VERSION ""

NS_ :

BS_:

BU_: TBox

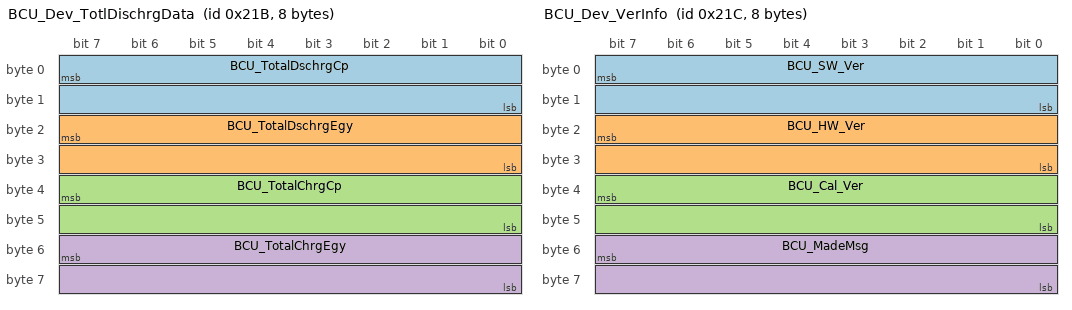
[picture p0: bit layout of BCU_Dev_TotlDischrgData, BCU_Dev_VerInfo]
BO_ 539 BCU_Dev_TotlDischrgData: 8 CGW
 SG_ BCU_TotalDschrgCp : 7|16@0+ (1,0) [0|65000] "" TBox
 SG_ BCU_TotalDschrgEgy : 23|16@0+ (1,0) [0|65000] "" TBox
 SG_ BCU_TotalChrgCp : 39|16@0+ (1,0) [0|65000] "" TBox
 SG_ BCU_TotalChrgEgy : 55|16@0+ (1,0) [0|65000] "" TBox

BO_ 540 BCU_Dev_VerInfo: 8 CGW
 SG_ BCU_SW_Ver : 7|16@0+ (1,0) [0|65535] "" TBox
 SG_ BCU_HW_Ver : 23|16@0+ (1,0) [0|65535] "" TBox
 SG_ BCU_Cal_Ver : 39|16@0+ (1,0) [0|65535] "" TBox
 SG_ BCU_MadeMsg : 55|16@0+ (1,0) [0|65535] "" TBox

BO_ 545 BCU_Extrm_RM: 8 CGW
 SG_ BCU_BattCellTotalNr_RM : 7|8@0+ (1,0) [0|160] "" TBox
 SG_ BCU_TmpProbeQuantity_RM : 15|8@0+ (1,0) [0|160] "" TBox
 SG_ BCU_BalnFlg023_RM : 16|1@0+ (1,0) [0|1] "" TBox
 SG_ BCU_BalnFlg024_RM : 17|1@0+ (1,0) [0|1] "" TBox
 SG_ BCU_BalnFlg025_RM : 18|1@0+ (1,0) [0|1] "" TBox
 SG_ BCU_BalnFlg026_RM : 19|1@0+ (1,0) [0|1] "" TBox
 SG_ BCU_BalnFlg027_RM : 20|1@0+ (1,0) [0|1] "" TBox
 SG_ BCU_BalnFlg028_RM : 21|1@0+ (1,0) [0|1] "" TBox
 SG_ BCU_BalnFlg029_RM : 22|1@0+ (1,0) [0|1] "" TBox
 SG_ BCU_BalnFlg030_RM : 23|1@0+ (1,0) [0|1] "" TBox
 SG_ BCU_BalnFlg031_RM : 24|1@0+ (1,0) [0|1] "" TBox
 SG_ BCU_BalnFlg032_RM : 25|1@0+ (1,0) [0|1] "" TBox
 SG_ BCU_BalnFlg033_RM : 26|1@0+ (1,0) [0|1] "" TBox
 SG_ BCU_BalnFlg034_RM : 27|1@0+ (1,0) [0|1] "" TBox
 SG_ BCU_BalnFlg035_RM : 28|1@0+ (1,0) [0|1] "" TBox
 SG_ BCU_BalnFlg036_RM : 29|1@0+ (1,0) [0|1] "" TBox
 SG_ BCU_BalnFlg037_RM : 30|1@0+ (1,0) [0|1] "" TBox
 SG_ BCU_BalnFlg038_RM : 31|1@0+ (1,0) [0|1] "" TBox
 SG_ BCU_BalnFlg039_RM : 32|1@0+ (1,0) [0|1] "" TBox
 SG_ BCU_BalnFlg040_RM : 33|1@0+ (1,0) [0|1] "" TBox
 SG_ BCU_BalnFlg041_RM : 34|1@0+ (1,0) [0|1] "" TBox
 SG_ BCU_BalnFlg042_RM : 35|1@0+ (1,0) [0|1] "" TBox
 SG_ BCU_BalnFlg043_RM : 36|1@0+ (1,0) [0|1] "" TBox
 SG_ BCU_BalnFlg044_RM : 37|1@0+ (1,0) [0|1] "" TBox
 SG_ BCU_BalnFlg045_RM : 38|1@0+ (1,0) [0|1] "" TBox
 SG_ BCU_BalnFlg046_RM : 39|1@0+ (1,0) [0|1] "" TBox
 SG_ BCU_BalnFlg047_RM : 40|1@0+ (1,0) [0|1] "" TBox
 SG_ BCU_BalnFlg048_RM : 41|1@0+ (1,0) [0|1] "" TBox
 SG_ BCU_BalnFlg049_RM : 42|1@0+ (1,0) [0|1] "" TBox
 SG_ BCU_BalnFlg050_RM : 43|1@0+ (1,0) [0|1] "" TBox
 SG_ BCU_BalnFlg051_RM : 44|1@0+ (1,0) [0|1] "" TBox
 SG_ BCU_BalnFlg052_RM : 45|1@0+ (1,0) [0|1] "" TBox
 SG_ BCU_BalnFlg053_RM : 46|1@0+ (1,0) [0|1] "" TBox
 SG_ BCU_BalnFlg054_RM : 47|1@0+ (1,0) [0|1] "" TBox
 SG_ BCU_BalnFlg055_RM : 48|1@0+ (1,0) [0|1] "" TBox
 SG_ BCU_BalnFlg056_RM : 49|1@0+ (1,0) [0|1] "" TBox
 SG_ BCU_BalnFlg057_RM : 50|1@0+ (1,0) [0|1] "" TBox
 SG_ BCU_BalnFlg058_RM : 51|1@0+ (1,0) [0|1] "" TBox
 SG_ BCU_BalnFlg059_RM : 52|1@0+ (1,0) [0|1] "" TBox
 SG_ BCU_BalnFlg060_RM : 53|1@0+ (1,0) [0|1] "" TBox
 SG_ BCU_BalnFlg061_RM : 54|1@0+ (1,0) [0|1] "" TBox
 SG_ BCU_BalnFlg062_RM : 55|1@0+ (1,0) [0|1] "" TBox
 SG_ BCU_BalnFlg063_RM : 56|1@0+ (1,0) [0|1] "" TBox
 SG_ BCU_BalnFlg064_RM : 57|1@0+ (1,0) [0|1] "" TBox
 SG_ BCU_BalnFlg065_RM : 58|1@0+ (1,0) [0|1] "" TBox
 SG_ BCU_BalnFlg066_RM : 59|1@0+ (1,0) [0|1] "" TBox
 SG_ BCU_BalnFlg067_RM : 60|1@0+ (1,0) [0|1] "" TBox
 SG_ BCU_BalnFlg068_RM : 61|1@0+ (1,0) [0|1] "" TBox
 SG_ BCU_BalnFlg069_RM : 62|1@0+ (1,0) [0|1] "" TBox
 SG_ BCU_BalnFlg070_RM : 63|1@0+ (1,0) [0|1] "" TBox

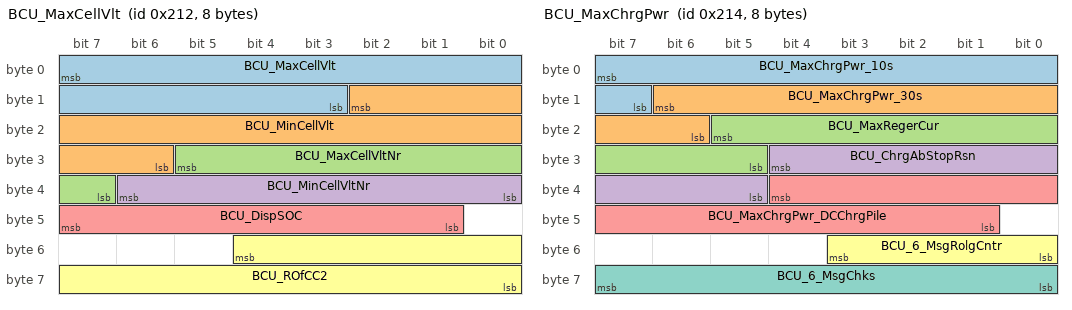
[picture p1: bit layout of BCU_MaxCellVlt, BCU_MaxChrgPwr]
BO_ 530 BCU_MaxCellVlt: 8 CGW
 SG_ BCU_MaxCellVlt : 7|13@0+ (0.001,0) [0|5] "V" TBox
 SG_ BCU_MinCellVlt : 10|13@0+ (0.001,0) [0|5] "V" TBox
 SG_ BCU_MaxCellVltNr : 29|7@0+ (1,0) [0|120] "" TBox
 SG_ BCU_MinCellVltNr : 38|7@0+ (1,0) [0|120] "" TBox
 SG_ BCU_DispSOC : 47|7@0+ (1,0) [0|100] "%" TBox
 SG_ BCU_ROfCC2 : 52|13@0+ (1,0) [0|8191] "Ω" TBox

BO_ 532 BCU_MaxChrgPwr: 8 CGW
 SG_ BCU_MaxChrgPwr_10s : 7|9@0+ (0.5,0) [0|255] "kw" TBox
 SG_ BCU_MaxChrgPwr_30s : 14|9@0+ (0.5,0) [0|255] "kw" TBox
 SG_ BCU_MaxRegerCur : 21|9@0+ (1,0) [0|500] "A" TBox
 SG_ BCU_ChrgAbStopRsn : 28|8@0+ (1,0) [0|255] "" TBox
 SG_ BCU_MaxChrgPwr_DCChrgPile : 36|12@0+ (0.1,0) [0|300] "Kw" TBox
 SG_ BCU_6_MsgRolgCntr : 51|4@0+ (1,0) [0|15] "" TBox
 SG_ BCU_6_MsgChks : 63|8@0+ (1,0) [0|255] "" TBox

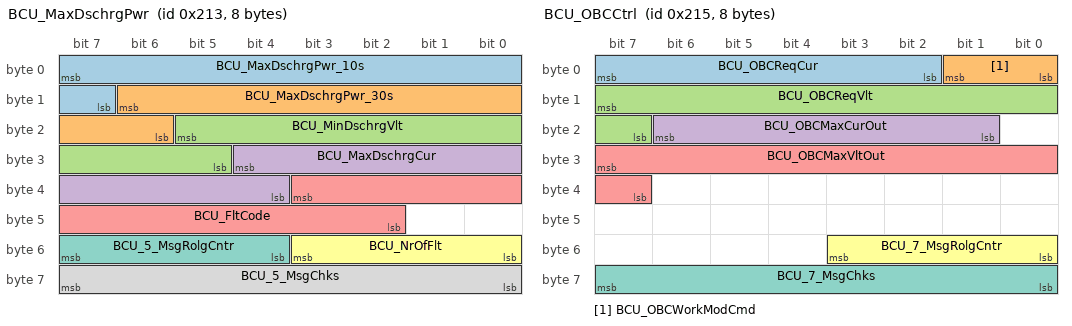
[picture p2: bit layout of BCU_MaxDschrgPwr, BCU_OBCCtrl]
BO_ 531 BCU_MaxDschrgPwr: 8 CGW
 SG_ BCU_MaxDschrgPwr_10s : 7|9@0+ (0.5,0) [0|255] "kw" TBox
 SG_ BCU_MaxDschrgPwr_30s : 14|9@0+ (0.5,0) [0|255] "kw" TBox
 SG_ BCU_MinDschrgVlt : 21|9@0+ (1,0) [0|500] "V" TBox
 SG_ BCU_MaxDschrgCur : 28|9@0+ (1,0) [0|500] "A" TBox
 SG_ BCU_FltCode : 35|10@0+ (1,0) [0|1023] "" TBox
 SG_ BCU_NrOfFlt : 51|4@0+ (1,0) [0|15] "" TBox
 SG_ BCU_5_MsgRolgCntr : 55|4@0+ (1,0) [0|15] "" TBox
 SG_ BCU_5_MsgChks : 63|8@0+ (1,0) [0|255] "" TBox

BO_ 533 BCU_OBCCtrl: 8 CGW
 SG_ BCU_OBCReqCur : 7|6@0+ (1,0) [0|50] "A" TBox
 SG_ BCU_OBCWorkModCmd : 1|2@0+ (1,0) [0|3] "" TBox
 SG_ BCU_OBCReqVlt : 15|9@0+ (1,0) [0|500] "V" TBox
 SG_ BCU_OBCMaxCurOut : 22|6@0+ (1,0) [0|50] "A" TBox
 SG_ BCU_OBCMaxVltOut : 31|9@0+ (1,0) [0|500] "V" TBox
 SG_ BCU_7_MsgRolgCntr : 51|4@0+ (1,0) [0|15] "" TBox
 SG_ BCU_7_MsgChks : 63|8@0+ (1,0) [0|255] "" TBox

BO_ 538 BCU_SglChrgData: 8 CGW
 SG_ BCU_AllCellNr : 7|7@0+ (1,0) [0|120] "" TBox
 SG_ BCU_SglChrgCp : 0|12@0+ (1,0) [0|4000] "" TBox
 SG_ BCU_SglChrgEgy : 20|10@0+ (1,0) [0|1000] "" TBox
 SG_ BCU_SglDschrgCp : 26|12@0+ (1,0) [0|4000] "" TBox
 SG_ BCU_SglDschrgEgy : 46|10@0+ (1,0) [0|1000] "" TBox
 SG_ BCU_BalnFlg001_RM : 52|1@0+ (1,0) [0|1] "" TBox
 SG_ BCU_BalnFlg002_RM : 51|1@0+ (1,0) [0|1] "" TBox
 SG_ BCU_BalnFlg003_RM : 50|1@0+ (1,0) [0|1] "" TBox
 SG_ BCU_BalnFlg004_RM : 49|1@0+ (1,0) [0|1] "" TBox
 SG_ BCU_BalnFlg005_RM : 48|1@0+ (1,0) [0|1] "" TBox
 SG_ BCU_BalnFlg006_RM : 56|1@0+ (1,0) [0|1] "" TBox
 SG_ BCU_BalnFlg007_RM : 57|1@0+ (1,0) [0|1] "" TBox
 SG_ BCU_BalnFlg008_RM : 58|1@0+ (1,0) [0|1] "" TBox
 SG_ BCU_BalnFlg009_RM : 59|1@0+ (1,0) [0|1] "" TBox
 SG_ BCU_BalnFlg010_RM : 60|1@0+ (1,0) [0|1] "" TBox
 SG_ BCU_BalnFlg011_RM : 61|1@0+ (1,0) [0|1] "" TBox
 SG_ BCU_BalnFlg012_RM : 62|1@0+ (1,0) [0|1] "" TBox
 SG_ BCU_BalnFlg013_RM : 63|1@0+ (1,0) [0|1] "" TBox

BO_ 544 BCU_VhclStsExtrm_RM: 8 CGW
 SG_ BCU_IsoR_RM : 7|13@0+ (1,0) [0|8191] "KΩ" TBox
 SG_ BCU_MaxVltBatt_SubSysNr_RM : 10|2@0+ (1,0) [0|3] "" TBox

CM_ SG_ 530 BCU_MaxCellVlt "Max Cell Voltage
最高单体电压";
CM_ SG_ 530 BCU_MinCellVlt "Min Cell Voltage
最低单体电压";
CM_ SG_ 530 BCU_MaxCellVltNr "Max cell voltage number
最高单体电压编号";
CM_ SG_ 530 BCU_MinCellVltNr "Min cell voltage number
最低单体电压编号";
CM_ SG_ 530 BCU_DispSOC "Display SOC
显示的SOC";
CM_ SG_ 530 BCU_ROfCC2 "Resistance of CC2
CC2 电阻";
CM_ SG_ 531 BCU_MaxDschrgPwr_10s "Battery Max Discharge Power During Next 10s
电池10s最大放电功率";
CM_ SG_ 531 BCU_MaxDschrgPwr_30s "Battery Max Discharge  Power During Next 30s
电池30s最大放电功率";
CM_ SG_ 531 BCU_MinDschrgVlt "Battery Min Discharge Voltage
电池最小放电电压";
CM_ SG_ 531 BCU_MaxDschrgCur "Battery Max Discharge Current
电池最大放电电流";
CM_ SG_ 531 BCU_FltCode "Fault Code
故障代码";
CM_ SG_ 531 BCU_NrOfFlt "Number Of Fault
故障数量";
CM_ SG_ 531 BCU_5_MsgRolgCntr "MessageRollingCounter is from 0   
to 15 ,increase one unit on every message transmission
报文计数器";
CM_ SG_ 531 BCU_5_MsgChks "初始值0xFF
异或值0xFF
多项式0x2F
Function : calculate rule
crc = 0xFF;                            // initial value = 0xFF
for( byte_index=0; byte_index<cb_DATA_BYTE_SIZE;    ++byte_index )
{
crc ^= data_byte_array[byte_index];
for( bit_index=0; bit_index<8; ++bit_index )
{
if( (crc & 0x80) != 0 )
crc = (crc << 1) ^ cb_CRC_POLY;
else
crc = (crc << 1);
}
}
return crc= crc ^ 0FF;                            //return inverse value";
CM_ SG_ 532 BCU_MaxChrgPwr_10s "Battery Max Charge Power During Next 10s
电池在接下来10s的最大充电功率";
CM_ SG_ 532 BCU_MaxChrgPwr_30s "Battery Max Charge Power During Next 30s
电池在接下来30s的最大充电功率";
CM_ SG_ 532 BCU_MaxRegerCur "Battery Max Regeneration Current
电池最大回馈电流";
CM_ SG_ 532 BCU_ChrgAbStopRsn "Charge Abnormal Stop Reason 
充电异常停止原因";
CM_ SG_ 532 BCU_MaxChrgPwr_DCChrgPile "Maximum Charging Power of DC Charging Pile
(直流充电时)直流充电桩最大充电功率";
CM_ SG_ 532 BCU_6_MsgRolgCntr "MessageRollingCounter is from 0   
to 15 ,increase one unit on every message transmission
报文计数器";
CM_ SG_ 532 BCU_6_MsgChks "初始值0xFF
异或值0xFF
多项式0x2F
Function : calculate rule
crc = 0xFF;                            // initial value = 0xFF
for( byte_index=0; byte_index<cb_DATA_BYTE_SIZE;    ++byte_index )
{
crc ^= data_byte_array[byte_index];
for( bit_index=0; bit_index<8; ++bit_index )
{
if( (crc & 0x80) != 0 )
crc = (crc << 1) ^ cb_CRC_POLY;
else
crc = (crc << 1);
}
}
return crc= crc ^ 0FF;                            //return inverse value";
CM_ SG_ 533 BCU_OBCReqCur "OBC Request Current
OBC充电请求电流";
CM_ SG_ 533 BCU_OBCWorkModCmd "OBC Work Mode Command
OBC工作模式指令";
CM_ SG_ 533 BCU_OBCReqVlt "OBC Request Voltage
OBC充电请求电压";
CM_ SG_ 533 BCU_OBCMaxCurOut "OBC Max Output Current Limited
OBC输出电流限值";
CM_ SG_ 533 BCU_OBCMaxVltOut "OBC Max Output  Voltage Limited
OBC输出电压限值";
CM_ SG_ 533 BCU_7_MsgRolgCntr "MessageRollingCounter is from 0   
to 15 ,increase one unit on every message transmission
报文计数器";
CM_ SG_ 533 BCU_7_MsgChks "初始值0xFF
异或值0xFF
多项式0x2F
Function : calculate rule
crc = 0xFF;                            // initial value = 0xFF
for( byte_index=0; byte_index<cb_DATA_BYTE_SIZE;    ++byte_index )
{
crc ^= data_byte_array[byte_index];
for( bit_index=0; bit_index<8; ++bit_index )
{
if( (crc & 0x80) != 0 )
crc = (crc << 1) ^ cb_CRC_POLY;
else
crc = (crc << 1);
}
}
return crc= crc ^ 0FF;                            //return inverse value";
CM_ SG_ 538 BCU_AllCellNr "All Cell Number
电池单体编号";
CM_ SG_ 538 BCU_SglChrgCp "Single Charge Capacity
单次外插充电容量";
CM_ SG_ 538 BCU_SglChrgEgy "Single Charge Energy
单次外插充电能量";
CM_ SG_ 538 BCU_SglDschrgCp "Singl Discharge Capacity
单次放电容量";
CM_ SG_ 538 BCU_SglDschrgEgy "Single Discharge Energy
单次放电能量";
CM_ SG_ 538 BCU_BalnFlg001_RM "Cell Balance Flag
单体均衡标志位001";
CM_ SG_ 538 BCU_BalnFlg002_RM "Cell Balance Flag
单体均衡标志位002";
CM_ SG_ 538 BCU_BalnFlg003_RM "Cell Balance Flag
单体均衡标志位003";
CM_ SG_ 538 BCU_BalnFlg004_RM "Cell Balance Flag
单体均衡标志位004";
CM_ SG_ 538 BCU_BalnFlg005_RM "Cell Balance Flag
单体均衡标志位005";
CM_ SG_ 538 BCU_BalnFlg006_RM "Cell Balance Flag
单体均衡标志位006";
CM_ SG_ 538 BCU_BalnFlg007_RM "Cell Balance Flag
单体均衡标志位007";
CM_ SG_ 538 BCU_BalnFlg008_RM "Cell Balance Flag
单体均衡标志位008";
CM_ SG_ 538 BCU_BalnFlg009_RM "Cell Balance Flag
单体均衡标志位009";
CM_ SG_ 538 BCU_BalnFlg010_RM "Cell Balance Flag
单体均衡标志位010";
CM_ SG_ 538 BCU_BalnFlg011_RM "Cell Balance Flag
单体均衡标志位011";
CM_ SG_ 538 BCU_BalnFlg012_RM "Cell Balance Flag
单体均衡标志位012";
CM_ SG_ 538 BCU_BalnFlg013_RM "Cell Balance Flag
单体均衡标志位013";
CM_ SG_ 539 BCU_TotalDschrgCp "Total Discharge Capacity
累计放电容量";
CM_ SG_ 539 BCU_TotalDschrgEgy "Total Discharge Energy
累计放电能量";
CM_ SG_ 539 BCU_TotalChrgCp "Total Charge Capacity
累计充电容量";
CM_ SG_ 539 BCU_TotalChrgEgy "Total Charge Cnergy
累计充电能量";
CM_ SG_ 540 BCU_SW_Ver "Software Version
软件集成版本号";
CM_ SG_ 540 BCU_HW_Ver "Hardware Version
硬件版本号";
CM_ SG_ 540 BCU_Cal_Ver "Calibration Version
标定版本号";
CM_ SG_ 540 BCU_MadeMsg "Made Message
制造信息";
CM_ SG_ 544 BCU_IsoR_RM "Isolation Resistance
绝缘电阻";
CM_ SG_ 544 BCU_MaxVltBatt_SubSysNr_RM "Battery subsysterm number of max cell voltage
电压最大单体对应的电池子系统编号";
CM_ SG_ 545 BCU_BattCellTotalNr_RM "Battery Cell total number
电池包电池单体总数";
CM_ SG_ 545 BCU_TmpProbeQuantity_RM "quantity of temperature probe
可充电储能温度探针个数";
CM_ SG_ 545 BCU_BalnFlg023_RM "Cell Balance Flag
单体均衡标志位023";
CM_ SG_ 545 BCU_BalnFlg024_RM "Cell Balance Flag
单体均衡标志位024";
CM_ SG_ 545 BCU_BalnFlg025_RM "Cell Balance Flag
单体均衡标志位025";
CM_ SG_ 545 BCU_BalnFlg026_RM "Cell Balance Flag
单体均衡标志位026";
CM_ SG_ 545 BCU_BalnFlg027_RM "Cell Balance Flag
单体均衡标志位027";
CM_ SG_ 545 BCU_BalnFlg028_RM "Cell Balance Flag
单体均衡标志位028";
CM_ SG_ 545 BCU_BalnFlg029_RM "Cell Balance Flag
单体均衡标志位029";
CM_ SG_ 545 BCU_BalnFlg030_RM "Cell Balance Flag
单体均衡标志位030";
CM_ SG_ 545 BCU_BalnFlg031_RM "Cell Balance Flag
单体均衡标志位031";
CM_ SG_ 545 BCU_BalnFlg032_RM "Cell Balance Flag
单体均衡标志位032";
CM_ SG_ 545 BCU_BalnFlg033_RM "Cell Balance Flag
单体均衡标志位033";
CM_ SG_ 545 BCU_BalnFlg034_RM "Cell Balance Flag
单体均衡标志位034";
CM_ SG_ 545 BCU_BalnFlg035_RM "Cell Balance Flag
单体均衡标志位035";
CM_ SG_ 545 BCU_BalnFlg036_RM "Cell Balance Flag
单体均衡标志位036";
CM_ SG_ 545 BCU_BalnFlg037_RM "Cell Balance Flag
单体均衡标志位037";
CM_ SG_ 545 BCU_BalnFlg038_RM "Cell Balance Flag
单体均衡标志位038";
CM_ SG_ 545 BCU_BalnFlg039_RM "Cell Balance Flag
单体均衡标志位039";
CM_ SG_ 545 BCU_BalnFlg040_RM "Cell Balance Flag
单体均衡标志位040";
CM_ SG_ 545 BCU_BalnFlg041_RM "Cell Balance Flag
单体均衡标志位041";
CM_ SG_ 545 BCU_BalnFlg042_RM "Cell Balance Flag
单体均衡标志位042";
CM_ SG_ 545 BCU_BalnFlg043_RM "Cell Balance Flag
单体均衡标志位043";
CM_ SG_ 545 BCU_BalnFlg044_RM "Cell Balance Flag
单体均衡标志位044";
CM_ SG_ 545 BCU_BalnFlg045_RM "Cell Balance Flag
单体均衡标志位045";
CM_ SG_ 545 BCU_BalnFlg046_RM "Cell Balance Flag
单体均衡标志位046";
CM_ SG_ 545 BCU_BalnFlg047_RM "Cell Balance Flag
单体均衡标志位047";
CM_ SG_ 545 BCU_BalnFlg048_RM "Cell Balance Flag
单体均衡标志位048";
CM_ SG_ 545 BCU_BalnFlg049_RM "Cell Balance Flag
单体均衡标志位049";
CM_ SG_ 545 BCU_BalnFlg050_RM "Cell Balance Flag
单体均衡标志位050";
CM_ SG_ 545 BCU_BalnFlg051_RM "Cell Balance Flag
单体均衡标志位051";
CM_ SG_ 545 BCU_BalnFlg052_RM "Cell Balance Flag
单体均衡标志位052";
CM_ SG_ 545 BCU_BalnFlg053_RM "Cell Balance Flag
单体均衡标志位053";
CM_ SG_ 545 BCU_BalnFlg054_RM "Cell Balance Flag
单体均衡标志位054";
CM_ SG_ 545 BCU_BalnFlg055_RM "Cell Balance Flag
单体均衡标志位055";
CM_ SG_ 545 BCU_BalnFlg056_RM "Cell Balance Flag
单体均衡标志位056";
CM_ SG_ 545 BCU_BalnFlg057_RM "Cell Balance Flag
单体均衡标志位057";
CM_ SG_ 545 BCU_BalnFlg058_RM "Cell Balance Flag
单体均衡标志位058";
CM_ SG_ 545 BCU_BalnFlg059_RM "Cell Balance Flag
单体均衡标志位059";
CM_ SG_ 545 BCU_BalnFlg060_RM "Cell Balance Flag
单体均衡标志位060";
CM_ SG_ 545 BCU_BalnFlg061_RM "Cell Balance Flag
单体均衡标志位061";
CM_ SG_ 545 BCU_BalnFlg062_RM "Cell Balance Flag
单体均衡标志位062";
CM_ SG_ 545 BCU_BalnFlg063_RM "Cell Balance Flag
单体均衡标志位063";
CM_ SG_ 545 BCU_BalnFlg064_RM "Cell Balance Flag
单体均衡标志位064";
CM_ SG_ 545 BCU_BalnFlg065_RM "Cell Balance Flag
单体均衡标志位065";
CM_ SG_ 545 BCU_BalnFlg066_RM "Cell Balance Flag
单体均衡标志位066";
CM_ SG_ 545 BCU_BalnFlg067_RM "Cell Balance Flag
单体均衡标志位067";
CM_ SG_ 545 BCU_BalnFlg068_RM "Cell Balance Flag
单体均衡标志位068";
CM_ SG_ 545 BCU_BalnFlg069_RM "Cell Balance Flag
单体均衡标志位069";
CM_ SG_ 545 BCU_BalnFlg070_RM "Cell Balance Flag
单体均衡标志位070";

BA_DEF_ BO_  "NmMessage" ENUM "No","Yes";
BA_DEF_ BO_  "GenMsgSendType" ENUM  "Cycle","CA","CE","Event","NotUsed","NotUsed","NotUsed","IfActive","NoMsgSendType","NotUsed";
BA_DEF_ BO_  "GenMsgCycleTime" INT 0 0;
BA_DEF_ SG_  "GenSigSendType" ENUM  "Cycle","OnChange","OnWrite","IfActive","OnChangeWithRepetition","OnWriteWithRepetition","IfActiveWithRepetition";
BA_DEF_ SG_  "GenSigStartValue" INT 0 0;
BA_DEF_ BO_  "GenMsgCycleTimeFast" INT 0 0;
BA_DEF_ BO_  "GenMsgNrOfRepetition" INT 0 0;
BA_DEF_ BO_  "GenMsgDelayTime" INT 0 0;
BA_DEF_ BO_  "VFrameFormat" ENUM  "StandardCAN","ExtendedCAN","reserved","reserved","reserved","reserved","reserved","reserved","reserved","reserved","reserved","reserved","reserved","reserved","StandardCAN_FD","ExtendedCAN_FD";
BA_DEF_ BO_  "GenMsgCycleTimeActive" INT 0 500;
BA_DEF_ BO_  "GenMsgStartDelayTime" INT 0 500;

BA_DEF_DEF_  "NmMessage" "No";
BA_DEF_DEF_  "GenMsgSendType" "Cycle";
BA_DEF_DEF_  "GenMsgCycleTime" 0;
BA_DEF_DEF_  "GenSigSendType" "Cycle";
BA_DEF_DEF_  "GenSigStartValue" 0;
BA_DEF_DEF_  "GenMsgCycleTimeFast" 0;
BA_DEF_DEF_  "GenMsgNrOfRepetition" 0;
BA_DEF_DEF_  "GenMsgDelayTime" 0;
BA_DEF_DEF_  "VFrameFormat" "StandardCAN";
BA_DEF_DEF_  "GenMsgCycleTimeActive" 100;
BA_DEF_DEF_  "GenMsgStartDelayTime" 200;
BA_ "GenMsgCycleTime" BO_ 539 1000;
BA_ "GenMsgCycleTime" BO_ 540 1000;
BA_ "GenMsgCycleTime" BO_ 545 1000;
BA_ "GenMsgCycleTime" BO_ 530 50;
BA_ "GenMsgCycleTime" BO_ 532 10;
BA_ "GenMsgCycleTime" BO_ 531 10;
BA_ "GenMsgCycleTime" BO_ 533 100;
BA_ "GenMsgCycleTime" BO_ 538 1000;
BA_ "GenMsgCycleTime" BO_ 544 1000;
VAL_ 530 BCU_MaxCellVlt 8191 "Invalid" 8190 "Invalid" 8189 "Invalid" 8188 "Invalid" 8187 "Invalid" 8186 "Invalid" 8185 "Invalid" 8184 "Invalid" 8183 "Invalid" 8182 "Invalid" 8181 "Invalid" 8180 "Invalid" 8179 "Invalid" 8178 "Invalid" 8177 "Invalid" 8176 "Invalid" 8175 "Invalid" 8174 "Invalid" 8173 "Invalid" 8172 "Invalid" 8171 "Invalid" 8170 "Invalid" 8169 "Invalid" 8168 "Invalid" 8167 "Invalid" 8166 "Invalid" 8165 "Invalid" 8164 "Invalid" 8163 "Invalid" 8162 "Invalid" 8161 "Invalid" 8160 "Invalid" 8159 "Invalid" 8158 "Invalid" 8157 "Invalid" 8156 "Invalid" 8155 "Invalid" 8154 "Invalid" 8153 "Invalid" 8152 "Invalid" 8151 "Invalid" 8150 "Invalid" 8149 "Invalid" 8148 "Invalid" 8147 "Invalid" 8146 "Invalid" 8145 "Invalid" 8144 "Invalid" 8143 "Invalid" 8142 "Invalid" 8141 "Invalid" 8140 "Invalid" 8139 "Invalid" 8138 "Invalid" 8137 "Invalid" 8136 "Invalid" 8135 "Invalid" 8134 "Invalid" 8133 "Invalid" 8132 "Invalid" 8131 "Invalid" 8130 "Invalid" 8129 "Invalid" 8128 "Invalid" 8127 "Invalid" 8126 "Invalid" 8125 "Invalid" 8124 "Invalid" 8123 "Invalid" 8122 "Invalid" 8121 "Invalid" 8120 "Invalid" 8119 "Invalid" 8118 "Invalid" 8117 "Invalid" 8116 "Invalid" 8115 "Invalid" 8114 "Invalid" 8113 "Invalid" 8112 "Invalid" 8111 "Invalid" 8110 "Invalid" 8109 "Invalid" 8108 "Invalid" 8107 "Invalid" 8106 "Invalid" 8105 "Invalid" 8104 "Invalid" 8103 "Invalid" 8102 "Invalid" 8101 "Invalid" 8100 "Invalid" 8099 "Invalid" 8098 "Invalid" 8097 "Invalid" 8096 "Invalid" 8095 "Invalid" 8094 "Invalid" 8093 "Invalid" 8092 "Invalid" 8091 "Invalid" 8090 "Invalid" 8089 "Invalid" 8088 "Invalid" 8087 "Invalid" 8086 "Invalid" 8085 "Invalid" 8084 "Invalid" 8083 "Invalid" 8082 "Invalid" 8081 "Invalid" 8080 "Invalid" 8079 "Invalid" 8078 "Invalid" 8077 "Invalid" 8076 "Invalid" 8075 "Invalid" 8074 "Invalid" 8073 "Invalid" 8072 "Invalid" 8071 "Invalid" 8070 "Invalid" 8069 "Invalid" 8068 "Invalid" 8067 "Invalid" 8066 "Invalid" 8065 "Invalid" 8064 "Invalid" 8063 "Invalid" 8062 "Invalid" 8061 "Invalid" 8060 "Invalid" 8059 "Invalid" 8058 "Invalid" 8057 "Invalid" 8056 "Invalid" 8055 "Invalid" 8054 "Invalid" 8053 "Invalid" 8052 "Invalid" 8051 "Invalid" 8050 "Invalid" 8049 "Invalid" 8048 "Invalid" 8047 "Invalid" 8046 "Invalid" 8045 "Invalid" 8044 "Invalid" 8043 "Invalid" 8042 "Invalid" 8041 "Invalid" 8040 "Invalid" 8039 "Invalid" 8038 "Invalid" 8037 "Invalid" 8036 "Invalid" 8035 "Invalid" 8034 "Invalid" 8033 "Invalid" 8032 "Invalid" 8031 "Invalid" 8030 "Invalid" 8029 "Invalid" 8028 "Invalid" 8027 "Invalid" 8026 "Invalid" 8025 "Invalid" 8024 "Invalid" 8023 "Invalid" 8022 "Invalid" 8021 "Invalid" 8020 "Invalid" 8019 "Invalid" 8018 "Invalid" 8017 "Invalid" 8016 "Invalid" 8015 "Invalid" 8014 "Invalid" 8013 "Invalid" 8012 "Invalid" 8011 "Invalid" 8010 "Invalid" 8009 "Invalid" 8008 "Invalid" 8007 "Invalid" 8006 "Invalid" 8005 "Invalid" 8004 "Invalid" 8003 "Invalid" 8002 "Invalid" 8001 "Invalid" 8000 "Invalid" 7999 "Invalid" 7998 "Invalid" 7997 "Invalid" 7996 "Invalid" 7995 "Invalid" 7994 "Invalid" 7993 "Invalid" 7992 "Invalid" 7991 "Invalid" 7990 "Invalid" 7989 "Invalid" 7988 "Invalid" 7987 "Invalid" 7986 "Invalid" 7985 "Invalid" 7984 "Invalid" 7983 "Invalid" 7982 "Invalid" 7981 "Invalid" 7980 "Invalid" 7979 "Invalid" 7978 "Invalid" 7977 "Invalid" 7976 "Invalid" 7975 "Invalid" 7974 "Invalid" 7973 "Invalid" 7972 "Invalid" 7971 "Invalid" 7970 "Invalid" 7969 "Invalid" 7968 "Invalid" 7967 "Invalid" 7966 "Invalid" 7965 "Invalid" 7964 "Invalid" 7963 "Invalid" 7962 "Invalid" 7961 "Invalid" 7960 "Invalid" 7959 "Invalid" 7958 "Invalid" 7957 "Invalid" 7956 "Invalid" 7955 "Invalid" 7954 "Invalid" 7953 "Invalid" 7952 "Invalid" 7951 "Invalid" 7950 "Invalid" 7949 "Invalid" 7948 "Invalid" 7947 "Invalid" 7946 "Invalid" 7945 "Invalid" 7944 "Invalid" 7943 "Invalid" 7942 "Invalid" 7941 "Invalid" 7940 "Invalid" 7939 "Invalid" 7938 "Invalid" 7937 "Invalid" 7936 "Invalid" 7935 "Invalid" 7934 "Invalid" 7933 "Invalid" 7932 "Invalid" 7931 "Invalid" 7930 "Invalid" 7929 "Invalid" 7928 "Invalid" 7927 "Invalid" 7926 "Invalid" 7925 "Invalid" 7924 "Invalid" 7923 "Invalid" 7922 "Invalid" 7921 "Invalid" 7920 "Invalid" 7919 "Invalid" 7918 "Invalid" 7917 "Invalid" 7916 "Invalid" 7915 "Invalid" 7914 "Invalid" 7913 "Invalid" 7912 "Invalid" 7911 "Invalid" 7910 "Invalid" 7909 "Invalid" 7908 "Invalid" 7907 "Invalid" 7906 "Invalid" 7905 "Invalid" 7904 "Invalid" 7903 "Invalid" 7902 "Invalid" 7901 "Invalid" 7900 "Invalid" 7899 "Invalid" 7898 "Invalid" 7897 "Invalid" 7896 "Invalid" 7895 "Invalid" 7894 "Invalid" 7893 "Invalid" 7892 "Invalid" 7891 "Invalid" 7890 "Invalid" 7889 "Invalid" 7888 "Invalid" 7887 "Invalid" 7886 "Invalid" 7885 "Invalid" 7884 "Invalid" 7883 "Invalid" 7882 "Invalid" 7881 "Invalid" 7880 "Invalid" 7879 "Invalid" 7878 "Invalid" 7877 "Invalid" 7876 "Invalid" 7875 "Invalid" 7874 "Invalid" 7873 "Invalid" 7872 "Invalid" 7871 "Invalid" 7870 "Invalid" 7869 "Invalid" 7868 "Invalid" 7867 "Invalid" 7866 "Invalid" 7865 "Invalid" 7864 "Invalid" 7863 "Invalid" 7862 "Invalid" 7861 "Invalid" 7860 "Invalid" 7859 "Invalid" 7858 "Invalid" 7857 "Invalid" 7856 "Invalid" 7855 "Invalid" 7854 "Invalid" 7853 "Invalid" 7852 "Invalid" 7851 "Invalid" 7850 "Invalid" 7849 "Invalid" 7848 "Invalid" 7847 "Invalid" 7846 "Invalid" 7845 "Invalid" 7844 "Invalid" 7843 "Invalid" 7842 "Invalid" 7841 "Invalid" 7840 "Invalid" 7839 "Invalid" 7838 "Invalid" 7837 "Invalid" 7836 "Invalid" 7835 "Invalid" 7834 "Invalid" 7833 "Invalid" 7832 "Invalid" 7831 "Invalid" 7830 "Invalid" 7829 "Invalid" 7828 "Invalid" 7827 "Invalid" 7826 "Invalid" 7825 "Invalid" 7824 "Invalid" 7823 "Invalid" 7822 "Invalid" 7821 "Invalid" 7820 "Invalid" 7819 "Invalid" 7818 "Invalid" 7817 "Invalid" 7816 "Invalid" 7815 "Invalid" 7814 "Invalid" 7813 "Invalid" 7812 "Invalid" 7811 "Invalid" 7810 "Invalid" 7809 "Invalid" 7808 "Invalid" 7807 "Invalid" 7806 "Invalid" 7805 "Invalid" 7804 "Invalid" 7803 "Invalid" 7802 "Invalid" 7801 "Invalid" 7800 "Invalid" 7799 "Invalid" 7798 "Invalid" 7797 "Invalid" 7796 "Invalid" 7795 "Invalid" 7794 "Invalid" 7793 "Invalid" 7792 "Invalid" 7791 "Invalid" 7790 "Invalid" 7789 "Invalid" 7788 "Invalid" 7787 "Invalid" 7786 "Invalid" 7785 "Invalid" 7784 "Invalid" 7783 "Invalid" 7782 "Invalid" 7781 "Invalid" 7780 "Invalid" 7779 "Invalid" 7778 "Invalid" 7777 "Invalid" 7776 "Invalid" 7775 "Invalid" 7774 "Invalid" 7773 "Invalid" 7772 "Invalid" 7771 "Invalid" 7770 "Invalid" 7769 "Invalid" 7768 "Invalid" 7767 "Invalid" 7766 "Invalid" 7765 "Invalid" 7764 "Invalid" 7763 "Invalid" 7762 "Invalid" 7761 "Invalid" 7760 "Invalid" 7759 "Invalid" 7758 "Invalid" 7757 "Invalid" 7756 "Invalid" 7755 "Invalid" 7754 "Invalid" 7753 "Invalid" 7752 "Invalid" 7751 "Invalid" 7750 "Invalid" 7749 "Invalid" 7748 "Invalid" 7747 "Invalid" 7746 "Invalid" 7745 "Invalid" 7744 "Invalid" 7743 "Invalid" 7742 "Invalid" 7741 "Invalid" 7740 "Invalid" 7739 "Invalid" 7738 "Invalid" 7737 "Invalid" 7736 "Invalid" 7735 "Invalid" 7734 "Invalid" 7733 "Invalid" 7732 "Invalid" 7731 "Invalid" 7730 "Invalid" 7729 "Invalid" 7728 "Invalid" 7727 "Invalid" 7726 "Invalid" 7725 "Invalid" 7724 "Invalid" 7723 "Invalid" 7722 "Invalid" 7721 "Invalid" 7720 "Invalid" 7719 "Invalid" 7718 "Invalid" 7717 "Invalid" 7716 "Invalid" 7715 "Invalid" 7714 "Invalid" 7713 "Invalid" 7712 "Invalid" 7711 "Invalid" 7710 "Invalid" 7709 "Invalid" 7708 "Invalid" 7707 "Invalid" 7706 "Invalid" 7705 "Invalid" 7704 "Invalid" 7703 "Invalid" 7702 "Invalid" 7701 "Invalid" 7700 "Invalid" 7699 "Invalid" 7698 "Invalid" 7697 "Invalid" 7696 "Invalid" 7695 "Invalid" 7694 "Invalid" 7693 "Invalid" 7692 "Invalid" 7691 "Invalid" 7690 "Invalid" 7689 "Invalid" 7688 "Invalid" 7687 "Invalid" 7686 "Invalid" 7685 "Invalid" 7684 "Invalid" 7683 "Invalid" 7682 "Invalid" 7681 "Invalid" 7680 "Invalid" 7679 "Invalid" 7678 "Invalid" 7677 "Invalid" 7676 "Invalid" 7675 "Invalid" 7674 "Invalid" 7673 "Invalid" 7672 "Invalid" 7671 "Invalid" 7670 "Invalid" 7669 "Invalid" 7668 "Invalid" 7667 "Invalid" 7666 "Invalid" 7665 "Invalid" 7664 "Invalid" 7663 "Invalid" 7662 "Invalid" 7661 "Invalid" 7660 "Invalid" 7659 "Invalid" 7658 "Invalid" 7657 "Invalid" 7656 "Invalid" 7655 "Invalid" 7654 "Invalid" 7653 "Invalid" 7652 "Invalid" 7651 "Invalid" 7650 "Invalid" 7649 "Invalid" 7648 "Invalid" 7647 "Invalid" 7646 "Invalid" 7645 "Invalid" 7644 "Invalid" 7643 "Invalid" 7642 "Invalid" 7641 "Invalid" 7640 "Invalid" 7639 "Invalid" 7638 "Invalid" 7637 "Invalid" 7636 "Invalid" 7635 "Invalid" 7634 "Invalid" 7633 "Invalid" 7632 "Invalid" 7631 "Invalid" 7630 "Invalid" 7629 "Invalid" 7628 "Invalid" 7627 "Invalid" 7626 "Invalid" 7625 "Invalid" 7624 "Invalid" 7623 "Invalid" 7622 "Invalid" 7621 "Invalid" 7620 "Invalid" 7619 "Invalid" 7618 "Invalid" 7617 "Invalid" 7616 "Invalid" 7615 "Invalid" 7614 "Invalid" 7613 "Invalid" 7612 "Invalid" 7611 "Invalid" 7610 "Invalid" 7609 "Invalid" 7608 "Invalid" 7607 "Invalid" 7606 "Invalid" 7605 "Invalid" 7604 "Invalid" 7603 "Invalid" 7602 "Invalid" 7601 "Invalid" 7600 "Invalid" 7599 "Invalid" 7598 "Invalid" 7597 "Invalid" 7596 "Invalid" 7595 "Invalid" 7594 "Invalid" 7593 "Invalid" 7592 "Invalid" 7591 "Invalid" 7590 "Invalid" 7589 "Invalid" 7588 "Invalid" 7587 "Invalid" 7586 "Invalid" 7585 "Invalid" 7584 "Invalid" 7583 "Invalid" 7582 "Invalid" 7581 "Invalid" 7580 "Invalid" 7579 "Invalid" 7578 "Invalid" 7577 "Invalid" 7576 "Invalid" 7575 "Invalid" 7574 "Invalid" 7573 "Invalid" 7572 "Invalid" 7571 "Invalid" 7570 "Invalid" 7569 "Invalid" 7568 "Invalid" 7567 "Invalid" 7566 "Invalid" 7565 "Invalid" 7564 "Invalid" 7563 "Invalid" 7562 "Invalid" 7561 "Invalid" 7560 "Invalid" 7559 "Invalid" 7558 "Invalid" 7557 "Invalid" 7556 "Invalid" 7555 "Invalid" 7554 "Invalid" 7553 "Invalid" 7552 "Invalid" 7551 "Invalid" 7550 "Invalid" 7549 "Invalid" 7548 "Invalid" 7547 "Invalid" 7546 "Invalid" 7545 "Invalid" 7544 "Invalid" 7543 "Invalid" 7542 "Invalid" 7541 "Invalid" 7540 "Invalid" 7539 "Invalid" 7538 "Invalid" 7537 "Invalid" 7536 "Invalid" 7535 "Invalid" 7534 "Invalid" 7533 "Invalid" 7532 "Invalid" 7531 "Invalid" 7530 "Invalid" 7529 "Invalid" 7528 "Invalid" 7527 "Invalid" 7526 "Invalid" 7525 "Invalid" 7524 "Invalid" 7523 "Invalid" 7522 "Invalid" 7521 "Invalid" 7520 "Invalid" 7519 "Invalid" 7518 "Invalid" 7517 "Invalid" 7516 "Invalid" 7515 "Invalid" 7514 "Invalid" 7513 "Invalid" 7512 "Invalid" 7511 "Invalid" 7510 "Invalid" 7509 "Invalid" 7508 "Invalid" 7507 "Invalid" 7506 "Invalid" 7505 "Invalid" 7504 "Invalid" 7503 "Invalid" 7502 "Invalid" 7501 "Invalid" 7500 "Invalid" 7499 "Invalid" 7498 "Invalid" 7497 "Invalid" 7496 "Invalid" 7495 "Invalid" 7494 "Invalid" 7493 "Invalid" 7492 "Invalid" 7491 "Invalid" 7490 "Invalid" 7489 "Invalid" 7488 "Invalid" 7487 "Invalid" 7486 "Invalid" 7485 "Invalid" 7484 "Invalid" 7483 "Invalid" 7482 "Invalid" 7481 "Invalid" 7480 "Invalid" 7479 "Invalid" 7478 "Invalid" 7477 "Invalid" 7476 "Invalid" 7475 "Invalid" 7474 "Invalid" 7473 "Invalid" 7472 "Invalid" 7471 "Invalid" 7470 "Invalid" 7469 "Invalid" 7468 "Invalid" 7467 "Invalid" 7466 "Invalid" 7465 "Invalid" 7464 "Invalid" 7463 "Invalid" 7462 "Invalid" 7461 "Invalid" 7460 "Invalid" 7459 "Invalid" 7458 "Invalid" 7457 "Invalid" 7456 "Invalid" 7455 "Invalid" 7454 "Invalid" 7453 "Invalid" 7452 "Invalid" 7451 "Invalid" 7450 "Invalid" 7449 "Invalid" 7448 "Invalid" 7447 "Invalid" 7446 "Invalid" 7445 "Invalid" 7444 "Invalid" 7443 "Invalid" 7442 "Invalid" 7441 "Invalid" 7440 "Invalid" 7439 "Invalid" 7438 "Invalid" 7437 "Invalid" 7436 "Invalid" 7435 "Invalid" 7434 "Invalid" 7433 "Invalid" 7432 "Invalid" 7431 "Invalid" 7430 "Invalid" 7429 "Invalid" 7428 "Invalid" 7427 "Invalid" 7426 "Invalid" 7425 "Invalid" 7424 "Invalid" 7423 "Invalid" 7422 "Invalid" 7421 "Invalid" 7420 "Invalid" 7419 "Invalid" 7418 "Invalid" 7417 "Invalid" 7416 "Invalid" 7415 "Invalid" 7414 "Invalid" 7413 "Invalid" 7412 "Invalid" 7411 "Invalid" 7410 "Invalid" 7409 "Invalid" 7408 "Invalid" 7407 "Invalid" 7406 "Invalid" 7405 "Invalid" 7404 "Invalid" 7403 "Invalid" 7402 "Invalid" 7401 "Invalid" 7400 "Invalid" 7399 "Invalid" 7398 "Invalid" 7397 "Invalid" 7396 "Invalid" 7395 "Invalid" 7394 "Invalid" 7393 "Invalid" 7392 "Invalid" 7391 "Invalid" 7390 "Invalid" 7389 "Invalid" 7388 "Invalid" 7387 "Invalid" 7386 "Invalid" 7385 "Invalid" 7384 "Invalid" 7383 "Invalid" 7382 "Invalid" 7381 "Invalid" 7380 "Invalid" 7379 "Invalid" 7378 "Invalid" 7377 "Invalid" 7376 "Invalid" 7375 "Invalid" 7374 "Invalid" 7373 "Invalid" 7372 "Invalid" 7371 "Invalid" 7370 "Invalid" 7369 "Invalid" 7368 "Invalid" 7367 "Invalid" 7366 "Invalid" 7365 "Invalid" 7364 "Invalid" 7363 "Invalid" 7362 "Invalid" 7361 "Invalid" 7360 "Invalid" 7359 "Invalid" 7358 "Invalid" 7357 "Invalid" 7356 "Invalid" 7355 "Invalid" 7354 "Invalid" 7353 "Invalid" 7352 "Invalid" 7351 "Invalid" 7350 "Invalid" 7349 "Invalid" 7348 "Invalid" 7347 "Invalid" 7346 "Invalid" 7345 "Invalid" 7344 "Invalid" 7343 "Invalid" 7342 "Invalid" 7341 "Invalid" 7340 "Invalid" 7339 "Invalid" 7338 "Invalid" 7337 "Invalid" 7336 "Invalid" 7335 "Invalid" 7334 "Invalid" 7333 "Invalid" 7332 "Invalid" 7331 "Invalid" 7330 "Invalid" 7329 "Invalid" 7328 "Invalid" 7327 "Invalid" 7326 "Invalid" 7325 "Invalid" 7324 "Invalid" 7323 "Invalid" 7322 "Invalid" 7321 "Invalid" 7320 "Invalid" 7319 "Invalid" 7318 "Invalid" 7317 "Invalid" 7316 "Invalid" 7315 "Invalid" 7314 "Invalid" 7313 "Invalid" 7312 "Invalid" 7311 "Invalid" 7310 "Invalid" 7309 "Invalid" 7308 "Invalid" 7307 "Invalid" 7306 "Invalid" 7305 "Invalid" 7304 "Invalid" 7303 "Invalid" 7302 "Invalid" 7301 "Invalid" 7300 "Invalid" 7299 "Invalid" 7298 "Invalid" 7297 "Invalid" 7296 "Invalid" 7295 "Invalid" 7294 "Invalid" 7293 "Invalid" 7292 "Invalid" 7291 "Invalid" 7290 "Invalid" 7289 "Invalid" 7288 "Invalid" 7287 "Invalid" 7286 "Invalid" 7285 "Invalid" 7284 "Invalid" 7283 "Invalid" 7282 "Invalid" 7281 "Invalid" 7280 "Invalid" 7279 "Invalid" 7278 "Invalid" 7277 "Invalid" 7276 "Invalid" 7275 "Invalid" 7274 "Invalid" 7273 "Invalid" 7272 "Invalid" 7271 "Invalid" 7270 "Invalid" 7269 "Invalid" 7268 "Invalid" 7267 "Invalid" 7266 "Invalid" 7265 "Invalid" 7264 "Invalid" 7263 "Invalid" 7262 "Invalid" 7261 "Invalid" 7260 "Invalid" 7259 "Invalid" 7258 "Invalid" 7257 "Invalid" 7256 "Invalid" 7255 "Invalid" 7254 "Invalid" 7253 "Invalid" 7252 "Invalid" 7251 "Invalid" 7250 "Invalid" 7249 "Invalid" 7248 "Invalid" 7247 "Invalid" 7246 "Invalid" 7245 "Invalid" 7244 "Invalid" 7243 "Invalid" 7242 "Invalid" 7241 "Invalid" 7240 "Invalid" 7239 "Invalid" 7238 "Invalid" 7237 "Invalid" 7236 "Invalid" 7235 "Invalid" 7234 "Invalid" 7233 "Invalid" 7232 "Invalid" 7231 "Invalid" 7230 "Invalid" 7229 "Invalid" 7228 "Invalid" 7227 "Invalid" 7226 "Invalid" 7225 "Invalid" 7224 "Invalid" 7223 "Invalid" 7222 "Invalid" 7221 "Invalid" 7220 "Invalid" 7219 "Invalid" 7218 "Invalid" 7217 "Invalid" 7216 "Invalid" 7215 "Invalid" 7214 "Invalid" 7213 "Invalid" 7212 "Invalid" 7211 "Invalid" 7210 "Invalid" 7209 "Invalid" 7208 "Invalid" 7207 "Invalid" 7206 "Invalid" 7205 "Invalid" 7204 "Invalid" 7203 "Invalid" 7202 "Invalid" 7201 "Invalid" 7200 "Invalid" 7199 "Invalid" 7198 "Invalid" 7197 "Invalid" 7196 "Invalid" 7195 "Invalid" 7194 "Invalid" 7193 "Invalid" 7192 "Invalid" 7191 "Invalid" 7190 "Invalid" 7189 "Invalid" 7188 "Invalid" 7187 "Invalid" 7186 "Invalid" 7185 "Invalid" 7184 "Invalid" 7183 "Invalid" 7182 "Invalid" 7181 "Invalid" 7180 "Invalid" 7179 "Invalid" 7178 "Invalid" 7177 "Invalid" 7176 "Invalid" 7175 "Invalid" 7174 "Invalid" 7173 "Invalid" 7172 "Invalid" 7171 "Invalid" 7170 "Invalid" 7169 "Invalid" 7168 "Invalid" 7167 "Invalid" 7166 "Invalid" 7165 "Invalid" 7164 "Invalid" 7163 "Invalid" 7162 "Invalid" 7161 "Invalid" 7160 "Invalid" 7159 "Invalid" 7158 "Invalid" 7157 "Invalid" 7156 "Invalid" 7155 "Invalid" 7154 "Invalid" 7153 "Invalid" 7152 "Invalid" 7151 "Invalid" 7150 "Invalid" 7149 "Invalid" 7148 "Invalid" 7147 "Invalid" 7146 "Invalid" 7145 "Invalid" 7144 "Invalid" 7143 "Invalid" 7142 "Invalid" 7141 "Invalid" 7140 "Invalid" 7139 "Invalid" 7138 "Invalid" 7137 "Invalid" 7136 "Invalid" 7135 "Invalid" 7134 "Invalid" 7133 "Invalid" 7132 "Invalid" 7131 "Invalid" 7130 "Invalid" 7129 "Invalid" 7128 "Invalid" 7127 "Invalid" 7126 "Invalid" 7125 "Invalid" 7124 "Invalid" 7123 "Invalid" 7122 "Invalid" 7121 "Invalid" 7120 "Invalid" 7119 "Invalid" 7118 "Invalid" 7117 "Invalid" 7116 "Invalid" 7115 "Invalid" 7114 "Invalid" 7113 "Invalid" 7112 "Invalid" 7111 "Invalid" 7110 "Invalid" 7109 "Invalid" 7108 "Invalid" 7107 "Invalid" 7106 "Invalid" 7105 "Invalid" 7104 "Invalid" 7103 "Invalid" 7102 "Invalid" 7101 "Invalid" 7100 "Invalid" 7099 "Invalid" 7098 "Invalid" 7097 "Invalid" 7096 "Invalid" 7095 "Invalid" 7094 "Invalid" 7093 "Invalid" 7092 "Invalid" 7091 "Invalid" 7090 "Invalid" 7089 "Invalid" 7088 "Invalid" 7087 "Invalid" 7086 "Invalid" 7085 "Invalid" 7084 "Invalid" 7083 "Invalid" 7082 "Invalid" 7081 "Invalid" 7080 "Invalid" 7079 "Invalid" 7078 "Invalid" 7077 "Invalid" 7076 "Invalid" 7075 "Invalid" 7074 "Invalid" 7073 "Invalid" 7072 "Invalid" 7071 "Invalid" 7070 "Invalid" 7069 "Invalid" 7068 "Invalid" 7067 "Invalid" 7066 "Invalid" 7065 "Invalid" 7064 "Invalid" 7063 "Invalid" 7062 "Invalid" 7061 "Invalid" 7060 "Invalid" 7059 "Invalid" 7058 "Invalid" 7057 "Invalid" 7056 "Invalid" 7055 "Invalid" 7054 "Invalid" 7053 "Invalid" 7052 "Invalid" 7051 "Invalid" 7050 "Invalid" 7049 "Invalid" 7048 "Invalid" 7047 "Invalid" 7046 "Invalid" 7045 "Invalid" 7044 "Invalid" 7043 "Invalid" 7042 "Invalid" 7041 "Invalid" 7040 "Invalid" 7039 "Invalid" 7038 "Invalid" 7037 "Invalid" 7036 "Invalid" 7035 "Invalid" 7034 "Invalid" 7033 "Invalid" 7032 "Invalid" 7031 "Invalid" 7030 "Invalid" 7029 "Invalid" 7028 "Invalid" 7027 "Invalid" 7026 "Invalid" 7025 "Invalid" 7024 "Invalid" 7023 "Invalid" 7022 "Invalid" 7021 "Invalid" 7020 "Invalid" 7019 "Invalid" 7018 "Invalid" 7017 "Invalid" 7016 "Invalid" 7015 "Invalid" 7014 "Invalid" 7013 "Invalid" 7012 "Invalid" 7011 "Invalid" 7010 "Invalid" 7009 "Invalid" 7008 "Invalid" 7007 "Invalid" 7006 "Invalid" 7005 "Invalid" 7004 "Invalid" 7003 "Invalid" 7002 "Invalid" 7001 "Invalid" 7000 "Invalid" 6999 "Invalid" 6998 "Invalid" 6997 "Invalid" 6996 "Invalid" 6995 "Invalid" 6994 "Invalid" 6993 "Invalid" 6992 "Invalid" 6991 "Invalid" 6990 "Invalid" 6989 "Invalid" 6988 "Invalid" 6987 "Invalid" 6986 "Invalid" 6985 "Invalid" 6984 "Invalid" 6983 "Invalid" 6982 "Invalid" 6981 "Invalid" 6980 "Invalid" 6979 "Invalid" 6978 "Invalid" 6977 "Invalid" 6976 "Invalid" 6975 "Invalid" 6974 "Invalid" 6973 "Invalid" 6972 "Invalid" 6971 "Invalid" 6970 "Invalid" 6969 "Invalid" 6968 "Invalid" 6967 "Invalid" 6966 "Invalid" 6965 "Invalid" 6964 "Invalid" 6963 "Invalid" 6962 "Invalid" 6961 "Invalid" 6960 "Invalid" 6959 "Invalid" 6958 "Invalid" 6957 "Invalid" 6956 "Invalid" 6955 "Invalid" 6954 "Invalid" 6953 "Invalid" 6952 "Invalid" 6951 "Invalid" 6950 "Invalid" 6949 "Invalid" 6948 "Invalid" 6947 "Invalid" 6946 "Invalid" 6945 "Invalid" 6944 "Invalid" 6943 "Invalid" 6942 "Invalid" 6941 "Invalid" 6940 "Invalid" 6939 "Invalid" 6938 "Invalid" 6937 "Invalid" 6936 "Invalid" 6935 "Invalid" 6934 "Invalid" 6933 "Invalid" 6932 "Invalid" 6931 "Invalid" 6930 "Invalid" 6929 "Invalid" 6928 "Invalid" 6927 "Invalid" 6926 "Invalid" 6925 "Invalid" 6924 "Invalid" 6923 "Invalid" 6922 "Invalid" 6921 "Invalid" 6920 "Invalid" 6919 "Invalid" 6918 "Invalid" 6917 "Invalid" 6916 "Invalid" 6915 "Invalid" 6914 "Invalid" 6913 "Invalid" 6912 "Invalid" 6911 "Invalid" 6910 "Invalid" 6909 "Invalid" 6908 "Invalid" 6907 "Invalid" 6906 "Invalid" 6905 "Invalid" 6904 "Invalid" 6903 "Invalid" 6902 "Invalid" 6901 "Invalid" 6900 "Invalid" 6899 "Invalid" 6898 "Invalid" 6897 "Invalid" 6896 "Invalid" 6895 "Invalid" 6894 "Invalid" 6893 "Invalid" 6892 "Invalid" 6891 "Invalid" 6890 "Invalid" 6889 "Invalid" 6888 "Invalid" 6887 "Invalid" 6886 "Invalid" 6885 "Invalid" 6884 "Invalid" 6883 "Invalid" 6882 "Invalid" 6881 "Invalid" 6880 "Invalid" 6879 "Invalid" 6878 "Invalid" 6877 "Invalid" 6876 "Invalid" 6875 "Invalid" 6874 "Invalid" 6873 "Invalid" 6872 "Invalid" 6871 "Invalid" 6870 "Invalid" 6869 "Invalid" 6868 "Invalid" 6867 "Invalid" 6866 "Invalid" 6865 "Invalid" 6864 "Invalid" 6863 "Invalid" 6862 "Invalid" 6861 "Invalid" 6860 "Invalid" 6859 "Invalid" 6858 "Invalid" 6857 "Invalid" 6856 "Invalid" 6855 "Invalid" 6854 "Invalid" 6853 "Invalid" 6852 "Invalid" 6851 "Invalid" 6850 "Invalid" 6849 "Invalid" 6848 "Invalid" 6847 "Invalid" 6846 "Invalid" 6845 "Invalid" 6844 "Invalid" 6843 "Invalid" 6842 "Invalid" 6841 "Invalid" 6840 "Invalid" 6839 "Invalid" 6838 "Invalid" 6837 "Invalid" 6836 "Invalid" 6835 "Invalid" 6834 "Invalid" 6833 "Invalid" 6832 "Invalid" 6831 "Invalid" 6830 "Invalid" 6829 "Invalid" 6828 "Invalid" 6827 "Invalid" 6826 "Invalid" 6825 "Invalid" 6824 "Invalid" 6823 "Invalid" 6822 "Invalid" 6821 "Invalid" 6820 "Invalid" 6819 "Invalid" 6818 "Invalid" 6817 "Invalid" 6816 "Invalid" 6815 "Invalid" 6814 "Invalid" 6813 "Invalid" 6812 "Invalid" 6811 "Invalid" 6810 "Invalid" 6809 "Invalid" 6808 "Invalid" 6807 "Invalid" 6806 "Invalid" 6805 "Invalid" 6804 "Invalid" 6803 "Invalid" 6802 "Invalid" 6801 "Invalid" 6800 "Invalid" 6799 "Invalid" 6798 "Invalid" 6797 "Invalid" 6796 "Invalid" 6795 "Invalid" 6794 "Invalid" 6793 "Invalid" 6792 "Invalid" 6791 "Invalid" 6790 "Invalid" 6789 "Invalid" 6788 "Invalid" 6787 "Invalid" 6786 "Invalid" 6785 "Invalid" 6784 "Invalid" 6783 "Invalid" 6782 "Invalid" 6781 "Invalid" 6780 "Invalid" 6779 "Invalid" 6778 "Invalid" 6777 "Invalid" 6776 "Invalid" 6775 "Invalid" 6774 "Invalid" 6773 "Invalid" 6772 "Invalid" 6771 "Invalid" 6770 "Invalid" 6769 "Invalid" 6768 "Invalid" 6767 "Invalid" 6766 "Invalid" 6765 "Invalid" 6764 "Invalid" 6763 "Invalid" 6762 "Invalid" 6761 "Invalid" 6760 "Invalid" 6759 "Invalid" 6758 "Invalid" 6757 "Invalid" 6756 "Invalid" 6755 "Invalid" 6754 "Invalid" 6753 "Invalid" 6752 "Invalid" 6751 "Invalid" 6750 "Invalid" 6749 "Invalid" 6748 "Invalid" 6747 "Invalid" 6746 "Invalid" 6745 "Invalid" 6744 "Invalid" 6743 "Invalid" 6742 "Invalid" 6741 "Invalid" 6740 "Invalid" 6739 "Invalid" 6738 "Invalid" 6737 "Invalid" 6736 "Invalid" 6735 "Invalid" 6734 "Invalid" 6733 "Invalid" 6732 "Invalid" 6731 "Invalid" 6730 "Invalid" 6729 "Invalid" 6728 "Invalid" 6727 "Invalid" 6726 "Invalid" 6725 "Invalid" 6724 "Invalid" 6723 "Invalid" 6722 "Invalid" 6721 "Invalid" 6720 "Invalid" 6719 "Invalid" 6718 "Invalid" 6717 "Invalid" 6716 "Invalid" 6715 "Invalid" 6714 "Invalid" 6713 "Invalid" 6712 "Invalid" 6711 "Invalid" 6710 "Invalid" 6709 "Invalid" 6708 "Invalid" 6707 "Invalid" 6706 "Invalid" 6705 "Invalid" 6704 "Invalid" 6703 "Invalid" 6702 "Invalid" 6701 "Invalid" 6700 "Invalid" 6699 "Invalid" 6698 "Invalid" 6697 "Invalid" 6696 "Invalid" 6695 "Invalid" 6694 "Invalid" 6693 "Invalid" 6692 "Invalid" 6691 "Invalid" 6690 "Invalid" 6689 "Invalid" 6688 "Invalid" 6687 "Invalid" 6686 "Invalid" 6685 "Invalid" 6684 "Invalid" 6683 "Invalid" 6682 "Invalid" 6681 "Invalid" 6680 "Invalid" 6679 "Invalid" 6678 "Invalid" 6677 "Invalid" 6676 "Invalid" 6675 "Invalid" 6674 "Invalid" 6673 "Invalid" 6672 "Invalid" 6671 "Invalid" 6670 "Invalid" 6669 "Invalid" 6668 "Invalid" 6667 "Invalid" 6666 "Invalid" 6665 "Invalid" 6664 "Invalid" 6663 "Invalid" 6662 "Invalid" 6661 "Invalid" 6660 "Invalid" 6659 "Invalid" 6658 "Invalid" 6657 "Invalid" 6656 "Invalid" 6655 "Invalid" 6654 "Invalid" 6653 "Invalid" 6652 "Invalid" 6651 "Invalid" 6650 "Invalid" 6649 "Invalid" 6648 "Invalid" 6647 "Invalid" 6646 "Invalid" 6645 "Invalid" 6644 "Invalid" 6643 "Invalid" 6642 "Invalid" 6641 "Invalid" 6640 "Invalid" 6639 "Invalid" 6638 "Invalid" 6637 "Invalid" 6636 "Invalid" 6635 "Invalid" 6634 "Invalid" 6633 "Invalid" 6632 "Invalid" 6631 "Invalid" 6630 "Invalid" 6629 "Invalid" 6628 "Invalid" 6627 "Invalid" 6626 "Invalid" 6625 "Invalid" 6624 "Invalid" 6623 "Invalid" 6622 "Invalid" 6621 "Invalid" 6620 "Invalid" 6619 "Invalid" 6618 "Invalid" 6617 "Invalid" 6616 "Invalid" 6615 "Invalid" 6614 "Invalid" 6613 "Invalid" 6612 "Invalid" 6611 "Invalid" 6610 "Invalid" 6609 "Invalid" 6608 "Invalid" 6607 "Invalid" 6606 "Invalid" 6605 "Invalid" 6604 "Invalid" 6603 "Invalid" 6602 "Invalid" 6601 "Invalid" 6600 "Invalid" 6599 "Invalid" 6598 "Invalid" 6597 "Invalid" 6596 "Invalid" 6595 "Invalid" 6594 "Invalid" 6593 "Invalid" 6592 "Invalid" 6591 "Invalid" 6590 "Invalid" 6589 "Invalid" 6588 "Invalid" 6587 "Invalid" 6586 "Invalid" 6585 "Invalid" 6584 "Invalid" 6583 "Invalid" 6582 "Invalid" 6581 "Invalid" 6580 "Invalid" 6579 "Invalid" 6578 "Invalid" 6577 "Invalid" 6576 "Invalid" 6575 "Invalid" 6574 "Invalid" 6573 "Invalid" 6572 "Invalid" 6571 "Invalid" 6570 "Invalid" 6569 "Invalid" 6568 "Invalid" 6567 "Invalid" 6566 "Invalid" 6565 "Invalid" 6564 "Invalid" 6563 "Invalid" 6562 "Invalid" 6561 "Invalid" 6560 "Invalid" 6559 "Invalid" 6558 "Invalid" 6557 "Invalid" 6556 "Invalid" 6555 "Invalid" 6554 "Invalid" 6553 "Invalid" 6552 "Invalid" 6551 "Invalid" 6550 "Invalid" 6549 "Invalid" 6548 "Invalid" 6547 "Invalid" 6546 "Invalid" 6545 "Invalid" 6544 "Invalid" 6543 "Invalid" 6542 "Invalid" 6541 "Invalid" 6540 "Invalid" 6539 "Invalid" 6538 "Invalid" 6537 "Invalid" 6536 "Invalid" 6535 "Invalid" 6534 "Invalid" 6533 "Invalid" 6532 "Invalid" 6531 "Invalid" 6530 "Invalid" 6529 "Invalid" 6528 "Invalid" 6527 "Invalid" 6526 "Invalid" 6525 "Invalid" 6524 "Invalid" 6523 "Invalid" 6522 "Invalid" 6521 "Invalid" 6520 "Invalid" 6519 "Invalid" 6518 "Invalid" 6517 "Invalid" 6516 "Invalid" 6515 "Invalid" 6514 "Invalid" 6513 "Invalid" 6512 "Invalid" 6511 "Invalid" 6510 "Invalid" 6509 "Invalid" 6508 "Invalid" 6507 "Invalid" 6506 "Invalid" 6505 "Invalid" 6504 "Invalid" 6503 "Invalid" 6502 "Invalid" 6501 "Invalid" 6500 "Invalid" 6499 "Invalid" 6498 "Invalid" 6497 "Invalid" 6496 "Invalid" 6495 "Invalid" 6494 "Invalid" 6493 "Invalid" 6492 "Invalid" 6491 "Invalid" 6490 "Invalid" 6489 "Invalid" 6488 "Invalid" 6487 "Invalid" 6486 "Invalid" 6485 "Invalid" 6484 "Invalid" 6483 "Invalid" 6482 "Invalid" 6481 "Invalid" 6480 "Invalid" 6479 "Invalid" 6478 "Invalid" 6477 "Invalid" 6476 "Invalid" 6475 "Invalid" 6474 "Invalid" 6473 "Invalid" 6472 "Invalid" 6471 "Invalid" 6470 "Invalid" 6469 "Invalid" 6468 "Invalid" 6467 "Invalid" 6466 "Invalid" 6465 "Invalid" 6464 "Invalid" 6463 "Invalid" 6462 "Invalid" 6461 "Invalid" 6460 "Invalid" 6459 "Invalid" 6458 "Invalid" 6457 "Invalid" 6456 "Invalid" 6455 "Invalid" 6454 "Invalid" 6453 "Invalid" 6452 "Invalid" 6451 "Invalid" 6450 "Invalid" 6449 "Invalid" 6448 "Invalid" 6447 "Invalid" 6446 "Invalid" 6445 "Invalid" 6444 "Invalid" 6443 "Invalid" 6442 "Invalid" 6441 "Invalid" 6440 "Invalid" 6439 "Invalid" 6438 "Invalid" 6437 "Invalid" 6436 "Invalid" 6435 "Invalid" 6434 "Invalid" 6433 "Invalid" 6432 "Invalid" 6431 "Invalid" 6430 "Invalid" 6429 "Invalid" 6428 "Invalid" 6427 "Invalid" 6426 "Invalid" 6425 "Invalid" 6424 "Invalid" 6423 "Invalid" 6422 "Invalid" 6421 "Invalid" 6420 "Invalid" 6419 "Invalid" 6418 "Invalid" 6417 "Invalid" 6416 "Invalid" 6415 "Invalid" 6414 "Invalid" 6413 "Invalid" 6412 "Invalid" 6411 "Invalid" 6410 "Invalid" 6409 "Invalid" 6408 "Invalid" 6407 "Invalid" 6406 "Invalid" 6405 "Invalid" 6404 "Invalid" 6403 "Invalid" 6402 "Invalid" 6401 "Invalid" 6400 "Invalid" 6399 "Invalid" 6398 "Invalid" 6397 "Invalid" 6396 "Invalid" 6395 "Invalid" 6394 "Invalid" 6393 "Invalid" 6392 "Invalid" 6391 "Invalid" 6390 "Invalid" 6389 "Invalid" 6388 "Invalid" 6387 "Invalid" 6386 "Invalid" 6385 "Invalid" 6384 "Invalid" 6383 "Invalid" 6382 "Invalid" 6381 "Invalid" 6380 "Invalid" 6379 "Invalid" 6378 "Invalid" 6377 "Invalid" 6376 "Invalid" 6375 "Invalid" 6374 "Invalid" 6373 "Invalid" 6372 "Invalid" 6371 "Invalid" 6370 "Invalid" 6369 "Invalid" 6368 "Invalid" 6367 "Invalid" 6366 "Invalid" 6365 "Invalid" 6364 "Invalid" 6363 "Invalid" 6362 "Invalid" 6361 "Invalid" 6360 "Invalid" 6359 "Invalid" 6358 "Invalid" 6357 "Invalid" 6356 "Invalid" 6355 "Invalid" 6354 "Invalid" 6353 "Invalid" 6352 "Invalid" 6351 "Invalid" 6350 "Invalid" 6349 "Invalid" 6348 "Invalid" 6347 "Invalid" 6346 "Invalid" 6345 "Invalid" 6344 "Invalid" 6343 "Invalid" 6342 "Invalid" 6341 "Invalid" 6340 "Invalid" 6339 "Invalid" 6338 "Invalid" 6337 "Invalid" 6336 "Invalid" 6335 "Invalid" 6334 "Invalid" 6333 "Invalid" 6332 "Invalid" 6331 "Invalid" 6330 "Invalid" 6329 "Invalid" 6328 "Invalid" 6327 "Invalid" 6326 "Invalid" 6325 "Invalid" 6324 "Invalid" 6323 "Invalid" 6322 "Invalid" 6321 "Invalid" 6320 "Invalid" 6319 "Invalid" 6318 "Invalid" 6317 "Invalid" 6316 "Invalid" 6315 "Invalid" 6314 "Invalid" 6313 "Invalid" 6312 "Invalid" 6311 "Invalid" 6310 "Invalid" 6309 "Invalid" 6308 "Invalid" 6307 "Invalid" 6306 "Invalid" 6305 "Invalid" 6304 "Invalid" 6303 "Invalid" 6302 "Invalid" 6301 "Invalid" 6300 "Invalid" 6299 "Invalid" 6298 "Invalid" 6297 "Invalid" 6296 "Invalid" 6295 "Invalid" 6294 "Invalid" 6293 "Invalid" 6292 "Invalid" 6291 "Invalid" 6290 "Invalid" 6289 "Invalid" 6288 "Invalid" 6287 "Invalid" 6286 "Invalid" 6285 "Invalid" 6284 "Invalid" 6283 "Invalid" 6282 "Invalid" 6281 "Invalid" 6280 "Invalid" 6279 "Invalid" 6278 "Invalid" 6277 "Invalid" 6276 "Invalid" 6275 "Invalid" 6274 "Invalid" 6273 "Invalid" 6272 "Invalid" 6271 "Invalid" 6270 "Invalid" 6269 "Invalid" 6268 "Invalid" 6267 "Invalid" 6266 "Invalid" 6265 "Invalid" 6264 "Invalid" 6263 "Invalid" 6262 "Invalid" 6261 "Invalid" 6260 "Invalid" 6259 "Invalid" 6258 "Invalid" 6257 "Invalid" 6256 "Invalid" 6255 "Invalid" 6254 "Invalid" 6253 "Invalid" 6252 "Invalid" 6251 "Invalid" 6250 "Invalid" 6249 "Invalid" 6248 "Invalid" 6247 "Invalid" 6246 "Invalid" 6245 "Invalid" 6244 "Invalid" 6243 "Invalid" 6242 "Invalid" 6241 "Invalid" 6240 "Invalid" 6239 "Invalid" 6238 "Invalid" 6237 "Invalid" 6236 "Invalid" 6235 "Invalid" 6234 "Invalid" 6233 "Invalid" 6232 "Invalid" 6231 "Invalid" 6230 "Invalid" 6229 "Invalid" 6228 "Invalid" 6227 "Invalid" 6226 "Invalid" 6225 "Invalid" 6224 "Invalid" 6223 "Invalid" 6222 "Invalid" 6221 "Invalid" 6220 "Invalid" 6219 "Invalid" 6218 "Invalid" 6217 "Invalid" 6216 "Invalid" 6215 "Invalid" 6214 "Invalid" 6213 "Invalid" 6212 "Invalid" 6211 "Invalid" 6210 "Invalid" 6209 "Invalid" 6208 "Invalid" 6207 "Invalid" 6206 "Invalid" 6205 "Invalid" 6204 "Invalid" 6203 "Invalid" 6202 "Invalid" 6201 "Invalid" 6200 "Invalid" 6199 "Invalid" 6198 "Invalid" 6197 "Invalid" 6196 "Invalid" 6195 "Invalid" 6194 "Invalid" 6193 "Invalid" 6192 "Invalid" 6191 "Invalid" 6190 "Invalid" 6189 "Invalid" 6188 "Invalid" 6187 "Invalid" 6186 "Invalid" 6185 "Invalid" 6184 "Invalid" 6183 "Invalid" 6182 "Invalid" 6181 "Invalid" 6180 "Invalid" 6179 "Invalid" 6178 "Invalid" 6177 "Invalid" 6176 "Invalid" 6175 "Invalid" 6174 "Invalid" 6173 "Invalid" 6172 "Invalid" 6171 "Invalid" 6170 "Invalid" 6169 "Invalid" 6168 "Invalid" 6167 "Invalid" 6166 "Invalid" 6165 "Invalid" 6164 "Invalid" 6163 "Invalid" 6162 "Invalid" 6161 "Invalid" 6160 "Invalid" 6159 "Invalid" 6158 "Invalid" 6157 "Invalid" 6156 "Invalid" 6155 "Invalid" 6154 "Invalid" 6153 "Invalid" 6152 "Invalid" 6151 "Invalid" 6150 "Invalid" 6149 "Invalid" 6148 "Invalid" 6147 "Invalid" 6146 "Invalid" 6145 "Invalid" 6144 "Invalid" 6143 "Invalid" 6142 "Invalid" 6141 "Invalid" 6140 "Invalid" 6139 "Invalid" 6138 "Invalid" 6137 "Invalid" 6136 "Invalid" 6135 "Invalid" 6134 "Invalid" 6133 "Invalid" 6132 "Invalid" 6131 "Invalid" 6130 "Invalid" 6129 "Invalid" 6128 "Invalid" 6127 "Invalid" 6126 "Invalid" 6125 "Invalid" 6124 "Invalid" 6123 "Invalid" 6122 "Invalid" 6121 "Invalid" 6120 "Invalid" 6119 "Invalid" 6118 "Invalid" 6117 "Invalid" 6116 "Invalid" 6115 "Invalid" 6114 "Invalid" 6113 "Invalid" 6112 "Invalid" 6111 "Invalid" 6110 "Invalid" 6109 "Invalid" 6108 "Invalid" 6107 "Invalid" 6106 "Invalid" 6105 "Invalid" 6104 "Invalid" 6103 "Invalid" 6102 "Invalid" 6101 "Invalid" 6100 "Invalid" 6099 "Invalid" 6098 "Invalid" 6097 "Invalid" 6096 "Invalid" 6095 "Invalid" 6094 "Invalid" 6093 "Invalid" 6092 "Invalid" 6091 "Invalid" 6090 "Invalid" 6089 "Invalid" 6088 "Invalid" 6087 "Invalid" 6086 "Invalid" 6085 "Invalid" 6084 "Invalid" 6083 "Invalid" 6082 "Invalid" 6081 "Invalid" 6080 "Invalid" 6079 "Invalid" 6078 "Invalid" 6077 "Invalid" 6076 "Invalid" 6075 "Invalid" 6074 "Invalid" 6073 "Invalid" 6072 "Invalid" 6071 "Invalid" 6070 "Invalid" 6069 "Invalid" 6068 "Invalid" 6067 "Invalid" 6066 "Invalid" 6065 "Invalid" 6064 "Invalid" 6063 "Invalid" 6062 "Invalid" 6061 "Invalid" 6060 "Invalid" 6059 "Invalid" 6058 "Invalid" 6057 "Invalid" 6056 "Invalid" 6055 "Invalid" 6054 "Invalid" 6053 "Invalid" 6052 "Invalid" 6051 "Invalid" 6050 "Invalid" 6049 "Invalid" 6048 "Invalid" 6047 "Invalid" 6046 "Invalid" 6045 "Invalid" 6044 "Invalid" 6043 "Invalid" 6042 "Invalid" 6041 "Invalid" 6040 "Invalid" 6039 "Invalid" 6038 "Invalid" 6037 "Invalid" 6036 "Invalid" 6035 "Invalid" 6034 "Invalid" 6033 "Invalid" 6032 "Invalid" 6031 "Invalid" 6030 "Invalid" 6029 "Invalid" 6028 "Invalid" 6027 "Invalid" 6026 "Invalid" 6025 "Invalid" 6024 "Invalid" 6023 "Invalid" 6022 "Invalid" 6021 "Invalid" 6020 "Invalid" 6019 "Invalid" 6018 "Invalid" 6017 "Invalid" 6016 "Invalid" 6015 "Invalid" 6014 "Invalid" 6013 "Invalid" 6012 "Invalid" 6011 "Invalid" 6010 "Invalid" 6009 "Invalid" 6008 "Invalid" 6007 "Invalid" 6006 "Invalid" 6005 "Invalid" 6004 "Invalid" 6003 "Invalid" 6002 "Invalid" 6001 "Invalid" 6000 "Invalid" 5999 "Invalid" 5998 "Invalid" 5997 "Invalid" 5996 "Invalid" 5995 "Invalid" 5994 "Invalid" 5993 "Invalid" 5992 "Invalid" 5991 "Invalid" 5990 "Invalid" 5989 "Invalid" 5988 "Invalid" 5987 "Invalid" 5986 "Invalid" 5985 "Invalid" 5984 "Invalid" 5983 "Invalid" 5982 "Invalid" 5981 "Invalid" 5980 "Invalid" 5979 "Invalid" 5978 "Invalid" 5977 "Invalid" 5976 "Invalid" 5975 "Invalid" 5974 "Invalid" 5973 "Invalid" 5972 "Invalid" 5971 "Invalid" 5970 "Invalid" 5969 "Invalid" 5968 "Invalid" 5967 "Invalid" 5966 "Invalid" 5965 "Invalid" 5964 "Invalid" 5963 "Invalid" 5962 "Invalid" 5961 "Invalid" 5960 "Invalid" 5959 "Invalid" 5958 "Invalid" 5957 "Invalid" 5956 "Invalid" 5955 "Invalid" 5954 "Invalid" 5953 "Invalid" 5952 "Invalid" 5951 "Invalid" 5950 "Invalid" 5949 "Invalid" 5948 "Invalid" 5947 "Invalid" 5946 "Invalid" 5945 "Invalid" 5944 "Invalid" 5943 "Invalid" 5942 "Invalid" 5941 "Invalid" 5940 "Invalid" 5939 "Invalid" 5938 "Invalid" 5937 "Invalid" 5936 "Invalid" 5935 "Invalid" 5934 "Invalid" 5933 "Invalid" 5932 "Invalid" 5931 "Invalid" 5930 "Invalid" 5929 "Invalid" 5928 "Invalid" 5927 "Invalid" 5926 "Invalid" 5925 "Invalid" 5924 "Invalid" 5923 "Invalid" 5922 "Invalid" 5921 "Invalid" 5920 "Invalid" 5919 "Invalid" 5918 "Invalid" 5917 "Invalid" 5916 "Invalid" 5915 "Invalid" 5914 "Invalid" 5913 "Invalid" 5912 "Invalid" 5911 "Invalid" 5910 "Invalid" 5909 "Invalid" 5908 "Invalid" 5907 "Invalid" 5906 "Invalid" 5905 "Invalid" 5904 "Invalid" 5903 "Invalid" 5902 "Invalid" 5901 "Invalid" 5900 "Invalid" 5899 "Invalid" 5898 "Invalid" 5897 "Invalid" 5896 "Invalid" 5895 "Invalid" 5894 "Invalid" 5893 "Invalid" 5892 "Invalid" 5891 "Invalid" 5890 "Invalid" 5889 "Invalid" 5888 "Invalid" 5887 "Invalid" 5886 "Invalid" 5885 "Invalid" 5884 "Invalid" 5883 "Invalid" 5882 "Invalid" 5881 "Invalid" 5880 "Invalid" 5879 "Invalid" 5878 "Invalid" 5877 "Invalid" 5876 "Invalid" 5875 "Invalid" 5874 "Invalid" 5873 "Invalid" 5872 "Invalid" 5871 "Invalid" 5870 "Invalid" 5869 "Invalid" 5868 "Invalid" 5867 "Invalid" 5866 "Invalid" 5865 "Invalid" 5864 "Invalid" 5863 "Invalid" 5862 "Invalid" 5861 "Invalid" 5860 "Invalid" 5859 "Invalid" 5858 "Invalid" 5857 "Invalid" 5856 "Invalid" 5855 "Invalid" 5854 "Invalid" 5853 "Invalid" 5852 "Invalid" 5851 "Invalid" 5850 "Invalid" 5849 "Invalid" 5848 "Invalid" 5847 "Invalid" 5846 "Invalid" 5845 "Invalid" 5844 "Invalid" 5843 "Invalid" 5842 "Invalid" 5841 "Invalid" 5840 "Invalid" 5839 "Invalid" 5838 "Invalid" 5837 "Invalid" 5836 "Invalid" 5835 "Invalid" 5834 "Invalid" 5833 "Invalid" 5832 "Invalid" 5831 "Invalid" 5830 "Invalid" 5829 "Invalid" 5828 "Invalid" 5827 "Invalid" 5826 "Invalid" 5825 "Invalid" 5824 "Invalid" 5823 "Invalid" 5822 "Invalid" 5821 "Invalid" 5820 "Invalid" 5819 "Invalid" 5818 "Invalid" 5817 "Invalid" 5816 "Invalid" 5815 "Invalid" 5814 "Invalid" 5813 "Invalid" 5812 "Invalid" 5811 "Invalid" 5810 "Invalid" 5809 "Invalid" 5808 "Invalid" 5807 "Invalid" 5806 "Invalid" 5805 "Invalid" 5804 "Invalid" 5803 "Invalid" 5802 "Invalid" 5801 "Invalid" 5800 "Invalid" 5799 "Invalid" 5798 "Invalid" 5797 "Invalid" 5796 "Invalid" 5795 "Invalid" 5794 "Invalid" 5793 "Invalid" 5792 "Invalid" 5791 "Invalid" 5790 "Invalid" 5789 "Invalid" 5788 "Invalid" 5787 "Invalid" 5786 "Invalid" 5785 "Invalid" 5784 "Invalid" 5783 "Invalid" 5782 "Invalid" 5781 "Invalid" 5780 "Invalid" 5779 "Invalid" 5778 "Invalid" 5777 "Invalid" 5776 "Invalid" 5775 "Invalid" 5774 "Invalid" 5773 "Invalid" 5772 "Invalid" 5771 "Invalid" 5770 "Invalid" 5769 "Invalid" 5768 "Invalid" 5767 "Invalid" 5766 "Invalid" 5765 "Invalid" 5764 "Invalid" 5763 "Invalid" 5762 "Invalid" 5761 "Invalid" 5760 "Invalid" 5759 "Invalid" 5758 "Invalid" 5757 "Invalid" 5756 "Invalid" 5755 "Invalid" 5754 "Invalid" 5753 "Invalid" 5752 "Invalid" 5751 "Invalid" 5750 "Invalid" 5749 "Invalid" 5748 "Invalid" 5747 "Invalid" 5746 "Invalid" 5745 "Invalid" 5744 "Invalid" 5743 "Invalid" 5742 "Invalid" 5741 "Invalid" 5740 "Invalid" 5739 "Invalid" 5738 "Invalid" 5737 "Invalid" 5736 "Invalid" 5735 "Invalid" 5734 "Invalid" 5733 "Invalid" 5732 "Invalid" 5731 "Invalid" 5730 "Invalid" 5729 "Invalid" 5728 "Invalid" 5727 "Invalid" 5726 "Invalid" 5725 "Invalid" 5724 "Invalid" 5723 "Invalid" 5722 "Invalid" 5721 "Invalid" 5720 "Invalid" 5719 "Invalid" 5718 "Invalid" 5717 "Invalid" 5716 "Invalid" 5715 "Invalid" 5714 "Invalid" 5713 "Invalid" 5712 "Invalid" 5711 "Invalid" 5710 "Invalid" 5709 "Invalid" 5708 "Invalid" 5707 "Invalid" 5706 "Invalid" 5705 "Invalid" 5704 "Invalid" 5703 "Invalid" 5702 "Invalid" 5701 "Invalid" 5700 "Invalid" 5699 "Invalid" 5698 "Invalid" 5697 "Invalid" 5696 "Invalid" 5695 "Invalid" 5694 "Invalid" 5693 "Invalid" 5692 "Invalid" 5691 "Invalid" 5690 "Invalid" 5689 "Invalid" 5688 "Invalid" 5687 "Invalid" 5686 "Invalid" 5685 "Invalid" 5684 "Invalid" 5683 "Invalid" 5682 "Invalid" 5681 "Invalid" 5680 "Invalid" 5679 "Invalid" 5678 "Invalid" 5677 "Invalid" 5676 "Invalid" 5675 "Invalid" 5674 "Invalid" 5673 "Invalid" 5672 "Invalid" 5671 "Invalid" 5670 "Invalid" 5669 "Invalid" 5668 "Invalid" 5667 "Invalid" 5666 "Invalid" 5665 "Invalid" 5664 "Invalid" 5663 "Invalid" 5662 "Invalid" 5661 "Invalid" 5660 "Invalid" 5659 "Invalid" 5658 "Invalid" 5657 "Invalid" 5656 "Invalid" 5655 "Invalid" 5654 "Invalid" 5653 "Invalid" 5652 "Invalid" 5651 "Invalid" 5650 "Invalid" 5649 "Invalid" 5648 "Invalid" 5647 "Invalid" 5646 "Invalid" 5645 "Invalid" 5644 "Invalid" 5643 "Invalid" 5642 "Invalid" 5641 "Invalid" 5640 "Invalid" 5639 "Invalid" 5638 "Invalid" 5637 "Invalid" 5636 "Invalid" 5635 "Invalid" 5634 "Invalid" 5633 "Invalid" 5632 "Invalid" 5631 "Invalid" 5630 "Invalid" 5629 "Invalid" 5628 "Invalid" 5627 "Invalid" 5626 "Invalid" 5625 "Invalid" 5624 "Invalid" 5623 "Invalid" 5622 "Invalid" 5621 "Invalid" 5620 "Invalid" 5619 "Invalid" 5618 "Invalid" 5617 "Invalid" 5616 "Invalid" 5615 "Invalid" 5614 "Invalid" 5613 "Invalid" 5612 "Invalid" 5611 "Invalid" 5610 "Invalid" 5609 "Invalid" 5608 "Invalid" 5607 "Invalid" 5606 "Invalid" 5605 "Invalid" 5604 "Invalid" 5603 "Invalid" 5602 "Invalid" 5601 "Invalid" 5600 "Invalid" 5599 "Invalid" 5598 "Invalid" 5597 "Invalid" 5596 "Invalid" 5595 "Invalid" 5594 "Invalid" 5593 "Invalid" 5592 "Invalid" 5591 "Invalid" 5590 "Invalid" 5589 "Invalid" 5588 "Invalid" 5587 "Invalid" 5586 "Invalid" 5585 "Invalid" 5584 "Invalid" 5583 "Invalid" 5582 "Invalid" 5581 "Invalid" 5580 "Invalid" 5579 "Invalid" 5578 "Invalid" 5577 "Invalid" 5576 "Invalid" 5575 "Invalid" 5574 "Invalid" 5573 "Invalid" 5572 "Invalid" 5571 "Invalid" 5570 "Invalid" 5569 "Invalid" 5568 "Invalid" 5567 "Invalid" 5566 "Invalid" 5565 "Invalid" 5564 "Invalid" 5563 "Invalid" 5562 "Invalid" 5561 "Invalid" 5560 "Invalid" 5559 "Invalid" 5558 "Invalid" 5557 "Invalid" 5556 "Invalid" 5555 "Invalid" 5554 "Invalid" 5553 "Invalid" 5552 "Invalid" 5551 "Invalid" 5550 "Invalid" 5549 "Invalid" 5548 "Invalid" 5547 "Invalid" 5546 "Invalid" 5545 "Invalid" 5544 "Invalid" 5543 "Invalid" 5542 "Invalid" 5541 "Invalid" 5540 "Invalid" 5539 "Invalid" 5538 "Invalid" 5537 "Invalid" 5536 "Invalid" 5535 "Invalid" 5534 "Invalid" 5533 "Invalid" 5532 "Invalid" 5531 "Invalid" 5530 "Invalid" 5529 "Invalid" 5528 "Invalid" 5527 "Invalid" 5526 "Invalid" 5525 "Invalid" 5524 "Invalid" 5523 "Invalid" 5522 "Invalid" 5521 "Invalid" 5520 "Invalid" 5519 "Invalid" 5518 "Invalid" 5517 "Invalid" 5516 "Invalid" 5515 "Invalid" 5514 "Invalid" 5513 "Invalid" 5512 "Invalid" 5511 "Invalid" 5510 "Invalid" 5509 "Invalid" 5508 "Invalid" 5507 "Invalid" 5506 "Invalid" 5505 "Invalid" 5504 "Invalid" 5503 "Invalid" 5502 "Invalid" 5501 "Invalid" 5500 "Invalid" 5499 "Invalid" 5498 "Invalid" 5497 "Invalid" 5496 "Invalid" 5495 "Invalid" 5494 "Invalid" 5493 "Invalid" 5492 "Invalid" 5491 "Invalid" 5490 "Invalid" 5489 "Invalid" 5488 "Invalid" 5487 "Invalid" 5486 "Invalid" 5485 "Invalid" 5484 "Invalid" 5483 "Invalid" 5482 "Invalid" 5481 "Invalid" 5480 "Invalid" 5479 "Invalid" 5478 "Invalid" 5477 "Invalid" 5476 "Invalid" 5475 "Invalid" 5474 "Invalid" 5473 "Invalid" 5472 "Invalid" 5471 "Invalid" 5470 "Invalid" 5469 "Invalid" 5468 "Invalid" 5467 "Invalid" 5466 "Invalid" 5465 "Invalid" 5464 "Invalid" 5463 "Invalid" 5462 "Invalid" 5461 "Invalid" 5460 "Invalid" 5459 "Invalid" 5458 "Invalid" 5457 "Invalid" 5456 "Invalid" 5455 "Invalid" 5454 "Invalid" 5453 "Invalid" 5452 "Invalid" 5451 "Invalid" 5450 "Invalid" 5449 "Invalid" 5448 "Invalid" 5447 "Invalid" 5446 "Invalid" 5445 "Invalid" 5444 "Invalid" 5443 "Invalid" 5442 "Invalid" 5441 "Invalid" 5440 "Invalid" 5439 "Invalid" 5438 "Invalid" 5437 "Invalid" 5436 "Invalid" 5435 "Invalid" 5434 "Invalid" 5433 "Invalid" 5432 "Invalid" 5431 "Invalid" 5430 "Invalid" 5429 "Invalid" 5428 "Invalid" 5427 "Invalid" 5426 "Invalid" 5425 "Invalid" 5424 "Invalid" 5423 "Invalid" 5422 "Invalid" 5421 "Invalid" 5420 "Invalid" 5419 "Invalid" 5418 "Invalid" 5417 "Invalid" 5416 "Invalid" 5415 "Invalid" 5414 "Invalid" 5413 "Invalid" 5412 "Invalid" 5411 "Invalid" 5410 "Invalid" 5409 "Invalid" 5408 "Invalid" 5407 "Invalid" 5406 "Invalid" 5405 "Invalid" 5404 "Invalid" 5403 "Invalid" 5402 "Invalid" 5401 "Invalid" 5400 "Invalid" 5399 "Invalid" 5398 "Invalid" 5397 "Invalid" 5396 "Invalid" 5395 "Invalid" 5394 "Invalid" 5393 "Invalid" 5392 "Invalid" 5391 "Invalid" 5390 "Invalid" 5389 "Invalid" 5388 "Invalid" 5387 "Invalid" 5386 "Invalid" 5385 "Invalid" 5384 "Invalid" 5383 "Invalid" 5382 "Invalid" 5381 "Invalid" 5380 "Invalid" 5379 "Invalid" 5378 "Invalid" 5377 "Invalid" 5376 "Invalid" 5375 "Invalid" 5374 "Invalid" 5373 "Invalid" 5372 "Invalid" 5371 "Invalid" 5370 "Invalid" 5369 "Invalid" 5368 "Invalid" 5367 "Invalid" 5366 "Invalid" 5365 "Invalid" 5364 "Invalid" 5363 "Invalid" 5362 "Invalid" 5361 "Invalid" 5360 "Invalid" 5359 "Invalid" 5358 "Invalid" 5357 "Invalid" 5356 "Invalid" 5355 "Invalid" 5354 "Invalid" 5353 "Invalid" 5352 "Invalid" 5351 "Invalid" 5350 "Invalid" 5349 "Invalid" 5348 "Invalid" 5347 "Invalid" 5346 "Invalid" 5345 "Invalid" 5344 "Invalid" 5343 "Invalid" 5342 "Invalid" 5341 "Invalid" 5340 "Invalid" 5339 "Invalid" 5338 "Invalid" 5337 "Invalid" 5336 "Invalid" 5335 "Invalid" 5334 "Invalid" 5333 "Invalid" 5332 "Invalid" 5331 "Invalid" 5330 "Invalid" 5329 "Invalid" 5328 "Invalid" 5327 "Invalid" 5326 "Invalid" 5325 "Invalid" 5324 "Invalid" 5323 "Invalid" 5322 "Invalid" 5321 "Invalid" 5320 "Invalid" 5319 "Invalid" 5318 "Invalid" 5317 "Invalid" 5316 "Invalid" 5315 "Invalid" 5314 "Invalid" 5313 "Invalid" 5312 "Invalid" 5311 "Invalid" 5310 "Invalid" 5309 "Invalid" 5308 "Invalid" 5307 "Invalid" 5306 "Invalid" 5305 "Invalid" 5304 "Invalid" 5303 "Invalid" 5302 "Invalid" 5301 "Invalid" 5300 "Invalid" 5299 "Invalid" 5298 "Invalid" 5297 "Invalid" 5296 "Invalid" 5295 "Invalid" 5294 "Invalid" 5293 "Invalid" 5292 "Invalid" 5291 "Invalid" 5290 "Invalid" 5289 "Invalid" 5288 "Invalid" 5287 "Invalid" 5286 "Invalid" 5285 "Invalid" 5284 "Invalid" 5283 "Invalid" 5282 "Invalid" 5281 "Invalid" 5280 "Invalid" 5279 "Invalid" 5278 "Invalid" 5277 "Invalid" 5276 "Invalid" 5275 "Invalid" 5274 "Invalid" 5273 "Invalid" 5272 "Invalid" 5271 "Invalid" 5270 "Invalid" 5269 "Invalid" 5268 "Invalid" 5267 "Invalid" 5266 "Invalid" 5265 "Invalid" 5264 "Invalid" 5263 "Invalid" 5262 "Invalid" 5261 "Invalid" 5260 "Invalid" 5259 "Invalid" 5258 "Invalid" 5257 "Invalid" 5256 "Invalid" 5255 "Invalid" 5254 "Invalid" 5253 "Invalid" 5252 "Invalid" 5251 "Invalid" 5250 "Invalid" 5249 "Invalid" 5248 "Invalid" 5247 "Invalid" 5246 "Invalid" 5245 "Invalid" 5244 "Invalid" 5243 "Invalid" 5242 "Invalid" 5241 "Invalid" 5240 "Invalid" 5239 "Invalid" 5238 "Invalid" 5237 "Invalid" 5236 "Invalid" 5235 "Invalid" 5234 "Invalid" 5233 "Invalid" 5232 "Invalid" 5231 "Invalid" 5230 "Invalid" 5229 "Invalid" 5228 "Invalid" 5227 "Invalid" 5226 "Invalid" 5225 "Invalid" 5224 "Invalid" 5223 "Invalid" 5222 "Invalid" 5221 "Invalid" 5220 "Invalid" 5219 "Invalid" 5218 "Invalid" 5217 "Invalid" 5216 "Invalid" 5215 "Invalid" 5214 "Invalid" 5213 "Invalid" 5212 "Invalid" 5211 "Invalid" 5210 "Invalid" 5209 "Invalid" 5208 "Invalid" 5207 "Invalid" 5206 "Invalid" 5205 "Invalid" 5204 "Invalid" 5203 "Invalid" 5202 "Invalid" 5201 "Invalid" 5200 "Invalid" 5199 "Invalid" 5198 "Invalid" 5197 "Invalid" 5196 "Invalid" 5195 "Invalid" 5194 "Invalid" 5193 "Invalid" 5192 "Invalid" 5191 "Invalid" 5190 "Invalid" 5189 "Invalid" 5188 "Invalid" 5187 "Invalid" 5186 "Invalid" 5185 "Invalid" 5184 "Invalid" 5183 "Invalid" 5182 "Invalid" 5181 "Invalid" 5180 "Invalid" 5179 "Invalid" 5178 "Invalid" 5177 "Invalid" 5176 "Invalid" 5175 "Invalid" 5174 "Invalid" 5173 "Invalid" 5172 "Invalid" 5171 "Invalid" 5170 "Invalid" 5169 "Invalid" 5168 "Invalid" 5167 "Invalid" 5166 "Invalid" 5165 "Invalid" 5164 "Invalid" 5163 "Invalid" 5162 "Invalid" 5161 "Invalid" 5160 "Invalid" 5159 "Invalid" 5158 "Invalid" 5157 "Invalid" 5156 "Invalid" 5155 "Invalid" 5154 "Invalid" 5153 "Invalid" 5152 "Invalid" 5151 "Invalid" 5150 "Invalid" 5149 "Invalid" 5148 "Invalid" 5147 "Invalid" 5146 "Invalid" 5145 "Invalid" 5144 "Invalid" 5143 "Invalid" 5142 "Invalid" 5141 "Invalid" 5140 "Invalid" 5139 "Invalid" 5138 "Invalid" 5137 "Invalid" 5136 "Invalid" 5135 "Invalid" 5134 "Invalid" 5133 "Invalid" 5132 "Invalid" 5131 "Invalid" 5130 "Invalid" 5129 "Invalid" 5128 "Invalid" 5127 "Invalid" 5126 "Invalid" 5125 "Invalid" 5124 "Invalid" 5123 "Invalid" 5122 "Invalid" 5121 "Invalid" 5120 "Invalid" 5119 "Invalid" 5118 "Invalid" 5117 "Invalid" 5116 "Invalid" 5115 "Invalid" 5114 "Invalid" 5113 "Invalid" 5112 "Invalid" 5111 "Invalid" 5110 "Invalid" 5109 "Invalid" 5108 "Invalid" 5107 "Invalid" 5106 "Invalid" 5105 "Invalid" 5104 "Invalid" 5103 "Invalid" 5102 "Invalid" 5101 "Invalid" 5100 "Invalid" 5099 "Invalid" 5098 "Invalid" 5097 "Invalid" 5096 "Invalid" 5095 "Invalid" 5094 "Invalid" 5093 "Invalid" 5092 "Invalid" 5091 "Invalid" 5090 "Invalid" 5089 "Invalid" 5088 "Invalid" 5087 "Invalid" 5086 "Invalid" 5085 "Invalid" 5084 "Invalid" 5083 "Invalid" 5082 "Invalid" 5081 "Invalid" 5080 "Invalid" 5079 "Invalid" 5078 "Invalid" 5077 "Invalid" 5076 "Invalid" 5075 "Invalid" 5074 "Invalid" 5073 "Invalid" 5072 "Invalid" 5071 "Invalid" 5070 "Invalid" 5069 "Invalid" 5068 "Invalid" 5067 "Invalid" 5066 "Invalid" 5065 "Invalid" 5064 "Invalid" 5063 "Invalid" 5062 "Invalid" 5061 "Invalid" 5060 "Invalid" 5059 "Invalid" 5058 "Invalid" 5057 "Invalid" 5056 "Invalid" 5055 "Invalid" 5054 "Invalid" 5053 "Invalid" 5052 "Invalid" 5051 "Invalid" 5050 "Invalid" 5049 "Invalid" 5048 "Invalid" 5047 "Invalid" 5046 "Invalid" 5045 "Invalid" 5044 "Invalid" 5043 "Invalid" 5042 "Invalid" 5041 "Invalid" 5040 "Invalid" 5039 "Invalid" 5038 "Invalid" 5037 "Invalid" 5036 "Invalid" 5035 "Invalid" 5034 "Invalid" 5033 "Invalid" 5032 "Invalid" 5031 "Invalid" 5030 "Invalid" 5029 "Invalid" 5028 "Invalid" 5027 "Invalid" 5026 "Invalid" 5025 "Invalid" 5024 "Invalid" 5023 "Invalid" 5022 "Invalid" 5021 "Invalid" 5020 "Invalid" 5019 "Invalid" 5018 "Invalid" 5017 "Invalid" 5016 "Invalid" 5015 "Invalid" 5014 "Invalid" 5013 "Invalid" 5012 "Invalid" 5011 "Invalid" 5010 "Invalid" 5009 "Invalid" 5008 "Invalid" 5007 "Invalid" 5006 "Invalid" 5005 "Invalid" 5004 "Invalid" 5003 "Invalid" 5002 "Invalid" 5001 "Invalid" ;
VAL_ 530 BCU_MinCellVlt 8191 "Invalid" 8190 "Invalid" 8189 "Invalid" 8188 "Invalid" 8187 "Invalid" 8186 "Invalid" 8185 "Invalid" 8184 "Invalid" 8183 "Invalid" 8182 "Invalid" 8181 "Invalid" 8180 "Invalid" 8179 "Invalid" 8178 "Invalid" 8177 "Invalid" 8176 "Invalid" 8175 "Invalid" 8174 "Invalid" 8173 "Invalid" 8172 "Invalid" 8171 "Invalid" 8170 "Invalid" 8169 "Invalid" 8168 "Invalid" 8167 "Invalid" 8166 "Invalid" 8165 "Invalid" 8164 "Invalid" 8163 "Invalid" 8162 "Invalid" 8161 "Invalid" 8160 "Invalid" 8159 "Invalid" 8158 "Invalid" 8157 "Invalid" 8156 "Invalid" 8155 "Invalid" 8154 "Invalid" 8153 "Invalid" 8152 "Invalid" 8151 "Invalid" 8150 "Invalid" 8149 "Invalid" 8148 "Invalid" 8147 "Invalid" 8146 "Invalid" 8145 "Invalid" 8144 "Invalid" 8143 "Invalid" 8142 "Invalid" 8141 "Invalid" 8140 "Invalid" 8139 "Invalid" 8138 "Invalid" 8137 "Invalid" 8136 "Invalid" 8135 "Invalid" 8134 "Invalid" 8133 "Invalid" 8132 "Invalid" 8131 "Invalid" 8130 "Invalid" 8129 "Invalid" 8128 "Invalid" 8127 "Invalid" 8126 "Invalid" 8125 "Invalid" 8124 "Invalid" 8123 "Invalid" 8122 "Invalid" 8121 "Invalid" 8120 "Invalid" 8119 "Invalid" 8118 "Invalid" 8117 "Invalid" 8116 "Invalid" 8115 "Invalid" 8114 "Invalid" 8113 "Invalid" 8112 "Invalid" 8111 "Invalid" 8110 "Invalid" 8109 "Invalid" 8108 "Invalid" 8107 "Invalid" 8106 "Invalid" 8105 "Invalid" 8104 "Invalid" 8103 "Invalid" 8102 "Invalid" 8101 "Invalid" 8100 "Invalid" 8099 "Invalid" 8098 "Invalid" 8097 "Invalid" 8096 "Invalid" 8095 "Invalid" 8094 "Invalid" 8093 "Invalid" 8092 "Invalid" 8091 "Invalid" 8090 "Invalid" 8089 "Invalid" 8088 "Invalid" 8087 "Invalid" 8086 "Invalid" 8085 "Invalid" 8084 "Invalid" 8083 "Invalid" 8082 "Invalid" 8081 "Invalid" 8080 "Invalid" 8079 "Invalid" 8078 "Invalid" 8077 "Invalid" 8076 "Invalid" 8075 "Invalid" 8074 "Invalid" 8073 "Invalid" 8072 "Invalid" 8071 "Invalid" 8070 "Invalid" 8069 "Invalid" 8068 "Invalid" 8067 "Invalid" 8066 "Invalid" 8065 "Invalid" 8064 "Invalid" 8063 "Invalid" 8062 "Invalid" 8061 "Invalid" 8060 "Invalid" 8059 "Invalid" 8058 "Invalid" 8057 "Invalid" 8056 "Invalid" 8055 "Invalid" 8054 "Invalid" 8053 "Invalid" 8052 "Invalid" 8051 "Invalid" 8050 "Invalid" 8049 "Invalid" 8048 "Invalid" 8047 "Invalid" 8046 "Invalid" 8045 "Invalid" 8044 "Invalid" 8043 "Invalid" 8042 "Invalid" 8041 "Invalid" 8040 "Invalid" 8039 "Invalid" 8038 "Invalid" 8037 "Invalid" 8036 "Invalid" 8035 "Invalid" 8034 "Invalid" 8033 "Invalid" 8032 "Invalid" 8031 "Invalid" 8030 "Invalid" 8029 "Invalid" 8028 "Invalid" 8027 "Invalid" 8026 "Invalid" 8025 "Invalid" 8024 "Invalid" 8023 "Invalid" 8022 "Invalid" 8021 "Invalid" 8020 "Invalid" 8019 "Invalid" 8018 "Invalid" 8017 "Invalid" 8016 "Invalid" 8015 "Invalid" 8014 "Invalid" 8013 "Invalid" 8012 "Invalid" 8011 "Invalid" 8010 "Invalid" 8009 "Invalid" 8008 "Invalid" 8007 "Invalid" 8006 "Invalid" 8005 "Invalid" 8004 "Invalid" 8003 "Invalid" 8002 "Invalid" 8001 "Invalid" 8000 "Invalid" 7999 "Invalid" 7998 "Invalid" 7997 "Invalid" 7996 "Invalid" 7995 "Invalid" 7994 "Invalid" 7993 "Invalid" 7992 "Invalid" 7991 "Invalid" 7990 "Invalid" 7989 "Invalid" 7988 "Invalid" 7987 "Invalid" 7986 "Invalid" 7985 "Invalid" 7984 "Invalid" 7983 "Invalid" 7982 "Invalid" 7981 "Invalid" 7980 "Invalid" 7979 "Invalid" 7978 "Invalid" 7977 "Invalid" 7976 "Invalid" 7975 "Invalid" 7974 "Invalid" 7973 "Invalid" 7972 "Invalid" 7971 "Invalid" 7970 "Invalid" 7969 "Invalid" 7968 "Invalid" 7967 "Invalid" 7966 "Invalid" 7965 "Invalid" 7964 "Invalid" 7963 "Invalid" 7962 "Invalid" 7961 "Invalid" 7960 "Invalid" 7959 "Invalid" 7958 "Invalid" 7957 "Invalid" 7956 "Invalid" 7955 "Invalid" 7954 "Invalid" 7953 "Invalid" 7952 "Invalid" 7951 "Invalid" 7950 "Invalid" 7949 "Invalid" 7948 "Invalid" 7947 "Invalid" 7946 "Invalid" 7945 "Invalid" 7944 "Invalid" 7943 "Invalid" 7942 "Invalid" 7941 "Invalid" 7940 "Invalid" 7939 "Invalid" 7938 "Invalid" 7937 "Invalid" 7936 "Invalid" 7935 "Invalid" 7934 "Invalid" 7933 "Invalid" 7932 "Invalid" 7931 "Invalid" 7930 "Invalid" 7929 "Invalid" 7928 "Invalid" 7927 "Invalid" 7926 "Invalid" 7925 "Invalid" 7924 "Invalid" 7923 "Invalid" 7922 "Invalid" 7921 "Invalid" 7920 "Invalid" 7919 "Invalid" 7918 "Invalid" 7917 "Invalid" 7916 "Invalid" 7915 "Invalid" 7914 "Invalid" 7913 "Invalid" 7912 "Invalid" 7911 "Invalid" 7910 "Invalid" 7909 "Invalid" 7908 "Invalid" 7907 "Invalid" 7906 "Invalid" 7905 "Invalid" 7904 "Invalid" 7903 "Invalid" 7902 "Invalid" 7901 "Invalid" 7900 "Invalid" 7899 "Invalid" 7898 "Invalid" 7897 "Invalid" 7896 "Invalid" 7895 "Invalid" 7894 "Invalid" 7893 "Invalid" 7892 "Invalid" 7891 "Invalid" 7890 "Invalid" 7889 "Invalid" 7888 "Invalid" 7887 "Invalid" 7886 "Invalid" 7885 "Invalid" 7884 "Invalid" 7883 "Invalid" 7882 "Invalid" 7881 "Invalid" 7880 "Invalid" 7879 "Invalid" 7878 "Invalid" 7877 "Invalid" 7876 "Invalid" 7875 "Invalid" 7874 "Invalid" 7873 "Invalid" 7872 "Invalid" 7871 "Invalid" 7870 "Invalid" 7869 "Invalid" 7868 "Invalid" 7867 "Invalid" 7866 "Invalid" 7865 "Invalid" 7864 "Invalid" 7863 "Invalid" 7862 "Invalid" 7861 "Invalid" 7860 "Invalid" 7859 "Invalid" 7858 "Invalid" 7857 "Invalid" 7856 "Invalid" 7855 "Invalid" 7854 "Invalid" 7853 "Invalid" 7852 "Invalid" 7851 "Invalid" 7850 "Invalid" 7849 "Invalid" 7848 "Invalid" 7847 "Invalid" 7846 "Invalid" 7845 "Invalid" 7844 "Invalid" 7843 "Invalid" 7842 "Invalid" 7841 "Invalid" 7840 "Invalid" 7839 "Invalid" 7838 "Invalid" 7837 "Invalid" 7836 "Invalid" 7835 "Invalid" 7834 "Invalid" 7833 "Invalid" 7832 "Invalid" 7831 "Invalid" 7830 "Invalid" 7829 "Invalid" 7828 "Invalid" 7827 "Invalid" 7826 "Invalid" 7825 "Invalid" 7824 "Invalid" 7823 "Invalid" 7822 "Invalid" 7821 "Invalid" 7820 "Invalid" 7819 "Invalid" 7818 "Invalid" 7817 "Invalid" 7816 "Invalid" 7815 "Invalid" 7814 "Invalid" 7813 "Invalid" 7812 "Invalid" 7811 "Invalid" 7810 "Invalid" 7809 "Invalid" 7808 "Invalid" 7807 "Invalid" 7806 "Invalid" 7805 "Invalid" 7804 "Invalid" 7803 "Invalid" 7802 "Invalid" 7801 "Invalid" 7800 "Invalid" 7799 "Invalid" 7798 "Invalid" 7797 "Invalid" 7796 "Invalid" 7795 "Invalid" 7794 "Invalid" 7793 "Invalid" 7792 "Invalid" 7791 "Invalid" 7790 "Invalid" 7789 "Invalid" 7788 "Invalid" 7787 "Invalid" 7786 "Invalid" 7785 "Invalid" 7784 "Invalid" 7783 "Invalid" 7782 "Invalid" 7781 "Invalid" 7780 "Invalid" 7779 "Invalid" 7778 "Invalid" 7777 "Invalid" 7776 "Invalid" 7775 "Invalid" 7774 "Invalid" 7773 "Invalid" 7772 "Invalid" 7771 "Invalid" 7770 "Invalid" 7769 "Invalid" 7768 "Invalid" 7767 "Invalid" 7766 "Invalid" 7765 "Invalid" 7764 "Invalid" 7763 "Invalid" 7762 "Invalid" 7761 "Invalid" 7760 "Invalid" 7759 "Invalid" 7758 "Invalid" 7757 "Invalid" 7756 "Invalid" 7755 "Invalid" 7754 "Invalid" 7753 "Invalid" 7752 "Invalid" 7751 "Invalid" 7750 "Invalid" 7749 "Invalid" 7748 "Invalid" 7747 "Invalid" 7746 "Invalid" 7745 "Invalid" 7744 "Invalid" 7743 "Invalid" 7742 "Invalid" 7741 "Invalid" 7740 "Invalid" 7739 "Invalid" 7738 "Invalid" 7737 "Invalid" 7736 "Invalid" 7735 "Invalid" 7734 "Invalid" 7733 "Invalid" 7732 "Invalid" 7731 "Invalid" 7730 "Invalid" 7729 "Invalid" 7728 "Invalid" 7727 "Invalid" 7726 "Invalid" 7725 "Invalid" 7724 "Invalid" 7723 "Invalid" 7722 "Invalid" 7721 "Invalid" 7720 "Invalid" 7719 "Invalid" 7718 "Invalid" 7717 "Invalid" 7716 "Invalid" 7715 "Invalid" 7714 "Invalid" 7713 "Invalid" 7712 "Invalid" 7711 "Invalid" 7710 "Invalid" 7709 "Invalid" 7708 "Invalid" 7707 "Invalid" 7706 "Invalid" 7705 "Invalid" 7704 "Invalid" 7703 "Invalid" 7702 "Invalid" 7701 "Invalid" 7700 "Invalid" 7699 "Invalid" 7698 "Invalid" 7697 "Invalid" 7696 "Invalid" 7695 "Invalid" 7694 "Invalid" 7693 "Invalid" 7692 "Invalid" 7691 "Invalid" 7690 "Invalid" 7689 "Invalid" 7688 "Invalid" 7687 "Invalid" 7686 "Invalid" 7685 "Invalid" 7684 "Invalid" 7683 "Invalid" 7682 "Invalid" 7681 "Invalid" 7680 "Invalid" 7679 "Invalid" 7678 "Invalid" 7677 "Invalid" 7676 "Invalid" 7675 "Invalid" 7674 "Invalid" 7673 "Invalid" 7672 "Invalid" 7671 "Invalid" 7670 "Invalid" 7669 "Invalid" 7668 "Invalid" 7667 "Invalid" 7666 "Invalid" 7665 "Invalid" 7664 "Invalid" 7663 "Invalid" 7662 "Invalid" 7661 "Invalid" 7660 "Invalid" 7659 "Invalid" 7658 "Invalid" 7657 "Invalid" 7656 "Invalid" 7655 "Invalid" 7654 "Invalid" 7653 "Invalid" 7652 "Invalid" 7651 "Invalid" 7650 "Invalid" 7649 "Invalid" 7648 "Invalid" 7647 "Invalid" 7646 "Invalid" 7645 "Invalid" 7644 "Invalid" 7643 "Invalid" 7642 "Invalid" 7641 "Invalid" 7640 "Invalid" 7639 "Invalid" 7638 "Invalid" 7637 "Invalid" 7636 "Invalid" 7635 "Invalid" 7634 "Invalid" 7633 "Invalid" 7632 "Invalid" 7631 "Invalid" 7630 "Invalid" 7629 "Invalid" 7628 "Invalid" 7627 "Invalid" 7626 "Invalid" 7625 "Invalid" 7624 "Invalid" 7623 "Invalid" 7622 "Invalid" 7621 "Invalid" 7620 "Invalid" 7619 "Invalid" 7618 "Invalid" 7617 "Invalid" 7616 "Invalid" 7615 "Invalid" 7614 "Invalid" 7613 "Invalid" 7612 "Invalid" 7611 "Invalid" 7610 "Invalid" 7609 "Invalid" 7608 "Invalid" 7607 "Invalid" 7606 "Invalid" 7605 "Invalid" 7604 "Invalid" 7603 "Invalid" 7602 "Invalid" 7601 "Invalid" 7600 "Invalid" 7599 "Invalid" 7598 "Invalid" 7597 "Invalid" 7596 "Invalid" 7595 "Invalid" 7594 "Invalid" 7593 "Invalid" 7592 "Invalid" 7591 "Invalid" 7590 "Invalid" 7589 "Invalid" 7588 "Invalid" 7587 "Invalid" 7586 "Invalid" 7585 "Invalid" 7584 "Invalid" 7583 "Invalid" 7582 "Invalid" 7581 "Invalid" 7580 "Invalid" 7579 "Invalid" 7578 "Invalid" 7577 "Invalid" 7576 "Invalid" 7575 "Invalid" 7574 "Invalid" 7573 "Invalid" 7572 "Invalid" 7571 "Invalid" 7570 "Invalid" 7569 "Invalid" 7568 "Invalid" 7567 "Invalid" 7566 "Invalid" 7565 "Invalid" 7564 "Invalid" 7563 "Invalid" 7562 "Invalid" 7561 "Invalid" 7560 "Invalid" 7559 "Invalid" 7558 "Invalid" 7557 "Invalid" 7556 "Invalid" 7555 "Invalid" 7554 "Invalid" 7553 "Invalid" 7552 "Invalid" 7551 "Invalid" 7550 "Invalid" 7549 "Invalid" 7548 "Invalid" 7547 "Invalid" 7546 "Invalid" 7545 "Invalid" 7544 "Invalid" 7543 "Invalid" 7542 "Invalid" 7541 "Invalid" 7540 "Invalid" 7539 "Invalid" 7538 "Invalid" 7537 "Invalid" 7536 "Invalid" 7535 "Invalid" 7534 "Invalid" 7533 "Invalid" 7532 "Invalid" 7531 "Invalid" 7530 "Invalid" 7529 "Invalid" 7528 "Invalid" 7527 "Invalid" 7526 "Invalid" 7525 "Invalid" 7524 "Invalid" 7523 "Invalid" 7522 "Invalid" 7521 "Invalid" 7520 "Invalid" 7519 "Invalid" 7518 "Invalid" 7517 "Invalid" 7516 "Invalid" 7515 "Invalid" 7514 "Invalid" 7513 "Invalid" 7512 "Invalid" 7511 "Invalid" 7510 "Invalid" 7509 "Invalid" 7508 "Invalid" 7507 "Invalid" 7506 "Invalid" 7505 "Invalid" 7504 "Invalid" 7503 "Invalid" 7502 "Invalid" 7501 "Invalid" 7500 "Invalid" 7499 "Invalid" 7498 "Invalid" 7497 "Invalid" 7496 "Invalid" 7495 "Invalid" 7494 "Invalid" 7493 "Invalid" 7492 "Invalid" 7491 "Invalid" 7490 "Invalid" 7489 "Invalid" 7488 "Invalid" 7487 "Invalid" 7486 "Invalid" 7485 "Invalid" 7484 "Invalid" 7483 "Invalid" 7482 "Invalid" 7481 "Invalid" 7480 "Invalid" 7479 "Invalid" 7478 "Invalid" 7477 "Invalid" 7476 "Invalid" 7475 "Invalid" 7474 "Invalid" 7473 "Invalid" 7472 "Invalid" 7471 "Invalid" 7470 "Invalid" 7469 "Invalid" 7468 "Invalid" 7467 "Invalid" 7466 "Invalid" 7465 "Invalid" 7464 "Invalid" 7463 "Invalid" 7462 "Invalid" 7461 "Invalid" 7460 "Invalid" 7459 "Invalid" 7458 "Invalid" 7457 "Invalid" 7456 "Invalid" 7455 "Invalid" 7454 "Invalid" 7453 "Invalid" 7452 "Invalid" 7451 "Invalid" 7450 "Invalid" 7449 "Invalid" 7448 "Invalid" 7447 "Invalid" 7446 "Invalid" 7445 "Invalid" 7444 "Invalid" 7443 "Invalid" 7442 "Invalid" 7441 "Invalid" 7440 "Invalid" 7439 "Invalid" 7438 "Invalid" 7437 "Invalid" 7436 "Invalid" 7435 "Invalid" 7434 "Invalid" 7433 "Invalid" 7432 "Invalid" 7431 "Invalid" 7430 "Invalid" 7429 "Invalid" 7428 "Invalid" 7427 "Invalid" 7426 "Invalid" 7425 "Invalid" 7424 "Invalid" 7423 "Invalid" 7422 "Invalid" 7421 "Invalid" 7420 "Invalid" 7419 "Invalid" 7418 "Invalid" 7417 "Invalid" 7416 "Invalid" 7415 "Invalid" 7414 "Invalid" 7413 "Invalid" 7412 "Invalid" 7411 "Invalid" 7410 "Invalid" 7409 "Invalid" 7408 "Invalid" 7407 "Invalid" 7406 "Invalid" 7405 "Invalid" 7404 "Invalid" 7403 "Invalid" 7402 "Invalid" 7401 "Invalid" 7400 "Invalid" 7399 "Invalid" 7398 "Invalid" 7397 "Invalid" 7396 "Invalid" 7395 "Invalid" 7394 "Invalid" 7393 "Invalid" 7392 "Invalid" 7391 "Invalid" 7390 "Invalid" 7389 "Invalid" 7388 "Invalid" 7387 "Invalid" 7386 "Invalid" 7385 "Invalid" 7384 "Invalid" 7383 "Invalid" 7382 "Invalid" 7381 "Invalid" 7380 "Invalid" 7379 "Invalid" 7378 "Invalid" 7377 "Invalid" 7376 "Invalid" 7375 "Invalid" 7374 "Invalid" 7373 "Invalid" 7372 "Invalid" 7371 "Invalid" 7370 "Invalid" 7369 "Invalid" 7368 "Invalid" 7367 "Invalid" 7366 "Invalid" 7365 "Invalid" 7364 "Invalid" 7363 "Invalid" 7362 "Invalid" 7361 "Invalid" 7360 "Invalid" 7359 "Invalid" 7358 "Invalid" 7357 "Invalid" 7356 "Invalid" 7355 "Invalid" 7354 "Invalid" 7353 "Invalid" 7352 "Invalid" 7351 "Invalid" 7350 "Invalid" 7349 "Invalid" 7348 "Invalid" 7347 "Invalid" 7346 "Invalid" 7345 "Invalid" 7344 "Invalid" 7343 "Invalid" 7342 "Invalid" 7341 "Invalid" 7340 "Invalid" 7339 "Invalid" 7338 "Invalid" 7337 "Invalid" 7336 "Invalid" 7335 "Invalid" 7334 "Invalid" 7333 "Invalid" 7332 "Invalid" 7331 "Invalid" 7330 "Invalid" 7329 "Invalid" 7328 "Invalid" 7327 "Invalid" 7326 "Invalid" 7325 "Invalid" 7324 "Invalid" 7323 "Invalid" 7322 "Invalid" 7321 "Invalid" 7320 "Invalid" 7319 "Invalid" 7318 "Invalid" 7317 "Invalid" 7316 "Invalid" 7315 "Invalid" 7314 "Invalid" 7313 "Invalid" 7312 "Invalid" 7311 "Invalid" 7310 "Invalid" 7309 "Invalid" 7308 "Invalid" 7307 "Invalid" 7306 "Invalid" 7305 "Invalid" 7304 "Invalid" 7303 "Invalid" 7302 "Invalid" 7301 "Invalid" 7300 "Invalid" 7299 "Invalid" 7298 "Invalid" 7297 "Invalid" 7296 "Invalid" 7295 "Invalid" 7294 "Invalid" 7293 "Invalid" 7292 "Invalid" 7291 "Invalid" 7290 "Invalid" 7289 "Invalid" 7288 "Invalid" 7287 "Invalid" 7286 "Invalid" 7285 "Invalid" 7284 "Invalid" 7283 "Invalid" 7282 "Invalid" 7281 "Invalid" 7280 "Invalid" 7279 "Invalid" 7278 "Invalid" 7277 "Invalid" 7276 "Invalid" 7275 "Invalid" 7274 "Invalid" 7273 "Invalid" 7272 "Invalid" 7271 "Invalid" 7270 "Invalid" 7269 "Invalid" 7268 "Invalid" 7267 "Invalid" 7266 "Invalid" 7265 "Invalid" 7264 "Invalid" 7263 "Invalid" 7262 "Invalid" 7261 "Invalid" 7260 "Invalid" 7259 "Invalid" 7258 "Invalid" 7257 "Invalid" 7256 "Invalid" 7255 "Invalid" 7254 "Invalid" 7253 "Invalid" 7252 "Invalid" 7251 "Invalid" 7250 "Invalid" 7249 "Invalid" 7248 "Invalid" 7247 "Invalid" 7246 "Invalid" 7245 "Invalid" 7244 "Invalid" 7243 "Invalid" 7242 "Invalid" 7241 "Invalid" 7240 "Invalid" 7239 "Invalid" 7238 "Invalid" 7237 "Invalid" 7236 "Invalid" 7235 "Invalid" 7234 "Invalid" 7233 "Invalid" 7232 "Invalid" 7231 "Invalid" 7230 "Invalid" 7229 "Invalid" 7228 "Invalid" 7227 "Invalid" 7226 "Invalid" 7225 "Invalid" 7224 "Invalid" 7223 "Invalid" 7222 "Invalid" 7221 "Invalid" 7220 "Invalid" 7219 "Invalid" 7218 "Invalid" 7217 "Invalid" 7216 "Invalid" 7215 "Invalid" 7214 "Invalid" 7213 "Invalid" 7212 "Invalid" 7211 "Invalid" 7210 "Invalid" 7209 "Invalid" 7208 "Invalid" 7207 "Invalid" 7206 "Invalid" 7205 "Invalid" 7204 "Invalid" 7203 "Invalid" 7202 "Invalid" 7201 "Invalid" 7200 "Invalid" 7199 "Invalid" 7198 "Invalid" 7197 "Invalid" 7196 "Invalid" 7195 "Invalid" 7194 "Invalid" 7193 "Invalid" 7192 "Invalid" 7191 "Invalid" 7190 "Invalid" 7189 "Invalid" 7188 "Invalid" 7187 "Invalid" 7186 "Invalid" 7185 "Invalid" 7184 "Invalid" 7183 "Invalid" 7182 "Invalid" 7181 "Invalid" 7180 "Invalid" 7179 "Invalid" 7178 "Invalid" 7177 "Invalid" 7176 "Invalid" 7175 "Invalid" 7174 "Invalid" 7173 "Invalid" 7172 "Invalid" 7171 "Invalid" 7170 "Invalid" 7169 "Invalid" 7168 "Invalid" 7167 "Invalid" 7166 "Invalid" 7165 "Invalid" 7164 "Invalid" 7163 "Invalid" 7162 "Invalid" 7161 "Invalid" 7160 "Invalid" 7159 "Invalid" 7158 "Invalid" 7157 "Invalid" 7156 "Invalid" 7155 "Invalid" 7154 "Invalid" 7153 "Invalid" 7152 "Invalid" 7151 "Invalid" 7150 "Invalid" 7149 "Invalid" 7148 "Invalid" 7147 "Invalid" 7146 "Invalid" 7145 "Invalid" 7144 "Invalid" 7143 "Invalid" 7142 "Invalid" 7141 "Invalid" 7140 "Invalid" 7139 "Invalid" 7138 "Invalid" 7137 "Invalid" 7136 "Invalid" 7135 "Invalid" 7134 "Invalid" 7133 "Invalid" 7132 "Invalid" 7131 "Invalid" 7130 "Invalid" 7129 "Invalid" 7128 "Invalid" 7127 "Invalid" 7126 "Invalid" 7125 "Invalid" 7124 "Invalid" 7123 "Invalid" 7122 "Invalid" 7121 "Invalid" 7120 "Invalid" 7119 "Invalid" 7118 "Invalid" 7117 "Invalid" 7116 "Invalid" 7115 "Invalid" 7114 "Invalid" 7113 "Invalid" 7112 "Invalid" 7111 "Invalid" 7110 "Invalid" 7109 "Invalid" 7108 "Invalid" 7107 "Invalid" 7106 "Invalid" 7105 "Invalid" 7104 "Invalid" 7103 "Invalid" 7102 "Invalid" 7101 "Invalid" 7100 "Invalid" 7099 "Invalid" 7098 "Invalid" 7097 "Invalid" 7096 "Invalid" 7095 "Invalid" 7094 "Invalid" 7093 "Invalid" 7092 "Invalid" 7091 "Invalid" 7090 "Invalid" 7089 "Invalid" 7088 "Invalid" 7087 "Invalid" 7086 "Invalid" 7085 "Invalid" 7084 "Invalid" 7083 "Invalid" 7082 "Invalid" 7081 "Invalid" 7080 "Invalid" 7079 "Invalid" 7078 "Invalid" 7077 "Invalid" 7076 "Invalid" 7075 "Invalid" 7074 "Invalid" 7073 "Invalid" 7072 "Invalid" 7071 "Invalid" 7070 "Invalid" 7069 "Invalid" 7068 "Invalid" 7067 "Invalid" 7066 "Invalid" 7065 "Invalid" 7064 "Invalid" 7063 "Invalid" 7062 "Invalid" 7061 "Invalid" 7060 "Invalid" 7059 "Invalid" 7058 "Invalid" 7057 "Invalid" 7056 "Invalid" 7055 "Invalid" 7054 "Invalid" 7053 "Invalid" 7052 "Invalid" 7051 "Invalid" 7050 "Invalid" 7049 "Invalid" 7048 "Invalid" 7047 "Invalid" 7046 "Invalid" 7045 "Invalid" 7044 "Invalid" 7043 "Invalid" 7042 "Invalid" 7041 "Invalid" 7040 "Invalid" 7039 "Invalid" 7038 "Invalid" 7037 "Invalid" 7036 "Invalid" 7035 "Invalid" 7034 "Invalid" 7033 "Invalid" 7032 "Invalid" 7031 "Invalid" 7030 "Invalid" 7029 "Invalid" 7028 "Invalid" 7027 "Invalid" 7026 "Invalid" 7025 "Invalid" 7024 "Invalid" 7023 "Invalid" 7022 "Invalid" 7021 "Invalid" 7020 "Invalid" 7019 "Invalid" 7018 "Invalid" 7017 "Invalid" 7016 "Invalid" 7015 "Invalid" 7014 "Invalid" 7013 "Invalid" 7012 "Invalid" 7011 "Invalid" 7010 "Invalid" 7009 "Invalid" 7008 "Invalid" 7007 "Invalid" 7006 "Invalid" 7005 "Invalid" 7004 "Invalid" 7003 "Invalid" 7002 "Invalid" 7001 "Invalid" 7000 "Invalid" 6999 "Invalid" 6998 "Invalid" 6997 "Invalid" 6996 "Invalid" 6995 "Invalid" 6994 "Invalid" 6993 "Invalid" 6992 "Invalid" 6991 "Invalid" 6990 "Invalid" 6989 "Invalid" 6988 "Invalid" 6987 "Invalid" 6986 "Invalid" 6985 "Invalid" 6984 "Invalid" 6983 "Invalid" 6982 "Invalid" 6981 "Invalid" 6980 "Invalid" 6979 "Invalid" 6978 "Invalid" 6977 "Invalid" 6976 "Invalid" 6975 "Invalid" 6974 "Invalid" 6973 "Invalid" 6972 "Invalid" 6971 "Invalid" 6970 "Invalid" 6969 "Invalid" 6968 "Invalid" 6967 "Invalid" 6966 "Invalid" 6965 "Invalid" 6964 "Invalid" 6963 "Invalid" 6962 "Invalid" 6961 "Invalid" 6960 "Invalid" 6959 "Invalid" 6958 "Invalid" 6957 "Invalid" 6956 "Invalid" 6955 "Invalid" 6954 "Invalid" 6953 "Invalid" 6952 "Invalid" 6951 "Invalid" 6950 "Invalid" 6949 "Invalid" 6948 "Invalid" 6947 "Invalid" 6946 "Invalid" 6945 "Invalid" 6944 "Invalid" 6943 "Invalid" 6942 "Invalid" 6941 "Invalid" 6940 "Invalid" 6939 "Invalid" 6938 "Invalid" 6937 "Invalid" 6936 "Invalid" 6935 "Invalid" 6934 "Invalid" 6933 "Invalid" 6932 "Invalid" 6931 "Invalid" 6930 "Invalid" 6929 "Invalid" 6928 "Invalid" 6927 "Invalid" 6926 "Invalid" 6925 "Invalid" 6924 "Invalid" 6923 "Invalid" 6922 "Invalid" 6921 "Invalid" 6920 "Invalid" 6919 "Invalid" 6918 "Invalid" 6917 "Invalid" 6916 "Invalid" 6915 "Invalid" 6914 "Invalid" 6913 "Invalid" 6912 "Invalid" 6911 "Invalid" 6910 "Invalid" 6909 "Invalid" 6908 "Invalid" 6907 "Invalid" 6906 "Invalid" 6905 "Invalid" 6904 "Invalid" 6903 "Invalid" 6902 "Invalid" 6901 "Invalid" 6900 "Invalid" 6899 "Invalid" 6898 "Invalid" 6897 "Invalid" 6896 "Invalid" 6895 "Invalid" 6894 "Invalid" 6893 "Invalid" 6892 "Invalid" 6891 "Invalid" 6890 "Invalid" 6889 "Invalid" 6888 "Invalid" 6887 "Invalid" 6886 "Invalid" 6885 "Invalid" 6884 "Invalid" 6883 "Invalid" 6882 "Invalid" 6881 "Invalid" 6880 "Invalid" 6879 "Invalid" 6878 "Invalid" 6877 "Invalid" 6876 "Invalid" 6875 "Invalid" 6874 "Invalid" 6873 "Invalid" 6872 "Invalid" 6871 "Invalid" 6870 "Invalid" 6869 "Invalid" 6868 "Invalid" 6867 "Invalid" 6866 "Invalid" 6865 "Invalid" 6864 "Invalid" 6863 "Invalid" 6862 "Invalid" 6861 "Invalid" 6860 "Invalid" 6859 "Invalid" 6858 "Invalid" 6857 "Invalid" 6856 "Invalid" 6855 "Invalid" 6854 "Invalid" 6853 "Invalid" 6852 "Invalid" 6851 "Invalid" 6850 "Invalid" 6849 "Invalid" 6848 "Invalid" 6847 "Invalid" 6846 "Invalid" 6845 "Invalid" 6844 "Invalid" 6843 "Invalid" 6842 "Invalid" 6841 "Invalid" 6840 "Invalid" 6839 "Invalid" 6838 "Invalid" 6837 "Invalid" 6836 "Invalid" 6835 "Invalid" 6834 "Invalid" 6833 "Invalid" 6832 "Invalid" 6831 "Invalid" 6830 "Invalid" 6829 "Invalid" 6828 "Invalid" 6827 "Invalid" 6826 "Invalid" 6825 "Invalid" 6824 "Invalid" 6823 "Invalid" 6822 "Invalid" 6821 "Invalid" 6820 "Invalid" 6819 "Invalid" 6818 "Invalid" 6817 "Invalid" 6816 "Invalid" 6815 "Invalid" 6814 "Invalid" 6813 "Invalid" 6812 "Invalid" 6811 "Invalid" 6810 "Invalid" 6809 "Invalid" 6808 "Invalid" 6807 "Invalid" 6806 "Invalid" 6805 "Invalid" 6804 "Invalid" 6803 "Invalid" 6802 "Invalid" 6801 "Invalid" 6800 "Invalid" 6799 "Invalid" 6798 "Invalid" 6797 "Invalid" 6796 "Invalid" 6795 "Invalid" 6794 "Invalid" 6793 "Invalid" 6792 "Invalid" 6791 "Invalid" 6790 "Invalid" 6789 "Invalid" 6788 "Invalid" 6787 "Invalid" 6786 "Invalid" 6785 "Invalid" 6784 "Invalid" 6783 "Invalid" 6782 "Invalid" 6781 "Invalid" 6780 "Invalid" 6779 "Invalid" 6778 "Invalid" 6777 "Invalid" 6776 "Invalid" 6775 "Invalid" 6774 "Invalid" 6773 "Invalid" 6772 "Invalid" 6771 "Invalid" 6770 "Invalid" 6769 "Invalid" 6768 "Invalid" 6767 "Invalid" 6766 "Invalid" 6765 "Invalid" 6764 "Invalid" 6763 "Invalid" 6762 "Invalid" 6761 "Invalid" 6760 "Invalid" 6759 "Invalid" 6758 "Invalid" 6757 "Invalid" 6756 "Invalid" 6755 "Invalid" 6754 "Invalid" 6753 "Invalid" 6752 "Invalid" 6751 "Invalid" 6750 "Invalid" 6749 "Invalid" 6748 "Invalid" 6747 "Invalid" 6746 "Invalid" 6745 "Invalid" 6744 "Invalid" 6743 "Invalid" 6742 "Invalid" 6741 "Invalid" 6740 "Invalid" 6739 "Invalid" 6738 "Invalid" 6737 "Invalid" 6736 "Invalid" 6735 "Invalid" 6734 "Invalid" 6733 "Invalid" 6732 "Invalid" 6731 "Invalid" 6730 "Invalid" 6729 "Invalid" 6728 "Invalid" 6727 "Invalid" 6726 "Invalid" 6725 "Invalid" 6724 "Invalid" 6723 "Invalid" 6722 "Invalid" 6721 "Invalid" 6720 "Invalid" 6719 "Invalid" 6718 "Invalid" 6717 "Invalid" 6716 "Invalid" 6715 "Invalid" 6714 "Invalid" 6713 "Invalid" 6712 "Invalid" 6711 "Invalid" 6710 "Invalid" 6709 "Invalid" 6708 "Invalid" 6707 "Invalid" 6706 "Invalid" 6705 "Invalid" 6704 "Invalid" 6703 "Invalid" 6702 "Invalid" 6701 "Invalid" 6700 "Invalid" 6699 "Invalid" 6698 "Invalid" 6697 "Invalid" 6696 "Invalid" 6695 "Invalid" 6694 "Invalid" 6693 "Invalid" 6692 "Invalid" 6691 "Invalid" 6690 "Invalid" 6689 "Invalid" 6688 "Invalid" 6687 "Invalid" 6686 "Invalid" 6685 "Invalid" 6684 "Invalid" 6683 "Invalid" 6682 "Invalid" 6681 "Invalid" 6680 "Invalid" 6679 "Invalid" 6678 "Invalid" 6677 "Invalid" 6676 "Invalid" 6675 "Invalid" 6674 "Invalid" 6673 "Invalid" 6672 "Invalid" 6671 "Invalid" 6670 "Invalid" 6669 "Invalid" 6668 "Invalid" 6667 "Invalid" 6666 "Invalid" 6665 "Invalid" 6664 "Invalid" 6663 "Invalid" 6662 "Invalid" 6661 "Invalid" 6660 "Invalid" 6659 "Invalid" 6658 "Invalid" 6657 "Invalid" 6656 "Invalid" 6655 "Invalid" 6654 "Invalid" 6653 "Invalid" 6652 "Invalid" 6651 "Invalid" 6650 "Invalid" 6649 "Invalid" 6648 "Invalid" 6647 "Invalid" 6646 "Invalid" 6645 "Invalid" 6644 "Invalid" 6643 "Invalid" 6642 "Invalid" 6641 "Invalid" 6640 "Invalid" 6639 "Invalid" 6638 "Invalid" 6637 "Invalid" 6636 "Invalid" 6635 "Invalid" 6634 "Invalid" 6633 "Invalid" 6632 "Invalid" 6631 "Invalid" 6630 "Invalid" 6629 "Invalid" 6628 "Invalid" 6627 "Invalid" 6626 "Invalid" 6625 "Invalid" 6624 "Invalid" 6623 "Invalid" 6622 "Invalid" 6621 "Invalid" 6620 "Invalid" 6619 "Invalid" 6618 "Invalid" 6617 "Invalid" 6616 "Invalid" 6615 "Invalid" 6614 "Invalid" 6613 "Invalid" 6612 "Invalid" 6611 "Invalid" 6610 "Invalid" 6609 "Invalid" 6608 "Invalid" 6607 "Invalid" 6606 "Invalid" 6605 "Invalid" 6604 "Invalid" 6603 "Invalid" 6602 "Invalid" 6601 "Invalid" 6600 "Invalid" 6599 "Invalid" 6598 "Invalid" 6597 "Invalid" 6596 "Invalid" 6595 "Invalid" 6594 "Invalid" 6593 "Invalid" 6592 "Invalid" 6591 "Invalid" 6590 "Invalid" 6589 "Invalid" 6588 "Invalid" 6587 "Invalid" 6586 "Invalid" 6585 "Invalid" 6584 "Invalid" 6583 "Invalid" 6582 "Invalid" 6581 "Invalid" 6580 "Invalid" 6579 "Invalid" 6578 "Invalid" 6577 "Invalid" 6576 "Invalid" 6575 "Invalid" 6574 "Invalid" 6573 "Invalid" 6572 "Invalid" 6571 "Invalid" 6570 "Invalid" 6569 "Invalid" 6568 "Invalid" 6567 "Invalid" 6566 "Invalid" 6565 "Invalid" 6564 "Invalid" 6563 "Invalid" 6562 "Invalid" 6561 "Invalid" 6560 "Invalid" 6559 "Invalid" 6558 "Invalid" 6557 "Invalid" 6556 "Invalid" 6555 "Invalid" 6554 "Invalid" 6553 "Invalid" 6552 "Invalid" 6551 "Invalid" 6550 "Invalid" 6549 "Invalid" 6548 "Invalid" 6547 "Invalid" 6546 "Invalid" 6545 "Invalid" 6544 "Invalid" 6543 "Invalid" 6542 "Invalid" 6541 "Invalid" 6540 "Invalid" 6539 "Invalid" 6538 "Invalid" 6537 "Invalid" 6536 "Invalid" 6535 "Invalid" 6534 "Invalid" 6533 "Invalid" 6532 "Invalid" 6531 "Invalid" 6530 "Invalid" 6529 "Invalid" 6528 "Invalid" 6527 "Invalid" 6526 "Invalid" 6525 "Invalid" 6524 "Invalid" 6523 "Invalid" 6522 "Invalid" 6521 "Invalid" 6520 "Invalid" 6519 "Invalid" 6518 "Invalid" 6517 "Invalid" 6516 "Invalid" 6515 "Invalid" 6514 "Invalid" 6513 "Invalid" 6512 "Invalid" 6511 "Invalid" 6510 "Invalid" 6509 "Invalid" 6508 "Invalid" 6507 "Invalid" 6506 "Invalid" 6505 "Invalid" 6504 "Invalid" 6503 "Invalid" 6502 "Invalid" 6501 "Invalid" 6500 "Invalid" 6499 "Invalid" 6498 "Invalid" 6497 "Invalid" 6496 "Invalid" 6495 "Invalid" 6494 "Invalid" 6493 "Invalid" 6492 "Invalid" 6491 "Invalid" 6490 "Invalid" 6489 "Invalid" 6488 "Invalid" 6487 "Invalid" 6486 "Invalid" 6485 "Invalid" 6484 "Invalid" 6483 "Invalid" 6482 "Invalid" 6481 "Invalid" 6480 "Invalid" 6479 "Invalid" 6478 "Invalid" 6477 "Invalid" 6476 "Invalid" 6475 "Invalid" 6474 "Invalid" 6473 "Invalid" 6472 "Invalid" 6471 "Invalid" 6470 "Invalid" 6469 "Invalid" 6468 "Invalid" 6467 "Invalid" 6466 "Invalid" 6465 "Invalid" 6464 "Invalid" 6463 "Invalid" 6462 "Invalid" 6461 "Invalid" 6460 "Invalid" 6459 "Invalid" 6458 "Invalid" 6457 "Invalid" 6456 "Invalid" 6455 "Invalid" 6454 "Invalid" 6453 "Invalid" 6452 "Invalid" 6451 "Invalid" 6450 "Invalid" 6449 "Invalid" 6448 "Invalid" 6447 "Invalid" 6446 "Invalid" 6445 "Invalid" 6444 "Invalid" 6443 "Invalid" 6442 "Invalid" 6441 "Invalid" 6440 "Invalid" 6439 "Invalid" 6438 "Invalid" 6437 "Invalid" 6436 "Invalid" 6435 "Invalid" 6434 "Invalid" 6433 "Invalid" 6432 "Invalid" 6431 "Invalid" 6430 "Invalid" 6429 "Invalid" 6428 "Invalid" 6427 "Invalid" 6426 "Invalid" 6425 "Invalid" 6424 "Invalid" 6423 "Invalid" 6422 "Invalid" 6421 "Invalid" 6420 "Invalid" 6419 "Invalid" 6418 "Invalid" 6417 "Invalid" 6416 "Invalid" 6415 "Invalid" 6414 "Invalid" 6413 "Invalid" 6412 "Invalid" 6411 "Invalid" 6410 "Invalid" 6409 "Invalid" 6408 "Invalid" 6407 "Invalid" 6406 "Invalid" 6405 "Invalid" 6404 "Invalid" 6403 "Invalid" 6402 "Invalid" 6401 "Invalid" 6400 "Invalid" 6399 "Invalid" 6398 "Invalid" 6397 "Invalid" 6396 "Invalid" 6395 "Invalid" 6394 "Invalid" 6393 "Invalid" 6392 "Invalid" 6391 "Invalid" 6390 "Invalid" 6389 "Invalid" 6388 "Invalid" 6387 "Invalid" 6386 "Invalid" 6385 "Invalid" 6384 "Invalid" 6383 "Invalid" 6382 "Invalid" 6381 "Invalid" 6380 "Invalid" 6379 "Invalid" 6378 "Invalid" 6377 "Invalid" 6376 "Invalid" 6375 "Invalid" 6374 "Invalid" 6373 "Invalid" 6372 "Invalid" 6371 "Invalid" 6370 "Invalid" 6369 "Invalid" 6368 "Invalid" 6367 "Invalid" 6366 "Invalid" 6365 "Invalid" 6364 "Invalid" 6363 "Invalid" 6362 "Invalid" 6361 "Invalid" 6360 "Invalid" 6359 "Invalid" 6358 "Invalid" 6357 "Invalid" 6356 "Invalid" 6355 "Invalid" 6354 "Invalid" 6353 "Invalid" 6352 "Invalid" 6351 "Invalid" 6350 "Invalid" 6349 "Invalid" 6348 "Invalid" 6347 "Invalid" 6346 "Invalid" 6345 "Invalid" 6344 "Invalid" 6343 "Invalid" 6342 "Invalid" 6341 "Invalid" 6340 "Invalid" 6339 "Invalid" 6338 "Invalid" 6337 "Invalid" 6336 "Invalid" 6335 "Invalid" 6334 "Invalid" 6333 "Invalid" 6332 "Invalid" 6331 "Invalid" 6330 "Invalid" 6329 "Invalid" 6328 "Invalid" 6327 "Invalid" 6326 "Invalid" 6325 "Invalid" 6324 "Invalid" 6323 "Invalid" 6322 "Invalid" 6321 "Invalid" 6320 "Invalid" 6319 "Invalid" 6318 "Invalid" 6317 "Invalid" 6316 "Invalid" 6315 "Invalid" 6314 "Invalid" 6313 "Invalid" 6312 "Invalid" 6311 "Invalid" 6310 "Invalid" 6309 "Invalid" 6308 "Invalid" 6307 "Invalid" 6306 "Invalid" 6305 "Invalid" 6304 "Invalid" 6303 "Invalid" 6302 "Invalid" 6301 "Invalid" 6300 "Invalid" 6299 "Invalid" 6298 "Invalid" 6297 "Invalid" 6296 "Invalid" 6295 "Invalid" 6294 "Invalid" 6293 "Invalid" 6292 "Invalid" 6291 "Invalid" 6290 "Invalid" 6289 "Invalid" 6288 "Invalid" 6287 "Invalid" 6286 "Invalid" 6285 "Invalid" 6284 "Invalid" 6283 "Invalid" 6282 "Invalid" 6281 "Invalid" 6280 "Invalid" 6279 "Invalid" 6278 "Invalid" 6277 "Invalid" 6276 "Invalid" 6275 "Invalid" 6274 "Invalid" 6273 "Invalid" 6272 "Invalid" 6271 "Invalid" 6270 "Invalid" 6269 "Invalid" 6268 "Invalid" 6267 "Invalid" 6266 "Invalid" 6265 "Invalid" 6264 "Invalid" 6263 "Invalid" 6262 "Invalid" 6261 "Invalid" 6260 "Invalid" 6259 "Invalid" 6258 "Invalid" 6257 "Invalid" 6256 "Invalid" 6255 "Invalid" 6254 "Invalid" 6253 "Invalid" 6252 "Invalid" 6251 "Invalid" 6250 "Invalid" 6249 "Invalid" 6248 "Invalid" 6247 "Invalid" 6246 "Invalid" 6245 "Invalid" 6244 "Invalid" 6243 "Invalid" 6242 "Invalid" 6241 "Invalid" 6240 "Invalid" 6239 "Invalid" 6238 "Invalid" 6237 "Invalid" 6236 "Invalid" 6235 "Invalid" 6234 "Invalid" 6233 "Invalid" 6232 "Invalid" 6231 "Invalid" 6230 "Invalid" 6229 "Invalid" 6228 "Invalid" 6227 "Invalid" 6226 "Invalid" 6225 "Invalid" 6224 "Invalid" 6223 "Invalid" 6222 "Invalid" 6221 "Invalid" 6220 "Invalid" 6219 "Invalid" 6218 "Invalid" 6217 "Invalid" 6216 "Invalid" 6215 "Invalid" 6214 "Invalid" 6213 "Invalid" 6212 "Invalid" 6211 "Invalid" 6210 "Invalid" 6209 "Invalid" 6208 "Invalid" 6207 "Invalid" 6206 "Invalid" 6205 "Invalid" 6204 "Invalid" 6203 "Invalid" 6202 "Invalid" 6201 "Invalid" 6200 "Invalid" 6199 "Invalid" 6198 "Invalid" 6197 "Invalid" 6196 "Invalid" 6195 "Invalid" 6194 "Invalid" 6193 "Invalid" 6192 "Invalid" 6191 "Invalid" 6190 "Invalid" 6189 "Invalid" 6188 "Invalid" 6187 "Invalid" 6186 "Invalid" 6185 "Invalid" 6184 "Invalid" 6183 "Invalid" 6182 "Invalid" 6181 "Invalid" 6180 "Invalid" 6179 "Invalid" 6178 "Invalid" 6177 "Invalid" 6176 "Invalid" 6175 "Invalid" 6174 "Invalid" 6173 "Invalid" 6172 "Invalid" 6171 "Invalid" 6170 "Invalid" 6169 "Invalid" 6168 "Invalid" 6167 "Invalid" 6166 "Invalid" 6165 "Invalid" 6164 "Invalid" 6163 "Invalid" 6162 "Invalid" 6161 "Invalid" 6160 "Invalid" 6159 "Invalid" 6158 "Invalid" 6157 "Invalid" 6156 "Invalid" 6155 "Invalid" 6154 "Invalid" 6153 "Invalid" 6152 "Invalid" 6151 "Invalid" 6150 "Invalid" 6149 "Invalid" 6148 "Invalid" 6147 "Invalid" 6146 "Invalid" 6145 "Invalid" 6144 "Invalid" 6143 "Invalid" 6142 "Invalid" 6141 "Invalid" 6140 "Invalid" 6139 "Invalid" 6138 "Invalid" 6137 "Invalid" 6136 "Invalid" 6135 "Invalid" 6134 "Invalid" 6133 "Invalid" 6132 "Invalid" 6131 "Invalid" 6130 "Invalid" 6129 "Invalid" 6128 "Invalid" 6127 "Invalid" 6126 "Invalid" 6125 "Invalid" 6124 "Invalid" 6123 "Invalid" 6122 "Invalid" 6121 "Invalid" 6120 "Invalid" 6119 "Invalid" 6118 "Invalid" 6117 "Invalid" 6116 "Invalid" 6115 "Invalid" 6114 "Invalid" 6113 "Invalid" 6112 "Invalid" 6111 "Invalid" 6110 "Invalid" 6109 "Invalid" 6108 "Invalid" 6107 "Invalid" 6106 "Invalid" 6105 "Invalid" 6104 "Invalid" 6103 "Invalid" 6102 "Invalid" 6101 "Invalid" 6100 "Invalid" 6099 "Invalid" 6098 "Invalid" 6097 "Invalid" 6096 "Invalid" 6095 "Invalid" 6094 "Invalid" 6093 "Invalid" 6092 "Invalid" 6091 "Invalid" 6090 "Invalid" 6089 "Invalid" 6088 "Invalid" 6087 "Invalid" 6086 "Invalid" 6085 "Invalid" 6084 "Invalid" 6083 "Invalid" 6082 "Invalid" 6081 "Invalid" 6080 "Invalid" 6079 "Invalid" 6078 "Invalid" 6077 "Invalid" 6076 "Invalid" 6075 "Invalid" 6074 "Invalid" 6073 "Invalid" 6072 "Invalid" 6071 "Invalid" 6070 "Invalid" 6069 "Invalid" 6068 "Invalid" 6067 "Invalid" 6066 "Invalid" 6065 "Invalid" 6064 "Invalid" 6063 "Invalid" 6062 "Invalid" 6061 "Invalid" 6060 "Invalid" 6059 "Invalid" 6058 "Invalid" 6057 "Invalid" 6056 "Invalid" 6055 "Invalid" 6054 "Invalid" 6053 "Invalid" 6052 "Invalid" 6051 "Invalid" 6050 "Invalid" 6049 "Invalid" 6048 "Invalid" 6047 "Invalid" 6046 "Invalid" 6045 "Invalid" 6044 "Invalid" 6043 "Invalid" 6042 "Invalid" 6041 "Invalid" 6040 "Invalid" 6039 "Invalid" 6038 "Invalid" 6037 "Invalid" 6036 "Invalid" 6035 "Invalid" 6034 "Invalid" 6033 "Invalid" 6032 "Invalid" 6031 "Invalid" 6030 "Invalid" 6029 "Invalid" 6028 "Invalid" 6027 "Invalid" 6026 "Invalid" 6025 "Invalid" 6024 "Invalid" 6023 "Invalid" 6022 "Invalid" 6021 "Invalid" 6020 "Invalid" 6019 "Invalid" 6018 "Invalid" 6017 "Invalid" 6016 "Invalid" 6015 "Invalid" 6014 "Invalid" 6013 "Invalid" 6012 "Invalid" 6011 "Invalid" 6010 "Invalid" 6009 "Invalid" 6008 "Invalid" 6007 "Invalid" 6006 "Invalid" 6005 "Invalid" 6004 "Invalid" 6003 "Invalid" 6002 "Invalid" 6001 "Invalid" 6000 "Invalid" 5999 "Invalid" 5998 "Invalid" 5997 "Invalid" 5996 "Invalid" 5995 "Invalid" 5994 "Invalid" 5993 "Invalid" 5992 "Invalid" 5991 "Invalid" 5990 "Invalid" 5989 "Invalid" 5988 "Invalid" 5987 "Invalid" 5986 "Invalid" 5985 "Invalid" 5984 "Invalid" 5983 "Invalid" 5982 "Invalid" 5981 "Invalid" 5980 "Invalid" 5979 "Invalid" 5978 "Invalid" 5977 "Invalid" 5976 "Invalid" 5975 "Invalid" 5974 "Invalid" 5973 "Invalid" 5972 "Invalid" 5971 "Invalid" 5970 "Invalid" 5969 "Invalid" 5968 "Invalid" 5967 "Invalid" 5966 "Invalid" 5965 "Invalid" 5964 "Invalid" 5963 "Invalid" 5962 "Invalid" 5961 "Invalid" 5960 "Invalid" 5959 "Invalid" 5958 "Invalid" 5957 "Invalid" 5956 "Invalid" 5955 "Invalid" 5954 "Invalid" 5953 "Invalid" 5952 "Invalid" 5951 "Invalid" 5950 "Invalid" 5949 "Invalid" 5948 "Invalid" 5947 "Invalid" 5946 "Invalid" 5945 "Invalid" 5944 "Invalid" 5943 "Invalid" 5942 "Invalid" 5941 "Invalid" 5940 "Invalid" 5939 "Invalid" 5938 "Invalid" 5937 "Invalid" 5936 "Invalid" 5935 "Invalid" 5934 "Invalid" 5933 "Invalid" 5932 "Invalid" 5931 "Invalid" 5930 "Invalid" 5929 "Invalid" 5928 "Invalid" 5927 "Invalid" 5926 "Invalid" 5925 "Invalid" 5924 "Invalid" 5923 "Invalid" 5922 "Invalid" 5921 "Invalid" 5920 "Invalid" 5919 "Invalid" 5918 "Invalid" 5917 "Invalid" 5916 "Invalid" 5915 "Invalid" 5914 "Invalid" 5913 "Invalid" 5912 "Invalid" 5911 "Invalid" 5910 "Invalid" 5909 "Invalid" 5908 "Invalid" 5907 "Invalid" 5906 "Invalid" 5905 "Invalid" 5904 "Invalid" 5903 "Invalid" 5902 "Invalid" 5901 "Invalid" 5900 "Invalid" 5899 "Invalid" 5898 "Invalid" 5897 "Invalid" 5896 "Invalid" 5895 "Invalid" 5894 "Invalid" 5893 "Invalid" 5892 "Invalid" 5891 "Invalid" 5890 "Invalid" 5889 "Invalid" 5888 "Invalid" 5887 "Invalid" 5886 "Invalid" 5885 "Invalid" 5884 "Invalid" 5883 "Invalid" 5882 "Invalid" 5881 "Invalid" 5880 "Invalid" 5879 "Invalid" 5878 "Invalid" 5877 "Invalid" 5876 "Invalid" 5875 "Invalid" 5874 "Invalid" 5873 "Invalid" 5872 "Invalid" 5871 "Invalid" 5870 "Invalid" 5869 "Invalid" 5868 "Invalid" 5867 "Invalid" 5866 "Invalid" 5865 "Invalid" 5864 "Invalid" 5863 "Invalid" 5862 "Invalid" 5861 "Invalid" 5860 "Invalid" 5859 "Invalid" 5858 "Invalid" 5857 "Invalid" 5856 "Invalid" 5855 "Invalid" 5854 "Invalid" 5853 "Invalid" 5852 "Invalid" 5851 "Invalid" 5850 "Invalid" 5849 "Invalid" 5848 "Invalid" 5847 "Invalid" 5846 "Invalid" 5845 "Invalid" 5844 "Invalid" 5843 "Invalid" 5842 "Invalid" 5841 "Invalid" 5840 "Invalid" 5839 "Invalid" 5838 "Invalid" 5837 "Invalid" 5836 "Invalid" 5835 "Invalid" 5834 "Invalid" 5833 "Invalid" 5832 "Invalid" 5831 "Invalid" 5830 "Invalid" 5829 "Invalid" 5828 "Invalid" 5827 "Invalid" 5826 "Invalid" 5825 "Invalid" 5824 "Invalid" 5823 "Invalid" 5822 "Invalid" 5821 "Invalid" 5820 "Invalid" 5819 "Invalid" 5818 "Invalid" 5817 "Invalid" 5816 "Invalid" 5815 "Invalid" 5814 "Invalid" 5813 "Invalid" 5812 "Invalid" 5811 "Invalid" 5810 "Invalid" 5809 "Invalid" 5808 "Invalid" 5807 "Invalid" 5806 "Invalid" 5805 "Invalid" 5804 "Invalid" 5803 "Invalid" 5802 "Invalid" 5801 "Invalid" 5800 "Invalid" 5799 "Invalid" 5798 "Invalid" 5797 "Invalid" 5796 "Invalid" 5795 "Invalid" 5794 "Invalid" 5793 "Invalid" 5792 "Invalid" 5791 "Invalid" 5790 "Invalid" 5789 "Invalid" 5788 "Invalid" 5787 "Invalid" 5786 "Invalid" 5785 "Invalid" 5784 "Invalid" 5783 "Invalid" 5782 "Invalid" 5781 "Invalid" 5780 "Invalid" 5779 "Invalid" 5778 "Invalid" 5777 "Invalid" 5776 "Invalid" 5775 "Invalid" 5774 "Invalid" 5773 "Invalid" 5772 "Invalid" 5771 "Invalid" 5770 "Invalid" 5769 "Invalid" 5768 "Invalid" 5767 "Invalid" 5766 "Invalid" 5765 "Invalid" 5764 "Invalid" 5763 "Invalid" 5762 "Invalid" 5761 "Invalid" 5760 "Invalid" 5759 "Invalid" 5758 "Invalid" 5757 "Invalid" 5756 "Invalid" 5755 "Invalid" 5754 "Invalid" 5753 "Invalid" 5752 "Invalid" 5751 "Invalid" 5750 "Invalid" 5749 "Invalid" 5748 "Invalid" 5747 "Invalid" 5746 "Invalid" 5745 "Invalid" 5744 "Invalid" 5743 "Invalid" 5742 "Invalid" 5741 "Invalid" 5740 "Invalid" 5739 "Invalid" 5738 "Invalid" 5737 "Invalid" 5736 "Invalid" 5735 "Invalid" 5734 "Invalid" 5733 "Invalid" 5732 "Invalid" 5731 "Invalid" 5730 "Invalid" 5729 "Invalid" 5728 "Invalid" 5727 "Invalid" 5726 "Invalid" 5725 "Invalid" 5724 "Invalid" 5723 "Invalid" 5722 "Invalid" 5721 "Invalid" 5720 "Invalid" 5719 "Invalid" 5718 "Invalid" 5717 "Invalid" 5716 "Invalid" 5715 "Invalid" 5714 "Invalid" 5713 "Invalid" 5712 "Invalid" 5711 "Invalid" 5710 "Invalid" 5709 "Invalid" 5708 "Invalid" 5707 "Invalid" 5706 "Invalid" 5705 "Invalid" 5704 "Invalid" 5703 "Invalid" 5702 "Invalid" 5701 "Invalid" 5700 "Invalid" 5699 "Invalid" 5698 "Invalid" 5697 "Invalid" 5696 "Invalid" 5695 "Invalid" 5694 "Invalid" 5693 "Invalid" 5692 "Invalid" 5691 "Invalid" 5690 "Invalid" 5689 "Invalid" 5688 "Invalid" 5687 "Invalid" 5686 "Invalid" 5685 "Invalid" 5684 "Invalid" 5683 "Invalid" 5682 "Invalid" 5681 "Invalid" 5680 "Invalid" 5679 "Invalid" 5678 "Invalid" 5677 "Invalid" 5676 "Invalid" 5675 "Invalid" 5674 "Invalid" 5673 "Invalid" 5672 "Invalid" 5671 "Invalid" 5670 "Invalid" 5669 "Invalid" 5668 "Invalid" 5667 "Invalid" 5666 "Invalid" 5665 "Invalid" 5664 "Invalid" 5663 "Invalid" 5662 "Invalid" 5661 "Invalid" 5660 "Invalid" 5659 "Invalid" 5658 "Invalid" 5657 "Invalid" 5656 "Invalid" 5655 "Invalid" 5654 "Invalid" 5653 "Invalid" 5652 "Invalid" 5651 "Invalid" 5650 "Invalid" 5649 "Invalid" 5648 "Invalid" 5647 "Invalid" 5646 "Invalid" 5645 "Invalid" 5644 "Invalid" 5643 "Invalid" 5642 "Invalid" 5641 "Invalid" 5640 "Invalid" 5639 "Invalid" 5638 "Invalid" 5637 "Invalid" 5636 "Invalid" 5635 "Invalid" 5634 "Invalid" 5633 "Invalid" 5632 "Invalid" 5631 "Invalid" 5630 "Invalid" 5629 "Invalid" 5628 "Invalid" 5627 "Invalid" 5626 "Invalid" 5625 "Invalid" 5624 "Invalid" 5623 "Invalid" 5622 "Invalid" 5621 "Invalid" 5620 "Invalid" 5619 "Invalid" 5618 "Invalid" 5617 "Invalid" 5616 "Invalid" 5615 "Invalid" 5614 "Invalid" 5613 "Invalid" 5612 "Invalid" 5611 "Invalid" 5610 "Invalid" 5609 "Invalid" 5608 "Invalid" 5607 "Invalid" 5606 "Invalid" 5605 "Invalid" 5604 "Invalid" 5603 "Invalid" 5602 "Invalid" 5601 "Invalid" 5600 "Invalid" 5599 "Invalid" 5598 "Invalid" 5597 "Invalid" 5596 "Invalid" 5595 "Invalid" 5594 "Invalid" 5593 "Invalid" 5592 "Invalid" 5591 "Invalid" 5590 "Invalid" 5589 "Invalid" 5588 "Invalid" 5587 "Invalid" 5586 "Invalid" 5585 "Invalid" 5584 "Invalid" 5583 "Invalid" 5582 "Invalid" 5581 "Invalid" 5580 "Invalid" 5579 "Invalid" 5578 "Invalid" 5577 "Invalid" 5576 "Invalid" 5575 "Invalid" 5574 "Invalid" 5573 "Invalid" 5572 "Invalid" 5571 "Invalid" 5570 "Invalid" 5569 "Invalid" 5568 "Invalid" 5567 "Invalid" 5566 "Invalid" 5565 "Invalid" 5564 "Invalid" 5563 "Invalid" 5562 "Invalid" 5561 "Invalid" 5560 "Invalid" 5559 "Invalid" 5558 "Invalid" 5557 "Invalid" 5556 "Invalid" 5555 "Invalid" 5554 "Invalid" 5553 "Invalid" 5552 "Invalid" 5551 "Invalid" 5550 "Invalid" 5549 "Invalid" 5548 "Invalid" 5547 "Invalid" 5546 "Invalid" 5545 "Invalid" 5544 "Invalid" 5543 "Invalid" 5542 "Invalid" 5541 "Invalid" 5540 "Invalid" 5539 "Invalid" 5538 "Invalid" 5537 "Invalid" 5536 "Invalid" 5535 "Invalid" 5534 "Invalid" 5533 "Invalid" 5532 "Invalid" 5531 "Invalid" 5530 "Invalid" 5529 "Invalid" 5528 "Invalid" 5527 "Invalid" 5526 "Invalid" 5525 "Invalid" 5524 "Invalid" 5523 "Invalid" 5522 "Invalid" 5521 "Invalid" 5520 "Invalid" 5519 "Invalid" 5518 "Invalid" 5517 "Invalid" 5516 "Invalid" 5515 "Invalid" 5514 "Invalid" 5513 "Invalid" 5512 "Invalid" 5511 "Invalid" 5510 "Invalid" 5509 "Invalid" 5508 "Invalid" 5507 "Invalid" 5506 "Invalid" 5505 "Invalid" 5504 "Invalid" 5503 "Invalid" 5502 "Invalid" 5501 "Invalid" 5500 "Invalid" 5499 "Invalid" 5498 "Invalid" 5497 "Invalid" 5496 "Invalid" 5495 "Invalid" 5494 "Invalid" 5493 "Invalid" 5492 "Invalid" 5491 "Invalid" 5490 "Invalid" 5489 "Invalid" 5488 "Invalid" 5487 "Invalid" 5486 "Invalid" 5485 "Invalid" 5484 "Invalid" 5483 "Invalid" 5482 "Invalid" 5481 "Invalid" 5480 "Invalid" 5479 "Invalid" 5478 "Invalid" 5477 "Invalid" 5476 "Invalid" 5475 "Invalid" 5474 "Invalid" 5473 "Invalid" 5472 "Invalid" 5471 "Invalid" 5470 "Invalid" 5469 "Invalid" 5468 "Invalid" 5467 "Invalid" 5466 "Invalid" 5465 "Invalid" 5464 "Invalid" 5463 "Invalid" 5462 "Invalid" 5461 "Invalid" 5460 "Invalid" 5459 "Invalid" 5458 "Invalid" 5457 "Invalid" 5456 "Invalid" 5455 "Invalid" 5454 "Invalid" 5453 "Invalid" 5452 "Invalid" 5451 "Invalid" 5450 "Invalid" 5449 "Invalid" 5448 "Invalid" 5447 "Invalid" 5446 "Invalid" 5445 "Invalid" 5444 "Invalid" 5443 "Invalid" 5442 "Invalid" 5441 "Invalid" 5440 "Invalid" 5439 "Invalid" 5438 "Invalid" 5437 "Invalid" 5436 "Invalid" 5435 "Invalid" 5434 "Invalid" 5433 "Invalid" 5432 "Invalid" 5431 "Invalid" 5430 "Invalid" 5429 "Invalid" 5428 "Invalid" 5427 "Invalid" 5426 "Invalid" 5425 "Invalid" 5424 "Invalid" 5423 "Invalid" 5422 "Invalid" 5421 "Invalid" 5420 "Invalid" 5419 "Invalid" 5418 "Invalid" 5417 "Invalid" 5416 "Invalid" 5415 "Invalid" 5414 "Invalid" 5413 "Invalid" 5412 "Invalid" 5411 "Invalid" 5410 "Invalid" 5409 "Invalid" 5408 "Invalid" 5407 "Invalid" 5406 "Invalid" 5405 "Invalid" 5404 "Invalid" 5403 "Invalid" 5402 "Invalid" 5401 "Invalid" 5400 "Invalid" 5399 "Invalid" 5398 "Invalid" 5397 "Invalid" 5396 "Invalid" 5395 "Invalid" 5394 "Invalid" 5393 "Invalid" 5392 "Invalid" 5391 "Invalid" 5390 "Invalid" 5389 "Invalid" 5388 "Invalid" 5387 "Invalid" 5386 "Invalid" 5385 "Invalid" 5384 "Invalid" 5383 "Invalid" 5382 "Invalid" 5381 "Invalid" 5380 "Invalid" 5379 "Invalid" 5378 "Invalid" 5377 "Invalid" 5376 "Invalid" 5375 "Invalid" 5374 "Invalid" 5373 "Invalid" 5372 "Invalid" 5371 "Invalid" 5370 "Invalid" 5369 "Invalid" 5368 "Invalid" 5367 "Invalid" 5366 "Invalid" 5365 "Invalid" 5364 "Invalid" 5363 "Invalid" 5362 "Invalid" 5361 "Invalid" 5360 "Invalid" 5359 "Invalid" 5358 "Invalid" 5357 "Invalid" 5356 "Invalid" 5355 "Invalid" 5354 "Invalid" 5353 "Invalid" 5352 "Invalid" 5351 "Invalid" 5350 "Invalid" 5349 "Invalid" 5348 "Invalid" 5347 "Invalid" 5346 "Invalid" 5345 "Invalid" 5344 "Invalid" 5343 "Invalid" 5342 "Invalid" 5341 "Invalid" 5340 "Invalid" 5339 "Invalid" 5338 "Invalid" 5337 "Invalid" 5336 "Invalid" 5335 "Invalid" 5334 "Invalid" 5333 "Invalid" 5332 "Invalid" 5331 "Invalid" 5330 "Invalid" 5329 "Invalid" 5328 "Invalid" 5327 "Invalid" 5326 "Invalid" 5325 "Invalid" 5324 "Invalid" 5323 "Invalid" 5322 "Invalid" 5321 "Invalid" 5320 "Invalid" 5319 "Invalid" 5318 "Invalid" 5317 "Invalid" 5316 "Invalid" 5315 "Invalid" 5314 "Invalid" 5313 "Invalid" 5312 "Invalid" 5311 "Invalid" 5310 "Invalid" 5309 "Invalid" 5308 "Invalid" 5307 "Invalid" 5306 "Invalid" 5305 "Invalid" 5304 "Invalid" 5303 "Invalid" 5302 "Invalid" 5301 "Invalid" 5300 "Invalid" 5299 "Invalid" 5298 "Invalid" 5297 "Invalid" 5296 "Invalid" 5295 "Invalid" 5294 "Invalid" 5293 "Invalid" 5292 "Invalid" 5291 "Invalid" 5290 "Invalid" 5289 "Invalid" 5288 "Invalid" 5287 "Invalid" 5286 "Invalid" 5285 "Invalid" 5284 "Invalid" 5283 "Invalid" 5282 "Invalid" 5281 "Invalid" 5280 "Invalid" 5279 "Invalid" 5278 "Invalid" 5277 "Invalid" 5276 "Invalid" 5275 "Invalid" 5274 "Invalid" 5273 "Invalid" 5272 "Invalid" 5271 "Invalid" 5270 "Invalid" 5269 "Invalid" 5268 "Invalid" 5267 "Invalid" 5266 "Invalid" 5265 "Invalid" 5264 "Invalid" 5263 "Invalid" 5262 "Invalid" 5261 "Invalid" 5260 "Invalid" 5259 "Invalid" 5258 "Invalid" 5257 "Invalid" 5256 "Invalid" 5255 "Invalid" 5254 "Invalid" 5253 "Invalid" 5252 "Invalid" 5251 "Invalid" 5250 "Invalid" 5249 "Invalid" 5248 "Invalid" 5247 "Invalid" 5246 "Invalid" 5245 "Invalid" 5244 "Invalid" 5243 "Invalid" 5242 "Invalid" 5241 "Invalid" 5240 "Invalid" 5239 "Invalid" 5238 "Invalid" 5237 "Invalid" 5236 "Invalid" 5235 "Invalid" 5234 "Invalid" 5233 "Invalid" 5232 "Invalid" 5231 "Invalid" 5230 "Invalid" 5229 "Invalid" 5228 "Invalid" 5227 "Invalid" 5226 "Invalid" 5225 "Invalid" 5224 "Invalid" 5223 "Invalid" 5222 "Invalid" 5221 "Invalid" 5220 "Invalid" 5219 "Invalid" 5218 "Invalid" 5217 "Invalid" 5216 "Invalid" 5215 "Invalid" 5214 "Invalid" 5213 "Invalid" 5212 "Invalid" 5211 "Invalid" 5210 "Invalid" 5209 "Invalid" 5208 "Invalid" 5207 "Invalid" 5206 "Invalid" 5205 "Invalid" 5204 "Invalid" 5203 "Invalid" 5202 "Invalid" 5201 "Invalid" 5200 "Invalid" 5199 "Invalid" 5198 "Invalid" 5197 "Invalid" 5196 "Invalid" 5195 "Invalid" 5194 "Invalid" 5193 "Invalid" 5192 "Invalid" 5191 "Invalid" 5190 "Invalid" 5189 "Invalid" 5188 "Invalid" 5187 "Invalid" 5186 "Invalid" 5185 "Invalid" 5184 "Invalid" 5183 "Invalid" 5182 "Invalid" 5181 "Invalid" 5180 "Invalid" 5179 "Invalid" 5178 "Invalid" 5177 "Invalid" 5176 "Invalid" 5175 "Invalid" 5174 "Invalid" 5173 "Invalid" 5172 "Invalid" 5171 "Invalid" 5170 "Invalid" 5169 "Invalid" 5168 "Invalid" 5167 "Invalid" 5166 "Invalid" 5165 "Invalid" 5164 "Invalid" 5163 "Invalid" 5162 "Invalid" 5161 "Invalid" 5160 "Invalid" 5159 "Invalid" 5158 "Invalid" 5157 "Invalid" 5156 "Invalid" 5155 "Invalid" 5154 "Invalid" 5153 "Invalid" 5152 "Invalid" 5151 "Invalid" 5150 "Invalid" 5149 "Invalid" 5148 "Invalid" 5147 "Invalid" 5146 "Invalid" 5145 "Invalid" 5144 "Invalid" 5143 "Invalid" 5142 "Invalid" 5141 "Invalid" 5140 "Invalid" 5139 "Invalid" 5138 "Invalid" 5137 "Invalid" 5136 "Invalid" 5135 "Invalid" 5134 "Invalid" 5133 "Invalid" 5132 "Invalid" 5131 "Invalid" 5130 "Invalid" 5129 "Invalid" 5128 "Invalid" 5127 "Invalid" 5126 "Invalid" 5125 "Invalid" 5124 "Invalid" 5123 "Invalid" 5122 "Invalid" 5121 "Invalid" 5120 "Invalid" 5119 "Invalid" 5118 "Invalid" 5117 "Invalid" 5116 "Invalid" 5115 "Invalid" 5114 "Invalid" 5113 "Invalid" 5112 "Invalid" 5111 "Invalid" 5110 "Invalid" 5109 "Invalid" 5108 "Invalid" 5107 "Invalid" 5106 "Invalid" 5105 "Invalid" 5104 "Invalid" 5103 "Invalid" 5102 "Invalid" 5101 "Invalid" 5100 "Invalid" 5099 "Invalid" 5098 "Invalid" 5097 "Invalid" 5096 "Invalid" 5095 "Invalid" 5094 "Invalid" 5093 "Invalid" 5092 "Invalid" 5091 "Invalid" 5090 "Invalid" 5089 "Invalid" 5088 "Invalid" 5087 "Invalid" 5086 "Invalid" 5085 "Invalid" 5084 "Invalid" 5083 "Invalid" 5082 "Invalid" 5081 "Invalid" 5080 "Invalid" 5079 "Invalid" 5078 "Invalid" 5077 "Invalid" 5076 "Invalid" 5075 "Invalid" 5074 "Invalid" 5073 "Invalid" 5072 "Invalid" 5071 "Invalid" 5070 "Invalid" 5069 "Invalid" 5068 "Invalid" 5067 "Invalid" 5066 "Invalid" 5065 "Invalid" 5064 "Invalid" 5063 "Invalid" 5062 "Invalid" 5061 "Invalid" 5060 "Invalid" 5059 "Invalid" 5058 "Invalid" 5057 "Invalid" 5056 "Invalid" 5055 "Invalid" 5054 "Invalid" 5053 "Invalid" 5052 "Invalid" 5051 "Invalid" 5050 "Invalid" 5049 "Invalid" 5048 "Invalid" 5047 "Invalid" 5046 "Invalid" 5045 "Invalid" 5044 "Invalid" 5043 "Invalid" 5042 "Invalid" 5041 "Invalid" 5040 "Invalid" 5039 "Invalid" 5038 "Invalid" 5037 "Invalid" 5036 "Invalid" 5035 "Invalid" 5034 "Invalid" 5033 "Invalid" 5032 "Invalid" 5031 "Invalid" 5030 "Invalid" 5029 "Invalid" 5028 "Invalid" 5027 "Invalid" 5026 "Invalid" 5025 "Invalid" 5024 "Invalid" 5023 "Invalid" 5022 "Invalid" 5021 "Invalid" 5020 "Invalid" 5019 "Invalid" 5018 "Invalid" 5017 "Invalid" 5016 "Invalid" 5015 "Invalid" 5014 "Invalid" 5013 "Invalid" 5012 "Invalid" 5011 "Invalid" 5010 "Invalid" 5009 "Invalid" 5008 "Invalid" 5007 "Invalid" 5006 "Invalid" 5005 "Invalid" 5004 "Invalid" 5003 "Invalid" 5002 "Invalid" 5001 "Invalid" ;
VAL_ 530 BCU_MaxCellVltNr 127 "Invalid" 126 "Invalid" 125 "Invalid" 124 "Invalid" 123 "Invalid" 122 "Invalid" 121 "Invalid" ;
VAL_ 530 BCU_MinCellVltNr 127 "Invalid" 126 "Invalid" 125 "Invalid" 124 "Invalid" 123 "Invalid" 122 "Invalid" 121 "Invalid" ;
VAL_ 530 BCU_DispSOC 127 "Invalid" 126 "Invalid" 125 "Invalid" 124 "Invalid" 123 "Invalid" 122 "Invalid" 121 "Invalid" 120 "Invalid" 119 "Invalid" 118 "Invalid" 117 "Invalid" 116 "Invalid" 115 "Invalid" 114 "Invalid" 113 "Invalid" 112 "Invalid" 111 "Invalid" 110 "Invalid" 109 "Invalid" 108 "Invalid" 107 "Invalid" 106 "Invalid" 105 "Invalid" 104 "Invalid" 103 "Invalid" 102 "Invalid" 101 "Invalid" ;
VAL_ 531 BCU_MaxDschrgPwr_10s 511 "Invalid" ;
VAL_ 531 BCU_MaxDschrgPwr_30s 511 "Invalid" ;
VAL_ 531 BCU_MinDschrgVlt 511 "Invalid" 510 "Invalid" 509 "Invalid" 508 "Invalid" 507 "Invalid" 506 "Invalid" 505 "Invalid" 504 "Invalid" 503 "Invalid" 502 "Invalid" 501 "Invalid" ;
VAL_ 531 BCU_MaxDschrgCur 511 "Invalid" 510 "Invalid" 509 "Invalid" 508 "Invalid" 507 "Invalid" 506 "Invalid" 505 "Invalid" 504 "Invalid" 503 "Invalid" 502 "Invalid" 501 "Invalid" ;
VAL_ 532 BCU_MaxChrgPwr_10s 511 "Invalid" ;
VAL_ 532 BCU_MaxChrgPwr_30s 511 "Invalid" ;
VAL_ 532 BCU_MaxRegerCur 511 "Invalid" 510 "Invalid" 509 "Invalid" 508 "Invalid" 507 "Invalid" 506 "Invalid" 505 "Invalid" 504 "Invalid" 503 "Invalid" 502 "Invalid" 501 "Invalid" ;
VAL_ 532 BCU_MaxChrgPwr_DCChrgPile 4095 "Invalid" 4094 "Invalid" 4093 "Invalid" 4092 "Invalid" 4091 "Invalid" 4090 "Invalid" 4089 "Invalid" 4088 "Invalid" 4087 "Invalid" 4086 "Invalid" 4085 "Invalid" 4084 "Invalid" 4083 "Invalid" 4082 "Invalid" 4081 "Invalid" 4080 "Invalid" 4079 "Invalid" 4078 "Invalid" 4077 "Invalid" 4076 "Invalid" 4075 "Invalid" 4074 "Invalid" 4073 "Invalid" 4072 "Invalid" 4071 "Invalid" 4070 "Invalid" 4069 "Invalid" 4068 "Invalid" 4067 "Invalid" 4066 "Invalid" 4065 "Invalid" 4064 "Invalid" 4063 "Invalid" 4062 "Invalid" 4061 "Invalid" 4060 "Invalid" 4059 "Invalid" 4058 "Invalid" 4057 "Invalid" 4056 "Invalid" 4055 "Invalid" 4054 "Invalid" 4053 "Invalid" 4052 "Invalid" 4051 "Invalid" 4050 "Invalid" 4049 "Invalid" 4048 "Invalid" 4047 "Invalid" 4046 "Invalid" 4045 "Invalid" 4044 "Invalid" 4043 "Invalid" 4042 "Invalid" 4041 "Invalid" 4040 "Invalid" 4039 "Invalid" 4038 "Invalid" 4037 "Invalid" 4036 "Invalid" 4035 "Invalid" 4034 "Invalid" 4033 "Invalid" 4032 "Invalid" 4031 "Invalid" 4030 "Invalid" 4029 "Invalid" 4028 "Invalid" 4027 "Invalid" 4026 "Invalid" 4025 "Invalid" 4024 "Invalid" 4023 "Invalid" 4022 "Invalid" 4021 "Invalid" 4020 "Invalid" 4019 "Invalid" 4018 "Invalid" 4017 "Invalid" 4016 "Invalid" 4015 "Invalid" 4014 "Invalid" 4013 "Invalid" 4012 "Invalid" 4011 "Invalid" 4010 "Invalid" 4009 "Invalid" 4008 "Invalid" 4007 "Invalid" 4006 "Invalid" 4005 "Invalid" 4004 "Invalid" 4003 "Invalid" 4002 "Invalid" 4001 "Invalid" 4000 "Invalid" 3999 "Invalid" 3998 "Invalid" 3997 "Invalid" 3996 "Invalid" 3995 "Invalid" 3994 "Invalid" 3993 "Invalid" 3992 "Invalid" 3991 "Invalid" 3990 "Invalid" 3989 "Invalid" 3988 "Invalid" 3987 "Invalid" 3986 "Invalid" 3985 "Invalid" 3984 "Invalid" 3983 "Invalid" 3982 "Invalid" 3981 "Invalid" 3980 "Invalid" 3979 "Invalid" 3978 "Invalid" 3977 "Invalid" 3976 "Invalid" 3975 "Invalid" 3974 "Invalid" 3973 "Invalid" 3972 "Invalid" 3971 "Invalid" 3970 "Invalid" 3969 "Invalid" 3968 "Invalid" 3967 "Invalid" 3966 "Invalid" 3965 "Invalid" 3964 "Invalid" 3963 "Invalid" 3962 "Invalid" 3961 "Invalid" 3960 "Invalid" 3959 "Invalid" 3958 "Invalid" 3957 "Invalid" 3956 "Invalid" 3955 "Invalid" 3954 "Invalid" 3953 "Invalid" 3952 "Invalid" 3951 "Invalid" 3950 "Invalid" 3949 "Invalid" 3948 "Invalid" 3947 "Invalid" 3946 "Invalid" 3945 "Invalid" 3944 "Invalid" 3943 "Invalid" 3942 "Invalid" 3941 "Invalid" 3940 "Invalid" 3939 "Invalid" 3938 "Invalid" 3937 "Invalid" 3936 "Invalid" 3935 "Invalid" 3934 "Invalid" 3933 "Invalid" 3932 "Invalid" 3931 "Invalid" 3930 "Invalid" 3929 "Invalid" 3928 "Invalid" 3927 "Invalid" 3926 "Invalid" 3925 "Invalid" 3924 "Invalid" 3923 "Invalid" 3922 "Invalid" 3921 "Invalid" 3920 "Invalid" 3919 "Invalid" 3918 "Invalid" 3917 "Invalid" 3916 "Invalid" 3915 "Invalid" 3914 "Invalid" 3913 "Invalid" 3912 "Invalid" 3911 "Invalid" 3910 "Invalid" 3909 "Invalid" 3908 "Invalid" 3907 "Invalid" 3906 "Invalid" 3905 "Invalid" 3904 "Invalid" 3903 "Invalid" 3902 "Invalid" 3901 "Invalid" 3900 "Invalid" 3899 "Invalid" 3898 "Invalid" 3897 "Invalid" 3896 "Invalid" 3895 "Invalid" 3894 "Invalid" 3893 "Invalid" 3892 "Invalid" 3891 "Invalid" 3890 "Invalid" 3889 "Invalid" 3888 "Invalid" 3887 "Invalid" 3886 "Invalid" 3885 "Invalid" 3884 "Invalid" 3883 "Invalid" 3882 "Invalid" 3881 "Invalid" 3880 "Invalid" 3879 "Invalid" 3878 "Invalid" 3877 "Invalid" 3876 "Invalid" 3875 "Invalid" 3874 "Invalid" 3873 "Invalid" 3872 "Invalid" 3871 "Invalid" 3870 "Invalid" 3869 "Invalid" 3868 "Invalid" 3867 "Invalid" 3866 "Invalid" 3865 "Invalid" 3864 "Invalid" 3863 "Invalid" 3862 "Invalid" 3861 "Invalid" 3860 "Invalid" 3859 "Invalid" 3858 "Invalid" 3857 "Invalid" 3856 "Invalid" 3855 "Invalid" 3854 "Invalid" 3853 "Invalid" 3852 "Invalid" 3851 "Invalid" 3850 "Invalid" 3849 "Invalid" 3848 "Invalid" 3847 "Invalid" 3846 "Invalid" 3845 "Invalid" 3844 "Invalid" 3843 "Invalid" 3842 "Invalid" 3841 "Invalid" 3840 "Invalid" 3839 "Invalid" 3838 "Invalid" 3837 "Invalid" 3836 "Invalid" 3835 "Invalid" 3834 "Invalid" 3833 "Invalid" 3832 "Invalid" 3831 "Invalid" 3830 "Invalid" 3829 "Invalid" 3828 "Invalid" 3827 "Invalid" 3826 "Invalid" 3825 "Invalid" 3824 "Invalid" 3823 "Invalid" 3822 "Invalid" 3821 "Invalid" 3820 "Invalid" 3819 "Invalid" 3818 "Invalid" 3817 "Invalid" 3816 "Invalid" 3815 "Invalid" 3814 "Invalid" 3813 "Invalid" 3812 "Invalid" 3811 "Invalid" 3810 "Invalid" 3809 "Invalid" 3808 "Invalid" 3807 "Invalid" 3806 "Invalid" 3805 "Invalid" 3804 "Invalid" 3803 "Invalid" 3802 "Invalid" 3801 "Invalid" 3800 "Invalid" 3799 "Invalid" 3798 "Invalid" 3797 "Invalid" 3796 "Invalid" 3795 "Invalid" 3794 "Invalid" 3793 "Invalid" 3792 "Invalid" 3791 "Invalid" 3790 "Invalid" 3789 "Invalid" 3788 "Invalid" 3787 "Invalid" 3786 "Invalid" 3785 "Invalid" 3784 "Invalid" 3783 "Invalid" 3782 "Invalid" 3781 "Invalid" 3780 "Invalid" 3779 "Invalid" 3778 "Invalid" 3777 "Invalid" 3776 "Invalid" 3775 "Invalid" 3774 "Invalid" 3773 "Invalid" 3772 "Invalid" 3771 "Invalid" 3770 "Invalid" 3769 "Invalid" 3768 "Invalid" 3767 "Invalid" 3766 "Invalid" 3765 "Invalid" 3764 "Invalid" 3763 "Invalid" 3762 "Invalid" 3761 "Invalid" 3760 "Invalid" 3759 "Invalid" 3758 "Invalid" 3757 "Invalid" 3756 "Invalid" 3755 "Invalid" 3754 "Invalid" 3753 "Invalid" 3752 "Invalid" 3751 "Invalid" 3750 "Invalid" 3749 "Invalid" 3748 "Invalid" 3747 "Invalid" 3746 "Invalid" 3745 "Invalid" 3744 "Invalid" 3743 "Invalid" 3742 "Invalid" 3741 "Invalid" 3740 "Invalid" 3739 "Invalid" 3738 "Invalid" 3737 "Invalid" 3736 "Invalid" 3735 "Invalid" 3734 "Invalid" 3733 "Invalid" 3732 "Invalid" 3731 "Invalid" 3730 "Invalid" 3729 "Invalid" 3728 "Invalid" 3727 "Invalid" 3726 "Invalid" 3725 "Invalid" 3724 "Invalid" 3723 "Invalid" 3722 "Invalid" 3721 "Invalid" 3720 "Invalid" 3719 "Invalid" 3718 "Invalid" 3717 "Invalid" 3716 "Invalid" 3715 "Invalid" 3714 "Invalid" 3713 "Invalid" 3712 "Invalid" 3711 "Invalid" 3710 "Invalid" 3709 "Invalid" 3708 "Invalid" 3707 "Invalid" 3706 "Invalid" 3705 "Invalid" 3704 "Invalid" 3703 "Invalid" 3702 "Invalid" 3701 "Invalid" 3700 "Invalid" 3699 "Invalid" 3698 "Invalid" 3697 "Invalid" 3696 "Invalid" 3695 "Invalid" 3694 "Invalid" 3693 "Invalid" 3692 "Invalid" 3691 "Invalid" 3690 "Invalid" 3689 "Invalid" 3688 "Invalid" 3687 "Invalid" 3686 "Invalid" 3685 "Invalid" 3684 "Invalid" 3683 "Invalid" 3682 "Invalid" 3681 "Invalid" 3680 "Invalid" 3679 "Invalid" 3678 "Invalid" 3677 "Invalid" 3676 "Invalid" 3675 "Invalid" 3674 "Invalid" 3673 "Invalid" 3672 "Invalid" 3671 "Invalid" 3670 "Invalid" 3669 "Invalid" 3668 "Invalid" 3667 "Invalid" 3666 "Invalid" 3665 "Invalid" 3664 "Invalid" 3663 "Invalid" 3662 "Invalid" 3661 "Invalid" 3660 "Invalid" 3659 "Invalid" 3658 "Invalid" 3657 "Invalid" 3656 "Invalid" 3655 "Invalid" 3654 "Invalid" 3653 "Invalid" 3652 "Invalid" 3651 "Invalid" 3650 "Invalid" 3649 "Invalid" 3648 "Invalid" 3647 "Invalid" 3646 "Invalid" 3645 "Invalid" 3644 "Invalid" 3643 "Invalid" 3642 "Invalid" 3641 "Invalid" 3640 "Invalid" 3639 "Invalid" 3638 "Invalid" 3637 "Invalid" 3636 "Invalid" 3635 "Invalid" 3634 "Invalid" 3633 "Invalid" 3632 "Invalid" 3631 "Invalid" 3630 "Invalid" 3629 "Invalid" 3628 "Invalid" 3627 "Invalid" 3626 "Invalid" 3625 "Invalid" 3624 "Invalid" 3623 "Invalid" 3622 "Invalid" 3621 "Invalid" 3620 "Invalid" 3619 "Invalid" 3618 "Invalid" 3617 "Invalid" 3616 "Invalid" 3615 "Invalid" 3614 "Invalid" 3613 "Invalid" 3612 "Invalid" 3611 "Invalid" 3610 "Invalid" 3609 "Invalid" 3608 "Invalid" 3607 "Invalid" 3606 "Invalid" 3605 "Invalid" 3604 "Invalid" 3603 "Invalid" 3602 "Invalid" 3601 "Invalid" 3600 "Invalid" 3599 "Invalid" 3598 "Invalid" 3597 "Invalid" 3596 "Invalid" 3595 "Invalid" 3594 "Invalid" 3593 "Invalid" 3592 "Invalid" 3591 "Invalid" 3590 "Invalid" 3589 "Invalid" 3588 "Invalid" 3587 "Invalid" 3586 "Invalid" 3585 "Invalid" 3584 "Invalid" 3583 "Invalid" 3582 "Invalid" 3581 "Invalid" 3580 "Invalid" 3579 "Invalid" 3578 "Invalid" 3577 "Invalid" 3576 "Invalid" 3575 "Invalid" 3574 "Invalid" 3573 "Invalid" 3572 "Invalid" 3571 "Invalid" 3570 "Invalid" 3569 "Invalid" 3568 "Invalid" 3567 "Invalid" 3566 "Invalid" 3565 "Invalid" 3564 "Invalid" 3563 "Invalid" 3562 "Invalid" 3561 "Invalid" 3560 "Invalid" 3559 "Invalid" 3558 "Invalid" 3557 "Invalid" 3556 "Invalid" 3555 "Invalid" 3554 "Invalid" 3553 "Invalid" 3552 "Invalid" 3551 "Invalid" 3550 "Invalid" 3549 "Invalid" 3548 "Invalid" 3547 "Invalid" 3546 "Invalid" 3545 "Invalid" 3544 "Invalid" 3543 "Invalid" 3542 "Invalid" 3541 "Invalid" 3540 "Invalid" 3539 "Invalid" 3538 "Invalid" 3537 "Invalid" 3536 "Invalid" 3535 "Invalid" 3534 "Invalid" 3533 "Invalid" 3532 "Invalid" 3531 "Invalid" 3530 "Invalid" 3529 "Invalid" 3528 "Invalid" 3527 "Invalid" 3526 "Invalid" 3525 "Invalid" 3524 "Invalid" 3523 "Invalid" 3522 "Invalid" 3521 "Invalid" 3520 "Invalid" 3519 "Invalid" 3518 "Invalid" 3517 "Invalid" 3516 "Invalid" 3515 "Invalid" 3514 "Invalid" 3513 "Invalid" 3512 "Invalid" 3511 "Invalid" 3510 "Invalid" 3509 "Invalid" 3508 "Invalid" 3507 "Invalid" 3506 "Invalid" 3505 "Invalid" 3504 "Invalid" 3503 "Invalid" 3502 "Invalid" 3501 "Invalid" 3500 "Invalid" 3499 "Invalid" 3498 "Invalid" 3497 "Invalid" 3496 "Invalid" 3495 "Invalid" 3494 "Invalid" 3493 "Invalid" 3492 "Invalid" 3491 "Invalid" 3490 "Invalid" 3489 "Invalid" 3488 "Invalid" 3487 "Invalid" 3486 "Invalid" 3485 "Invalid" 3484 "Invalid" 3483 "Invalid" 3482 "Invalid" 3481 "Invalid" 3480 "Invalid" 3479 "Invalid" 3478 "Invalid" 3477 "Invalid" 3476 "Invalid" 3475 "Invalid" 3474 "Invalid" 3473 "Invalid" 3472 "Invalid" 3471 "Invalid" 3470 "Invalid" 3469 "Invalid" 3468 "Invalid" 3467 "Invalid" 3466 "Invalid" 3465 "Invalid" 3464 "Invalid" 3463 "Invalid" 3462 "Invalid" 3461 "Invalid" 3460 "Invalid" 3459 "Invalid" 3458 "Invalid" 3457 "Invalid" 3456 "Invalid" 3455 "Invalid" 3454 "Invalid" 3453 "Invalid" 3452 "Invalid" 3451 "Invalid" 3450 "Invalid" 3449 "Invalid" 3448 "Invalid" 3447 "Invalid" 3446 "Invalid" 3445 "Invalid" 3444 "Invalid" 3443 "Invalid" 3442 "Invalid" 3441 "Invalid" 3440 "Invalid" 3439 "Invalid" 3438 "Invalid" 3437 "Invalid" 3436 "Invalid" 3435 "Invalid" 3434 "Invalid" 3433 "Invalid" 3432 "Invalid" 3431 "Invalid" 3430 "Invalid" 3429 "Invalid" 3428 "Invalid" 3427 "Invalid" 3426 "Invalid" 3425 "Invalid" 3424 "Invalid" 3423 "Invalid" 3422 "Invalid" 3421 "Invalid" 3420 "Invalid" 3419 "Invalid" 3418 "Invalid" 3417 "Invalid" 3416 "Invalid" 3415 "Invalid" 3414 "Invalid" 3413 "Invalid" 3412 "Invalid" 3411 "Invalid" 3410 "Invalid" 3409 "Invalid" 3408 "Invalid" 3407 "Invalid" 3406 "Invalid" 3405 "Invalid" 3404 "Invalid" 3403 "Invalid" 3402 "Invalid" 3401 "Invalid" 3400 "Invalid" 3399 "Invalid" 3398 "Invalid" 3397 "Invalid" 3396 "Invalid" 3395 "Invalid" 3394 "Invalid" 3393 "Invalid" 3392 "Invalid" 3391 "Invalid" 3390 "Invalid" 3389 "Invalid" 3388 "Invalid" 3387 "Invalid" 3386 "Invalid" 3385 "Invalid" 3384 "Invalid" 3383 "Invalid" 3382 "Invalid" 3381 "Invalid" 3380 "Invalid" 3379 "Invalid" 3378 "Invalid" 3377 "Invalid" 3376 "Invalid" 3375 "Invalid" 3374 "Invalid" 3373 "Invalid" 3372 "Invalid" 3371 "Invalid" 3370 "Invalid" 3369 "Invalid" 3368 "Invalid" 3367 "Invalid" 3366 "Invalid" 3365 "Invalid" 3364 "Invalid" 3363 "Invalid" 3362 "Invalid" 3361 "Invalid" 3360 "Invalid" 3359 "Invalid" 3358 "Invalid" 3357 "Invalid" 3356 "Invalid" 3355 "Invalid" 3354 "Invalid" 3353 "Invalid" 3352 "Invalid" 3351 "Invalid" 3350 "Invalid" 3349 "Invalid" 3348 "Invalid" 3347 "Invalid" 3346 "Invalid" 3345 "Invalid" 3344 "Invalid" 3343 "Invalid" 3342 "Invalid" 3341 "Invalid" 3340 "Invalid" 3339 "Invalid" 3338 "Invalid" 3337 "Invalid" 3336 "Invalid" 3335 "Invalid" 3334 "Invalid" 3333 "Invalid" 3332 "Invalid" 3331 "Invalid" 3330 "Invalid" 3329 "Invalid" 3328 "Invalid" 3327 "Invalid" 3326 "Invalid" 3325 "Invalid" 3324 "Invalid" 3323 "Invalid" 3322 "Invalid" 3321 "Invalid" 3320 "Invalid" 3319 "Invalid" 3318 "Invalid" 3317 "Invalid" 3316 "Invalid" 3315 "Invalid" 3314 "Invalid" 3313 "Invalid" 3312 "Invalid" 3311 "Invalid" 3310 "Invalid" 3309 "Invalid" 3308 "Invalid" 3307 "Invalid" 3306 "Invalid" 3305 "Invalid" 3304 "Invalid" 3303 "Invalid" 3302 "Invalid" 3301 "Invalid" 3300 "Invalid" 3299 "Invalid" 3298 "Invalid" 3297 "Invalid" 3296 "Invalid" 3295 "Invalid" 3294 "Invalid" 3293 "Invalid" 3292 "Invalid" 3291 "Invalid" 3290 "Invalid" 3289 "Invalid" 3288 "Invalid" 3287 "Invalid" 3286 "Invalid" 3285 "Invalid" 3284 "Invalid" 3283 "Invalid" 3282 "Invalid" 3281 "Invalid" 3280 "Invalid" 3279 "Invalid" 3278 "Invalid" 3277 "Invalid" 3276 "Invalid" 3275 "Invalid" 3274 "Invalid" 3273 "Invalid" 3272 "Invalid" 3271 "Invalid" 3270 "Invalid" 3269 "Invalid" 3268 "Invalid" 3267 "Invalid" 3266 "Invalid" 3265 "Invalid" 3264 "Invalid" 3263 "Invalid" 3262 "Invalid" 3261 "Invalid" 3260 "Invalid" 3259 "Invalid" 3258 "Invalid" 3257 "Invalid" 3256 "Invalid" 3255 "Invalid" 3254 "Invalid" 3253 "Invalid" 3252 "Invalid" 3251 "Invalid" 3250 "Invalid" 3249 "Invalid" 3248 "Invalid" 3247 "Invalid" 3246 "Invalid" 3245 "Invalid" 3244 "Invalid" 3243 "Invalid" 3242 "Invalid" 3241 "Invalid" 3240 "Invalid" 3239 "Invalid" 3238 "Invalid" 3237 "Invalid" 3236 "Invalid" 3235 "Invalid" 3234 "Invalid" 3233 "Invalid" 3232 "Invalid" 3231 "Invalid" 3230 "Invalid" 3229 "Invalid" 3228 "Invalid" 3227 "Invalid" 3226 "Invalid" 3225 "Invalid" 3224 "Invalid" 3223 "Invalid" 3222 "Invalid" 3221 "Invalid" 3220 "Invalid" 3219 "Invalid" 3218 "Invalid" 3217 "Invalid" 3216 "Invalid" 3215 "Invalid" 3214 "Invalid" 3213 "Invalid" 3212 "Invalid" 3211 "Invalid" 3210 "Invalid" 3209 "Invalid" 3208 "Invalid" 3207 "Invalid" 3206 "Invalid" 3205 "Invalid" 3204 "Invalid" 3203 "Invalid" 3202 "Invalid" 3201 "Invalid" 3200 "Invalid" 3199 "Invalid" 3198 "Invalid" 3197 "Invalid" 3196 "Invalid" 3195 "Invalid" 3194 "Invalid" 3193 "Invalid" 3192 "Invalid" 3191 "Invalid" 3190 "Invalid" 3189 "Invalid" 3188 "Invalid" 3187 "Invalid" 3186 "Invalid" 3185 "Invalid" 3184 "Invalid" 3183 "Invalid" 3182 "Invalid" 3181 "Invalid" 3180 "Invalid" 3179 "Invalid" 3178 "Invalid" 3177 "Invalid" 3176 "Invalid" 3175 "Invalid" 3174 "Invalid" 3173 "Invalid" 3172 "Invalid" 3171 "Invalid" 3170 "Invalid" 3169 "Invalid" 3168 "Invalid" 3167 "Invalid" 3166 "Invalid" 3165 "Invalid" 3164 "Invalid" 3163 "Invalid" 3162 "Invalid" 3161 "Invalid" 3160 "Invalid" 3159 "Invalid" 3158 "Invalid" 3157 "Invalid" 3156 "Invalid" 3155 "Invalid" 3154 "Invalid" 3153 "Invalid" 3152 "Invalid" 3151 "Invalid" 3150 "Invalid" 3149 "Invalid" 3148 "Invalid" 3147 "Invalid" 3146 "Invalid" 3145 "Invalid" 3144 "Invalid" 3143 "Invalid" 3142 "Invalid" 3141 "Invalid" 3140 "Invalid" 3139 "Invalid" 3138 "Invalid" 3137 "Invalid" 3136 "Invalid" 3135 "Invalid" 3134 "Invalid" 3133 "Invalid" 3132 "Invalid" 3131 "Invalid" 3130 "Invalid" 3129 "Invalid" 3128 "Invalid" 3127 "Invalid" 3126 "Invalid" 3125 "Invalid" 3124 "Invalid" 3123 "Invalid" 3122 "Invalid" 3121 "Invalid" 3120 "Invalid" 3119 "Invalid" 3118 "Invalid" 3117 "Invalid" 3116 "Invalid" 3115 "Invalid" 3114 "Invalid" 3113 "Invalid" 3112 "Invalid" 3111 "Invalid" 3110 "Invalid" 3109 "Invalid" 3108 "Invalid" 3107 "Invalid" 3106 "Invalid" 3105 "Invalid" 3104 "Invalid" 3103 "Invalid" 3102 "Invalid" 3101 "Invalid" 3100 "Invalid" 3099 "Invalid" 3098 "Invalid" 3097 "Invalid" 3096 "Invalid" 3095 "Invalid" 3094 "Invalid" 3093 "Invalid" 3092 "Invalid" 3091 "Invalid" 3090 "Invalid" 3089 "Invalid" 3088 "Invalid" 3087 "Invalid" 3086 "Invalid" 3085 "Invalid" 3084 "Invalid" 3083 "Invalid" 3082 "Invalid" 3081 "Invalid" 3080 "Invalid" 3079 "Invalid" 3078 "Invalid" 3077 "Invalid" 3076 "Invalid" 3075 "Invalid" 3074 "Invalid" 3073 "Invalid" 3072 "Invalid" 3071 "Invalid" 3070 "Invalid" 3069 "Invalid" 3068 "Invalid" 3067 "Invalid" 3066 "Invalid" 3065 "Invalid" 3064 "Invalid" 3063 "Invalid" 3062 "Invalid" 3061 "Invalid" 3060 "Invalid" 3059 "Invalid" 3058 "Invalid" 3057 "Invalid" 3056 "Invalid" 3055 "Invalid" 3054 "Invalid" 3053 "Invalid" 3052 "Invalid" 3051 "Invalid" 3050 "Invalid" 3049 "Invalid" 3048 "Invalid" 3047 "Invalid" 3046 "Invalid" 3045 "Invalid" 3044 "Invalid" 3043 "Invalid" 3042 "Invalid" 3041 "Invalid" 3040 "Invalid" 3039 "Invalid" 3038 "Invalid" 3037 "Invalid" 3036 "Invalid" 3035 "Invalid" 3034 "Invalid" 3033 "Invalid" 3032 "Invalid" 3031 "Invalid" 3030 "Invalid" 3029 "Invalid" 3028 "Invalid" 3027 "Invalid" 3026 "Invalid" 3025 "Invalid" 3024 "Invalid" 3023 "Invalid" 3022 "Invalid" 3021 "Invalid" 3020 "Invalid" 3019 "Invalid" 3018 "Invalid" 3017 "Invalid" 3016 "Invalid" 3015 "Invalid" 3014 "Invalid" 3013 "Invalid" 3012 "Invalid" 3011 "Invalid" 3010 "Invalid" 3009 "Invalid" 3008 "Invalid" 3007 "Invalid" 3006 "Invalid" 3005 "Invalid" 3004 "Invalid" 3003 "Invalid" 3002 "Invalid" 3001 "Invalid" ;
VAL_ 533 BCU_OBCReqCur 63 "Invalid" 62 "Invalid" 61 "Invalid" 60 "Invalid" 59 "Invalid" 58 "Invalid" 57 "Invalid" 56 "Invalid" 55 "Invalid" 54 "Invalid" 53 "Invalid" 52 "Invalid" 51 "Invalid" ;
VAL_ 533 BCU_OBCWorkModCmd 3 "Reserved" 2 "Constant Voltage" 1 "Constant Current" 0 "Default" ;
VAL_ 533 BCU_OBCReqVlt 511 "Invalid" 510 "Invalid" 509 "Invalid" 508 "Invalid" 507 "Invalid" 506 "Invalid" 505 "Invalid" 504 "Invalid" 503 "Invalid" 502 "Invalid" 501 "Invalid" ;
VAL_ 533 BCU_OBCMaxCurOut 63 "Invalid" 62 "Invalid" 61 "Invalid" 60 "Invalid" 59 "Invalid" 58 "Invalid" 57 "Invalid" 56 "Invalid" 55 "Invalid" 54 "Invalid" 53 "Invalid" 52 "Invalid" 51 "Invalid" ;
VAL_ 533 BCU_OBCMaxVltOut 511 "Invalid" 510 "Invalid" 509 "Invalid" 508 "Invalid" 507 "Invalid" 506 "Invalid" 505 "Invalid" 504 "Invalid" 503 "Invalid" 502 "Invalid" 501 "Invalid" ;
VAL_ 538 BCU_AllCellNr 127 "Invalid" 126 "Invalid" 125 "Invalid" 124 "Invalid" 123 "Invalid" 122 "Invalid" 121 "Invalid" ;
VAL_ 538 BCU_SglChrgCp 4095 "Invalid" 4094 "Invalid" 4093 "Invalid" 4092 "Invalid" 4091 "Invalid" 4090 "Invalid" 4089 "Invalid" 4088 "Invalid" 4087 "Invalid" 4086 "Invalid" 4085 "Invalid" 4084 "Invalid" 4083 "Invalid" 4082 "Invalid" 4081 "Invalid" 4080 "Invalid" 4079 "Invalid" 4078 "Invalid" 4077 "Invalid" 4076 "Invalid" 4075 "Invalid" 4074 "Invalid" 4073 "Invalid" 4072 "Invalid" 4071 "Invalid" 4070 "Invalid" 4069 "Invalid" 4068 "Invalid" 4067 "Invalid" 4066 "Invalid" 4065 "Invalid" 4064 "Invalid" 4063 "Invalid" 4062 "Invalid" 4061 "Invalid" 4060 "Invalid" 4059 "Invalid" 4058 "Invalid" 4057 "Invalid" 4056 "Invalid" 4055 "Invalid" 4054 "Invalid" 4053 "Invalid" 4052 "Invalid" 4051 "Invalid" 4050 "Invalid" 4049 "Invalid" 4048 "Invalid" 4047 "Invalid" 4046 "Invalid" 4045 "Invalid" 4044 "Invalid" 4043 "Invalid" 4042 "Invalid" 4041 "Invalid" 4040 "Invalid" 4039 "Invalid" 4038 "Invalid" 4037 "Invalid" 4036 "Invalid" 4035 "Invalid" 4034 "Invalid" 4033 "Invalid" 4032 "Invalid" 4031 "Invalid" 4030 "Invalid" 4029 "Invalid" 4028 "Invalid" 4027 "Invalid" 4026 "Invalid" 4025 "Invalid" 4024 "Invalid" 4023 "Invalid" 4022 "Invalid" 4021 "Invalid" 4020 "Invalid" 4019 "Invalid" 4018 "Invalid" 4017 "Invalid" 4016 "Invalid" 4015 "Invalid" 4014 "Invalid" 4013 "Invalid" 4012 "Invalid" 4011 "Invalid" 4010 "Invalid" 4009 "Invalid" 4008 "Invalid" 4007 "Invalid" 4006 "Invalid" 4005 "Invalid" 4004 "Invalid" 4003 "Invalid" 4002 "Invalid" 4001 "Invalid" ;
VAL_ 538 BCU_SglChrgEgy 1023 "Invalid" 1022 "Invalid" 1021 "Invalid" 1020 "Invalid" 1019 "Invalid" 1018 "Invalid" 1017 "Invalid" 1016 "Invalid" 1015 "Invalid" 1014 "Invalid" 1013 "Invalid" 1012 "Invalid" 1011 "Invalid" 1010 "Invalid" 1009 "Invalid" 1008 "Invalid" 1007 "Invalid" 1006 "Invalid" 1005 "Invalid" 1004 "Invalid" 1003 "Invalid" 1002 "Invalid" 1001 "Invalid" ;
VAL_ 538 BCU_SglDschrgCp 4095 "Invalid" 4094 "Invalid" 4093 "Invalid" 4092 "Invalid" 4091 "Invalid" 4090 "Invalid" 4089 "Invalid" 4088 "Invalid" 4087 "Invalid" 4086 "Invalid" 4085 "Invalid" 4084 "Invalid" 4083 "Invalid" 4082 "Invalid" 4081 "Invalid" 4080 "Invalid" 4079 "Invalid" 4078 "Invalid" 4077 "Invalid" 4076 "Invalid" 4075 "Invalid" 4074 "Invalid" 4073 "Invalid" 4072 "Invalid" 4071 "Invalid" 4070 "Invalid" 4069 "Invalid" 4068 "Invalid" 4067 "Invalid" 4066 "Invalid" 4065 "Invalid" 4064 "Invalid" 4063 "Invalid" 4062 "Invalid" 4061 "Invalid" 4060 "Invalid" 4059 "Invalid" 4058 "Invalid" 4057 "Invalid" 4056 "Invalid" 4055 "Invalid" 4054 "Invalid" 4053 "Invalid" 4052 "Invalid" 4051 "Invalid" 4050 "Invalid" 4049 "Invalid" 4048 "Invalid" 4047 "Invalid" 4046 "Invalid" 4045 "Invalid" 4044 "Invalid" 4043 "Invalid" 4042 "Invalid" 4041 "Invalid" 4040 "Invalid" 4039 "Invalid" 4038 "Invalid" 4037 "Invalid" 4036 "Invalid" 4035 "Invalid" 4034 "Invalid" 4033 "Invalid" 4032 "Invalid" 4031 "Invalid" 4030 "Invalid" 4029 "Invalid" 4028 "Invalid" 4027 "Invalid" 4026 "Invalid" 4025 "Invalid" 4024 "Invalid" 4023 "Invalid" 4022 "Invalid" 4021 "Invalid" 4020 "Invalid" 4019 "Invalid" 4018 "Invalid" 4017 "Invalid" 4016 "Invalid" 4015 "Invalid" 4014 "Invalid" 4013 "Invalid" 4012 "Invalid" 4011 "Invalid" 4010 "Invalid" 4009 "Invalid" 4008 "Invalid" 4007 "Invalid" 4006 "Invalid" 4005 "Invalid" 4004 "Invalid" 4003 "Invalid" 4002 "Invalid" 4001 "Invalid" ;
VAL_ 538 BCU_SglDschrgEgy 1023 "Invalid" 1022 "Invalid" 1021 "Invalid" 1020 "Invalid" 1019 "Invalid" 1018 "Invalid" 1017 "Invalid" 1016 "Invalid" 1015 "Invalid" 1014 "Invalid" 1013 "Invalid" 1012 "Invalid" 1011 "Invalid" 1010 "Invalid" 1009 "Invalid" 1008 "Invalid" 1007 "Invalid" 1006 "Invalid" 1005 "Invalid" 1004 "Invalid" 1003 "Invalid" 1002 "Invalid" 1001 "Invalid" ;
VAL_ 538 BCU_BalnFlg001_RM 1 "Balance Closed" 0 "Balance Open" ;
VAL_ 538 BCU_BalnFlg002_RM 1 "Balance Closed" 0 "Balance Open" ;
VAL_ 538 BCU_BalnFlg003_RM 1 "Balance Closed" 0 "Balance Open" ;
VAL_ 538 BCU_BalnFlg004_RM 1 "Balance Closed" 0 "Balance Open" ;
VAL_ 538 BCU_BalnFlg005_RM 1 "Balance Closed" 0 "Balance Open" ;
VAL_ 538 BCU_BalnFlg006_RM 1 "Balance Closed" 0 "Balance Open" ;
VAL_ 538 BCU_BalnFlg007_RM 1 "Balance Closed" 0 "Balance Open" ;
VAL_ 538 BCU_BalnFlg008_RM 1 "Balance Closed" 0 "Balance Open" ;
VAL_ 538 BCU_BalnFlg009_RM 1 "Balance Closed" 0 "Balance Open" ;
VAL_ 538 BCU_BalnFlg010_RM 1 "Balance Closed" 0 "Balance Open" ;
VAL_ 538 BCU_BalnFlg011_RM 1 "Balance Closed" 0 "Balance Open" ;
VAL_ 538 BCU_BalnFlg012_RM 1 "Balance Closed" 0 "Balance Open" ;
VAL_ 538 BCU_BalnFlg013_RM 1 "Balance Closed" 0 "Balance Open" ;
VAL_ 539 BCU_TotalDschrgCp 65535 "Invalid" 65534 "Invalid" 65533 "Invalid" 65532 "Invalid" 65531 "Invalid" 65530 "Invalid" 65529 "Invalid" 65528 "Invalid" 65527 "Invalid" 65526 "Invalid" 65525 "Invalid" 65524 "Invalid" 65523 "Invalid" 65522 "Invalid" 65521 "Invalid" 65520 "Invalid" 65519 "Invalid" 65518 "Invalid" 65517 "Invalid" 65516 "Invalid" 65515 "Invalid" 65514 "Invalid" 65513 "Invalid" 65512 "Invalid" 65511 "Invalid" 65510 "Invalid" 65509 "Invalid" 65508 "Invalid" 65507 "Invalid" 65506 "Invalid" 65505 "Invalid" 65504 "Invalid" 65503 "Invalid" 65502 "Invalid" 65501 "Invalid" 65500 "Invalid" 65499 "Invalid" 65498 "Invalid" 65497 "Invalid" 65496 "Invalid" 65495 "Invalid" 65494 "Invalid" 65493 "Invalid" 65492 "Invalid" 65491 "Invalid" 65490 "Invalid" 65489 "Invalid" 65488 "Invalid" 65487 "Invalid" 65486 "Invalid" 65485 "Invalid" 65484 "Invalid" 65483 "Invalid" 65482 "Invalid" 65481 "Invalid" 65480 "Invalid" 65479 "Invalid" 65478 "Invalid" 65477 "Invalid" 65476 "Invalid" 65475 "Invalid" 65474 "Invalid" 65473 "Invalid" 65472 "Invalid" 65471 "Invalid" 65470 "Invalid" 65469 "Invalid" 65468 "Invalid" 65467 "Invalid" 65466 "Invalid" 65465 "Invalid" 65464 "Invalid" 65463 "Invalid" 65462 "Invalid" 65461 "Invalid" 65460 "Invalid" 65459 "Invalid" 65458 "Invalid" 65457 "Invalid" 65456 "Invalid" 65455 "Invalid" 65454 "Invalid" 65453 "Invalid" 65452 "Invalid" 65451 "Invalid" 65450 "Invalid" 65449 "Invalid" 65448 "Invalid" 65447 "Invalid" 65446 "Invalid" 65445 "Invalid" 65444 "Invalid" 65443 "Invalid" 65442 "Invalid" 65441 "Invalid" 65440 "Invalid" 65439 "Invalid" 65438 "Invalid" 65437 "Invalid" 65436 "Invalid" 65435 "Invalid" 65434 "Invalid" 65433 "Invalid" 65432 "Invalid" 65431 "Invalid" 65430 "Invalid" 65429 "Invalid" 65428 "Invalid" 65427 "Invalid" 65426 "Invalid" 65425 "Invalid" 65424 "Invalid" 65423 "Invalid" 65422 "Invalid" 65421 "Invalid" 65420 "Invalid" 65419 "Invalid" 65418 "Invalid" 65417 "Invalid" 65416 "Invalid" 65415 "Invalid" 65414 "Invalid" 65413 "Invalid" 65412 "Invalid" 65411 "Invalid" 65410 "Invalid" 65409 "Invalid" 65408 "Invalid" 65407 "Invalid" 65406 "Invalid" 65405 "Invalid" 65404 "Invalid" 65403 "Invalid" 65402 "Invalid" 65401 "Invalid" 65400 "Invalid" 65399 "Invalid" 65398 "Invalid" 65397 "Invalid" 65396 "Invalid" 65395 "Invalid" 65394 "Invalid" 65393 "Invalid" 65392 "Invalid" 65391 "Invalid" 65390 "Invalid" 65389 "Invalid" 65388 "Invalid" 65387 "Invalid" 65386 "Invalid" 65385 "Invalid" 65384 "Invalid" 65383 "Invalid" 65382 "Invalid" 65381 "Invalid" 65380 "Invalid" 65379 "Invalid" 65378 "Invalid" 65377 "Invalid" 65376 "Invalid" 65375 "Invalid" 65374 "Invalid" 65373 "Invalid" 65372 "Invalid" 65371 "Invalid" 65370 "Invalid" 65369 "Invalid" 65368 "Invalid" 65367 "Invalid" 65366 "Invalid" 65365 "Invalid" 65364 "Invalid" 65363 "Invalid" 65362 "Invalid" 65361 "Invalid" 65360 "Invalid" 65359 "Invalid" 65358 "Invalid" 65357 "Invalid" 65356 "Invalid" 65355 "Invalid" 65354 "Invalid" 65353 "Invalid" 65352 "Invalid" 65351 "Invalid" 65350 "Invalid" 65349 "Invalid" 65348 "Invalid" 65347 "Invalid" 65346 "Invalid" 65345 "Invalid" 65344 "Invalid" 65343 "Invalid" 65342 "Invalid" 65341 "Invalid" 65340 "Invalid" 65339 "Invalid" 65338 "Invalid" 65337 "Invalid" 65336 "Invalid" 65335 "Invalid" 65334 "Invalid" 65333 "Invalid" 65332 "Invalid" 65331 "Invalid" 65330 "Invalid" 65329 "Invalid" 65328 "Invalid" 65327 "Invalid" 65326 "Invalid" 65325 "Invalid" 65324 "Invalid" 65323 "Invalid" 65322 "Invalid" 65321 "Invalid" 65320 "Invalid" 65319 "Invalid" 65318 "Invalid" 65317 "Invalid" 65316 "Invalid" 65315 "Invalid" 65314 "Invalid" 65313 "Invalid" 65312 "Invalid" 65311 "Invalid" 65310 "Invalid" 65309 "Invalid" 65308 "Invalid" 65307 "Invalid" 65306 "Invalid" 65305 "Invalid" 65304 "Invalid" 65303 "Invalid" 65302 "Invalid" 65301 "Invalid" 65300 "Invalid" 65299 "Invalid" 65298 "Invalid" 65297 "Invalid" 65296 "Invalid" 65295 "Invalid" 65294 "Invalid" 65293 "Invalid" 65292 "Invalid" 65291 "Invalid" 65290 "Invalid" 65289 "Invalid" 65288 "Invalid" 65287 "Invalid" 65286 "Invalid" 65285 "Invalid" 65284 "Invalid" 65283 "Invalid" 65282 "Invalid" 65281 "Invalid" 65280 "Invalid" 65279 "Invalid" 65278 "Invalid" 65277 "Invalid" 65276 "Invalid" 65275 "Invalid" 65274 "Invalid" 65273 "Invalid" 65272 "Invalid" 65271 "Invalid" 65270 "Invalid" 65269 "Invalid" 65268 "Invalid" 65267 "Invalid" 65266 "Invalid" 65265 "Invalid" 65264 "Invalid" 65263 "Invalid" 65262 "Invalid" 65261 "Invalid" 65260 "Invalid" 65259 "Invalid" 65258 "Invalid" 65257 "Invalid" 65256 "Invalid" 65255 "Invalid" 65254 "Invalid" 65253 "Invalid" 65252 "Invalid" 65251 "Invalid" 65250 "Invalid" 65249 "Invalid" 65248 "Invalid" 65247 "Invalid" 65246 "Invalid" 65245 "Invalid" 65244 "Invalid" 65243 "Invalid" 65242 "Invalid" 65241 "Invalid" 65240 "Invalid" 65239 "Invalid" 65238 "Invalid" 65237 "Invalid" 65236 "Invalid" 65235 "Invalid" 65234 "Invalid" 65233 "Invalid" 65232 "Invalid" 65231 "Invalid" 65230 "Invalid" 65229 "Invalid" 65228 "Invalid" 65227 "Invalid" 65226 "Invalid" 65225 "Invalid" 65224 "Invalid" 65223 "Invalid" 65222 "Invalid" 65221 "Invalid" 65220 "Invalid" 65219 "Invalid" 65218 "Invalid" 65217 "Invalid" 65216 "Invalid" 65215 "Invalid" 65214 "Invalid" 65213 "Invalid" 65212 "Invalid" 65211 "Invalid" 65210 "Invalid" 65209 "Invalid" 65208 "Invalid" 65207 "Invalid" 65206 "Invalid" 65205 "Invalid" 65204 "Invalid" 65203 "Invalid" 65202 "Invalid" 65201 "Invalid" 65200 "Invalid" 65199 "Invalid" 65198 "Invalid" 65197 "Invalid" 65196 "Invalid" 65195 "Invalid" 65194 "Invalid" 65193 "Invalid" 65192 "Invalid" 65191 "Invalid" 65190 "Invalid" 65189 "Invalid" 65188 "Invalid" 65187 "Invalid" 65186 "Invalid" 65185 "Invalid" 65184 "Invalid" 65183 "Invalid" 65182 "Invalid" 65181 "Invalid" 65180 "Invalid" 65179 "Invalid" 65178 "Invalid" 65177 "Invalid" 65176 "Invalid" 65175 "Invalid" 65174 "Invalid" 65173 "Invalid" 65172 "Invalid" 65171 "Invalid" 65170 "Invalid" 65169 "Invalid" 65168 "Invalid" 65167 "Invalid" 65166 "Invalid" 65165 "Invalid" 65164 "Invalid" 65163 "Invalid" 65162 "Invalid" 65161 "Invalid" 65160 "Invalid" 65159 "Invalid" 65158 "Invalid" 65157 "Invalid" 65156 "Invalid" 65155 "Invalid" 65154 "Invalid" 65153 "Invalid" 65152 "Invalid" 65151 "Invalid" 65150 "Invalid" 65149 "Invalid" 65148 "Invalid" 65147 "Invalid" 65146 "Invalid" 65145 "Invalid" 65144 "Invalid" 65143 "Invalid" 65142 "Invalid" 65141 "Invalid" 65140 "Invalid" 65139 "Invalid" 65138 "Invalid" 65137 "Invalid" 65136 "Invalid" 65135 "Invalid" 65134 "Invalid" 65133 "Invalid" 65132 "Invalid" 65131 "Invalid" 65130 "Invalid" 65129 "Invalid" 65128 "Invalid" 65127 "Invalid" 65126 "Invalid" 65125 "Invalid" 65124 "Invalid" 65123 "Invalid" 65122 "Invalid" 65121 "Invalid" 65120 "Invalid" 65119 "Invalid" 65118 "Invalid" 65117 "Invalid" 65116 "Invalid" 65115 "Invalid" 65114 "Invalid" 65113 "Invalid" 65112 "Invalid" 65111 "Invalid" 65110 "Invalid" 65109 "Invalid" 65108 "Invalid" 65107 "Invalid" 65106 "Invalid" 65105 "Invalid" 65104 "Invalid" 65103 "Invalid" 65102 "Invalid" 65101 "Invalid" 65100 "Invalid" 65099 "Invalid" 65098 "Invalid" 65097 "Invalid" 65096 "Invalid" 65095 "Invalid" 65094 "Invalid" 65093 "Invalid" 65092 "Invalid" 65091 "Invalid" 65090 "Invalid" 65089 "Invalid" 65088 "Invalid" 65087 "Invalid" 65086 "Invalid" 65085 "Invalid" 65084 "Invalid" 65083 "Invalid" 65082 "Invalid" 65081 "Invalid" 65080 "Invalid" 65079 "Invalid" 65078 "Invalid" 65077 "Invalid" 65076 "Invalid" 65075 "Invalid" 65074 "Invalid" 65073 "Invalid" 65072 "Invalid" 65071 "Invalid" 65070 "Invalid" 65069 "Invalid" 65068 "Invalid" 65067 "Invalid" 65066 "Invalid" 65065 "Invalid" 65064 "Invalid" 65063 "Invalid" 65062 "Invalid" 65061 "Invalid" 65060 "Invalid" 65059 "Invalid" 65058 "Invalid" 65057 "Invalid" 65056 "Invalid" 65055 "Invalid" 65054 "Invalid" 65053 "Invalid" 65052 "Invalid" 65051 "Invalid" 65050 "Invalid" 65049 "Invalid" 65048 "Invalid" 65047 "Invalid" 65046 "Invalid" 65045 "Invalid" 65044 "Invalid" 65043 "Invalid" 65042 "Invalid" 65041 "Invalid" 65040 "Invalid" 65039 "Invalid" 65038 "Invalid" 65037 "Invalid" 65036 "Invalid" 65035 "Invalid" 65034 "Invalid" 65033 "Invalid" 65032 "Invalid" 65031 "Invalid" 65030 "Invalid" 65029 "Invalid" 65028 "Invalid" 65027 "Invalid" 65026 "Invalid" 65025 "Invalid" 65024 "Invalid" 65023 "Invalid" 65022 "Invalid" 65021 "Invalid" 65020 "Invalid" 65019 "Invalid" 65018 "Invalid" 65017 "Invalid" 65016 "Invalid" 65015 "Invalid" 65014 "Invalid" 65013 "Invalid" 65012 "Invalid" 65011 "Invalid" 65010 "Invalid" 65009 "Invalid" 65008 "Invalid" 65007 "Invalid" 65006 "Invalid" 65005 "Invalid" 65004 "Invalid" 65003 "Invalid" 65002 "Invalid" 65001 "Invalid" ;
VAL_ 539 BCU_TotalDschrgEgy 65535 "Invalid" 65534 "Invalid" 65533 "Invalid" 65532 "Invalid" 65531 "Invalid" 65530 "Invalid" 65529 "Invalid" 65528 "Invalid" 65527 "Invalid" 65526 "Invalid" 65525 "Invalid" 65524 "Invalid" 65523 "Invalid" 65522 "Invalid" 65521 "Invalid" 65520 "Invalid" 65519 "Invalid" 65518 "Invalid" 65517 "Invalid" 65516 "Invalid" 65515 "Invalid" 65514 "Invalid" 65513 "Invalid" 65512 "Invalid" 65511 "Invalid" 65510 "Invalid" 65509 "Invalid" 65508 "Invalid" 65507 "Invalid" 65506 "Invalid" 65505 "Invalid" 65504 "Invalid" 65503 "Invalid" 65502 "Invalid" 65501 "Invalid" 65500 "Invalid" 65499 "Invalid" 65498 "Invalid" 65497 "Invalid" 65496 "Invalid" 65495 "Invalid" 65494 "Invalid" 65493 "Invalid" 65492 "Invalid" 65491 "Invalid" 65490 "Invalid" 65489 "Invalid" 65488 "Invalid" 65487 "Invalid" 65486 "Invalid" 65485 "Invalid" 65484 "Invalid" 65483 "Invalid" 65482 "Invalid" 65481 "Invalid" 65480 "Invalid" 65479 "Invalid" 65478 "Invalid" 65477 "Invalid" 65476 "Invalid" 65475 "Invalid" 65474 "Invalid" 65473 "Invalid" 65472 "Invalid" 65471 "Invalid" 65470 "Invalid" 65469 "Invalid" 65468 "Invalid" 65467 "Invalid" 65466 "Invalid" 65465 "Invalid" 65464 "Invalid" 65463 "Invalid" 65462 "Invalid" 65461 "Invalid" 65460 "Invalid" 65459 "Invalid" 65458 "Invalid" 65457 "Invalid" 65456 "Invalid" 65455 "Invalid" 65454 "Invalid" 65453 "Invalid" 65452 "Invalid" 65451 "Invalid" 65450 "Invalid" 65449 "Invalid" 65448 "Invalid" 65447 "Invalid" 65446 "Invalid" 65445 "Invalid" 65444 "Invalid" 65443 "Invalid" 65442 "Invalid" 65441 "Invalid" 65440 "Invalid" 65439 "Invalid" 65438 "Invalid" 65437 "Invalid" 65436 "Invalid" 65435 "Invalid" 65434 "Invalid" 65433 "Invalid" 65432 "Invalid" 65431 "Invalid" 65430 "Invalid" 65429 "Invalid" 65428 "Invalid" 65427 "Invalid" 65426 "Invalid" 65425 "Invalid" 65424 "Invalid" 65423 "Invalid" 65422 "Invalid" 65421 "Invalid" 65420 "Invalid" 65419 "Invalid" 65418 "Invalid" 65417 "Invalid" 65416 "Invalid" 65415 "Invalid" 65414 "Invalid" 65413 "Invalid" 65412 "Invalid" 65411 "Invalid" 65410 "Invalid" 65409 "Invalid" 65408 "Invalid" 65407 "Invalid" 65406 "Invalid" 65405 "Invalid" 65404 "Invalid" 65403 "Invalid" 65402 "Invalid" 65401 "Invalid" 65400 "Invalid" 65399 "Invalid" 65398 "Invalid" 65397 "Invalid" 65396 "Invalid" 65395 "Invalid" 65394 "Invalid" 65393 "Invalid" 65392 "Invalid" 65391 "Invalid" 65390 "Invalid" 65389 "Invalid" 65388 "Invalid" 65387 "Invalid" 65386 "Invalid" 65385 "Invalid" 65384 "Invalid" 65383 "Invalid" 65382 "Invalid" 65381 "Invalid" 65380 "Invalid" 65379 "Invalid" 65378 "Invalid" 65377 "Invalid" 65376 "Invalid" 65375 "Invalid" 65374 "Invalid" 65373 "Invalid" 65372 "Invalid" 65371 "Invalid" 65370 "Invalid" 65369 "Invalid" 65368 "Invalid" 65367 "Invalid" 65366 "Invalid" 65365 "Invalid" 65364 "Invalid" 65363 "Invalid" 65362 "Invalid" 65361 "Invalid" 65360 "Invalid" 65359 "Invalid" 65358 "Invalid" 65357 "Invalid" 65356 "Invalid" 65355 "Invalid" 65354 "Invalid" 65353 "Invalid" 65352 "Invalid" 65351 "Invalid" 65350 "Invalid" 65349 "Invalid" 65348 "Invalid" 65347 "Invalid" 65346 "Invalid" 65345 "Invalid" 65344 "Invalid" 65343 "Invalid" 65342 "Invalid" 65341 "Invalid" 65340 "Invalid" 65339 "Invalid" 65338 "Invalid" 65337 "Invalid" 65336 "Invalid" 65335 "Invalid" 65334 "Invalid" 65333 "Invalid" 65332 "Invalid" 65331 "Invalid" 65330 "Invalid" 65329 "Invalid" 65328 "Invalid" 65327 "Invalid" 65326 "Invalid" 65325 "Invalid" 65324 "Invalid" 65323 "Invalid" 65322 "Invalid" 65321 "Invalid" 65320 "Invalid" 65319 "Invalid" 65318 "Invalid" 65317 "Invalid" 65316 "Invalid" 65315 "Invalid" 65314 "Invalid" 65313 "Invalid" 65312 "Invalid" 65311 "Invalid" 65310 "Invalid" 65309 "Invalid" 65308 "Invalid" 65307 "Invalid" 65306 "Invalid" 65305 "Invalid" 65304 "Invalid" 65303 "Invalid" 65302 "Invalid" 65301 "Invalid" 65300 "Invalid" 65299 "Invalid" 65298 "Invalid" 65297 "Invalid" 65296 "Invalid" 65295 "Invalid" 65294 "Invalid" 65293 "Invalid" 65292 "Invalid" 65291 "Invalid" 65290 "Invalid" 65289 "Invalid" 65288 "Invalid" 65287 "Invalid" 65286 "Invalid" 65285 "Invalid" 65284 "Invalid" 65283 "Invalid" 65282 "Invalid" 65281 "Invalid" 65280 "Invalid" 65279 "Invalid" 65278 "Invalid" 65277 "Invalid" 65276 "Invalid" 65275 "Invalid" 65274 "Invalid" 65273 "Invalid" 65272 "Invalid" 65271 "Invalid" 65270 "Invalid" 65269 "Invalid" 65268 "Invalid" 65267 "Invalid" 65266 "Invalid" 65265 "Invalid" 65264 "Invalid" 65263 "Invalid" 65262 "Invalid" 65261 "Invalid" 65260 "Invalid" 65259 "Invalid" 65258 "Invalid" 65257 "Invalid" 65256 "Invalid" 65255 "Invalid" 65254 "Invalid" 65253 "Invalid" 65252 "Invalid" 65251 "Invalid" 65250 "Invalid" 65249 "Invalid" 65248 "Invalid" 65247 "Invalid" 65246 "Invalid" 65245 "Invalid" 65244 "Invalid" 65243 "Invalid" 65242 "Invalid" 65241 "Invalid" 65240 "Invalid" 65239 "Invalid" 65238 "Invalid" 65237 "Invalid" 65236 "Invalid" 65235 "Invalid" 65234 "Invalid" 65233 "Invalid" 65232 "Invalid" 65231 "Invalid" 65230 "Invalid" 65229 "Invalid" 65228 "Invalid" 65227 "Invalid" 65226 "Invalid" 65225 "Invalid" 65224 "Invalid" 65223 "Invalid" 65222 "Invalid" 65221 "Invalid" 65220 "Invalid" 65219 "Invalid" 65218 "Invalid" 65217 "Invalid" 65216 "Invalid" 65215 "Invalid" 65214 "Invalid" 65213 "Invalid" 65212 "Invalid" 65211 "Invalid" 65210 "Invalid" 65209 "Invalid" 65208 "Invalid" 65207 "Invalid" 65206 "Invalid" 65205 "Invalid" 65204 "Invalid" 65203 "Invalid" 65202 "Invalid" 65201 "Invalid" 65200 "Invalid" 65199 "Invalid" 65198 "Invalid" 65197 "Invalid" 65196 "Invalid" 65195 "Invalid" 65194 "Invalid" 65193 "Invalid" 65192 "Invalid" 65191 "Invalid" 65190 "Invalid" 65189 "Invalid" 65188 "Invalid" 65187 "Invalid" 65186 "Invalid" 65185 "Invalid" 65184 "Invalid" 65183 "Invalid" 65182 "Invalid" 65181 "Invalid" 65180 "Invalid" 65179 "Invalid" 65178 "Invalid" 65177 "Invalid" 65176 "Invalid" 65175 "Invalid" 65174 "Invalid" 65173 "Invalid" 65172 "Invalid" 65171 "Invalid" 65170 "Invalid" 65169 "Invalid" 65168 "Invalid" 65167 "Invalid" 65166 "Invalid" 65165 "Invalid" 65164 "Invalid" 65163 "Invalid" 65162 "Invalid" 65161 "Invalid" 65160 "Invalid" 65159 "Invalid" 65158 "Invalid" 65157 "Invalid" 65156 "Invalid" 65155 "Invalid" 65154 "Invalid" 65153 "Invalid" 65152 "Invalid" 65151 "Invalid" 65150 "Invalid" 65149 "Invalid" 65148 "Invalid" 65147 "Invalid" 65146 "Invalid" 65145 "Invalid" 65144 "Invalid" 65143 "Invalid" 65142 "Invalid" 65141 "Invalid" 65140 "Invalid" 65139 "Invalid" 65138 "Invalid" 65137 "Invalid" 65136 "Invalid" 65135 "Invalid" 65134 "Invalid" 65133 "Invalid" 65132 "Invalid" 65131 "Invalid" 65130 "Invalid" 65129 "Invalid" 65128 "Invalid" 65127 "Invalid" 65126 "Invalid" 65125 "Invalid" 65124 "Invalid" 65123 "Invalid" 65122 "Invalid" 65121 "Invalid" 65120 "Invalid" 65119 "Invalid" 65118 "Invalid" 65117 "Invalid" 65116 "Invalid" 65115 "Invalid" 65114 "Invalid" 65113 "Invalid" 65112 "Invalid" 65111 "Invalid" 65110 "Invalid" 65109 "Invalid" 65108 "Invalid" 65107 "Invalid" 65106 "Invalid" 65105 "Invalid" 65104 "Invalid" 65103 "Invalid" 65102 "Invalid" 65101 "Invalid" 65100 "Invalid" 65099 "Invalid" 65098 "Invalid" 65097 "Invalid" 65096 "Invalid" 65095 "Invalid" 65094 "Invalid" 65093 "Invalid" 65092 "Invalid" 65091 "Invalid" 65090 "Invalid" 65089 "Invalid" 65088 "Invalid" 65087 "Invalid" 65086 "Invalid" 65085 "Invalid" 65084 "Invalid" 65083 "Invalid" 65082 "Invalid" 65081 "Invalid" 65080 "Invalid" 65079 "Invalid" 65078 "Invalid" 65077 "Invalid" 65076 "Invalid" 65075 "Invalid" 65074 "Invalid" 65073 "Invalid" 65072 "Invalid" 65071 "Invalid" 65070 "Invalid" 65069 "Invalid" 65068 "Invalid" 65067 "Invalid" 65066 "Invalid" 65065 "Invalid" 65064 "Invalid" 65063 "Invalid" 65062 "Invalid" 65061 "Invalid" 65060 "Invalid" 65059 "Invalid" 65058 "Invalid" 65057 "Invalid" 65056 "Invalid" 65055 "Invalid" 65054 "Invalid" 65053 "Invalid" 65052 "Invalid" 65051 "Invalid" 65050 "Invalid" 65049 "Invalid" 65048 "Invalid" 65047 "Invalid" 65046 "Invalid" 65045 "Invalid" 65044 "Invalid" 65043 "Invalid" 65042 "Invalid" 65041 "Invalid" 65040 "Invalid" 65039 "Invalid" 65038 "Invalid" 65037 "Invalid" 65036 "Invalid" 65035 "Invalid" 65034 "Invalid" 65033 "Invalid" 65032 "Invalid" 65031 "Invalid" 65030 "Invalid" 65029 "Invalid" 65028 "Invalid" 65027 "Invalid" 65026 "Invalid" 65025 "Invalid" 65024 "Invalid" 65023 "Invalid" 65022 "Invalid" 65021 "Invalid" 65020 "Invalid" 65019 "Invalid" 65018 "Invalid" 65017 "Invalid" 65016 "Invalid" 65015 "Invalid" 65014 "Invalid" 65013 "Invalid" 65012 "Invalid" 65011 "Invalid" 65010 "Invalid" 65009 "Invalid" 65008 "Invalid" 65007 "Invalid" 65006 "Invalid" 65005 "Invalid" 65004 "Invalid" 65003 "Invalid" 65002 "Invalid" 65001 "Invalid" ;
VAL_ 539 BCU_TotalChrgCp 65535 "Invalid" 65534 "Invalid" 65533 "Invalid" 65532 "Invalid" 65531 "Invalid" 65530 "Invalid" 65529 "Invalid" 65528 "Invalid" 65527 "Invalid" 65526 "Invalid" 65525 "Invalid" 65524 "Invalid" 65523 "Invalid" 65522 "Invalid" 65521 "Invalid" 65520 "Invalid" 65519 "Invalid" 65518 "Invalid" 65517 "Invalid" 65516 "Invalid" 65515 "Invalid" 65514 "Invalid" 65513 "Invalid" 65512 "Invalid" 65511 "Invalid" 65510 "Invalid" 65509 "Invalid" 65508 "Invalid" 65507 "Invalid" 65506 "Invalid" 65505 "Invalid" 65504 "Invalid" 65503 "Invalid" 65502 "Invalid" 65501 "Invalid" 65500 "Invalid" 65499 "Invalid" 65498 "Invalid" 65497 "Invalid" 65496 "Invalid" 65495 "Invalid" 65494 "Invalid" 65493 "Invalid" 65492 "Invalid" 65491 "Invalid" 65490 "Invalid" 65489 "Invalid" 65488 "Invalid" 65487 "Invalid" 65486 "Invalid" 65485 "Invalid" 65484 "Invalid" 65483 "Invalid" 65482 "Invalid" 65481 "Invalid" 65480 "Invalid" 65479 "Invalid" 65478 "Invalid" 65477 "Invalid" 65476 "Invalid" 65475 "Invalid" 65474 "Invalid" 65473 "Invalid" 65472 "Invalid" 65471 "Invalid" 65470 "Invalid" 65469 "Invalid" 65468 "Invalid" 65467 "Invalid" 65466 "Invalid" 65465 "Invalid" 65464 "Invalid" 65463 "Invalid" 65462 "Invalid" 65461 "Invalid" 65460 "Invalid" 65459 "Invalid" 65458 "Invalid" 65457 "Invalid" 65456 "Invalid" 65455 "Invalid" 65454 "Invalid" 65453 "Invalid" 65452 "Invalid" 65451 "Invalid" 65450 "Invalid" 65449 "Invalid" 65448 "Invalid" 65447 "Invalid" 65446 "Invalid" 65445 "Invalid" 65444 "Invalid" 65443 "Invalid" 65442 "Invalid" 65441 "Invalid" 65440 "Invalid" 65439 "Invalid" 65438 "Invalid" 65437 "Invalid" 65436 "Invalid" 65435 "Invalid" 65434 "Invalid" 65433 "Invalid" 65432 "Invalid" 65431 "Invalid" 65430 "Invalid" 65429 "Invalid" 65428 "Invalid" 65427 "Invalid" 65426 "Invalid" 65425 "Invalid" 65424 "Invalid" 65423 "Invalid" 65422 "Invalid" 65421 "Invalid" 65420 "Invalid" 65419 "Invalid" 65418 "Invalid" 65417 "Invalid" 65416 "Invalid" 65415 "Invalid" 65414 "Invalid" 65413 "Invalid" 65412 "Invalid" 65411 "Invalid" 65410 "Invalid" 65409 "Invalid" 65408 "Invalid" 65407 "Invalid" 65406 "Invalid" 65405 "Invalid" 65404 "Invalid" 65403 "Invalid" 65402 "Invalid" 65401 "Invalid" 65400 "Invalid" 65399 "Invalid" 65398 "Invalid" 65397 "Invalid" 65396 "Invalid" 65395 "Invalid" 65394 "Invalid" 65393 "Invalid" 65392 "Invalid" 65391 "Invalid" 65390 "Invalid" 65389 "Invalid" 65388 "Invalid" 65387 "Invalid" 65386 "Invalid" 65385 "Invalid" 65384 "Invalid" 65383 "Invalid" 65382 "Invalid" 65381 "Invalid" 65380 "Invalid" 65379 "Invalid" 65378 "Invalid" 65377 "Invalid" 65376 "Invalid" 65375 "Invalid" 65374 "Invalid" 65373 "Invalid" 65372 "Invalid" 65371 "Invalid" 65370 "Invalid" 65369 "Invalid" 65368 "Invalid" 65367 "Invalid" 65366 "Invalid" 65365 "Invalid" 65364 "Invalid" 65363 "Invalid" 65362 "Invalid" 65361 "Invalid" 65360 "Invalid" 65359 "Invalid" 65358 "Invalid" 65357 "Invalid" 65356 "Invalid" 65355 "Invalid" 65354 "Invalid" 65353 "Invalid" 65352 "Invalid" 65351 "Invalid" 65350 "Invalid" 65349 "Invalid" 65348 "Invalid" 65347 "Invalid" 65346 "Invalid" 65345 "Invalid" 65344 "Invalid" 65343 "Invalid" 65342 "Invalid" 65341 "Invalid" 65340 "Invalid" 65339 "Invalid" 65338 "Invalid" 65337 "Invalid" 65336 "Invalid" 65335 "Invalid" 65334 "Invalid" 65333 "Invalid" 65332 "Invalid" 65331 "Invalid" 65330 "Invalid" 65329 "Invalid" 65328 "Invalid" 65327 "Invalid" 65326 "Invalid" 65325 "Invalid" 65324 "Invalid" 65323 "Invalid" 65322 "Invalid" 65321 "Invalid" 65320 "Invalid" 65319 "Invalid" 65318 "Invalid" 65317 "Invalid" 65316 "Invalid" 65315 "Invalid" 65314 "Invalid" 65313 "Invalid" 65312 "Invalid" 65311 "Invalid" 65310 "Invalid" 65309 "Invalid" 65308 "Invalid" 65307 "Invalid" 65306 "Invalid" 65305 "Invalid" 65304 "Invalid" 65303 "Invalid" 65302 "Invalid" 65301 "Invalid" 65300 "Invalid" 65299 "Invalid" 65298 "Invalid" 65297 "Invalid" 65296 "Invalid" 65295 "Invalid" 65294 "Invalid" 65293 "Invalid" 65292 "Invalid" 65291 "Invalid" 65290 "Invalid" 65289 "Invalid" 65288 "Invalid" 65287 "Invalid" 65286 "Invalid" 65285 "Invalid" 65284 "Invalid" 65283 "Invalid" 65282 "Invalid" 65281 "Invalid" 65280 "Invalid" 65279 "Invalid" 65278 "Invalid" 65277 "Invalid" 65276 "Invalid" 65275 "Invalid" 65274 "Invalid" 65273 "Invalid" 65272 "Invalid" 65271 "Invalid" 65270 "Invalid" 65269 "Invalid" 65268 "Invalid" 65267 "Invalid" 65266 "Invalid" 65265 "Invalid" 65264 "Invalid" 65263 "Invalid" 65262 "Invalid" 65261 "Invalid" 65260 "Invalid" 65259 "Invalid" 65258 "Invalid" 65257 "Invalid" 65256 "Invalid" 65255 "Invalid" 65254 "Invalid" 65253 "Invalid" 65252 "Invalid" 65251 "Invalid" 65250 "Invalid" 65249 "Invalid" 65248 "Invalid" 65247 "Invalid" 65246 "Invalid" 65245 "Invalid" 65244 "Invalid" 65243 "Invalid" 65242 "Invalid" 65241 "Invalid" 65240 "Invalid" 65239 "Invalid" 65238 "Invalid" 65237 "Invalid" 65236 "Invalid" 65235 "Invalid" 65234 "Invalid" 65233 "Invalid" 65232 "Invalid" 65231 "Invalid" 65230 "Invalid" 65229 "Invalid" 65228 "Invalid" 65227 "Invalid" 65226 "Invalid" 65225 "Invalid" 65224 "Invalid" 65223 "Invalid" 65222 "Invalid" 65221 "Invalid" 65220 "Invalid" 65219 "Invalid" 65218 "Invalid" 65217 "Invalid" 65216 "Invalid" 65215 "Invalid" 65214 "Invalid" 65213 "Invalid" 65212 "Invalid" 65211 "Invalid" 65210 "Invalid" 65209 "Invalid" 65208 "Invalid" 65207 "Invalid" 65206 "Invalid" 65205 "Invalid" 65204 "Invalid" 65203 "Invalid" 65202 "Invalid" 65201 "Invalid" 65200 "Invalid" 65199 "Invalid" 65198 "Invalid" 65197 "Invalid" 65196 "Invalid" 65195 "Invalid" 65194 "Invalid" 65193 "Invalid" 65192 "Invalid" 65191 "Invalid" 65190 "Invalid" 65189 "Invalid" 65188 "Invalid" 65187 "Invalid" 65186 "Invalid" 65185 "Invalid" 65184 "Invalid" 65183 "Invalid" 65182 "Invalid" 65181 "Invalid" 65180 "Invalid" 65179 "Invalid" 65178 "Invalid" 65177 "Invalid" 65176 "Invalid" 65175 "Invalid" 65174 "Invalid" 65173 "Invalid" 65172 "Invalid" 65171 "Invalid" 65170 "Invalid" 65169 "Invalid" 65168 "Invalid" 65167 "Invalid" 65166 "Invalid" 65165 "Invalid" 65164 "Invalid" 65163 "Invalid" 65162 "Invalid" 65161 "Invalid" 65160 "Invalid" 65159 "Invalid" 65158 "Invalid" 65157 "Invalid" 65156 "Invalid" 65155 "Invalid" 65154 "Invalid" 65153 "Invalid" 65152 "Invalid" 65151 "Invalid" 65150 "Invalid" 65149 "Invalid" 65148 "Invalid" 65147 "Invalid" 65146 "Invalid" 65145 "Invalid" 65144 "Invalid" 65143 "Invalid" 65142 "Invalid" 65141 "Invalid" 65140 "Invalid" 65139 "Invalid" 65138 "Invalid" 65137 "Invalid" 65136 "Invalid" 65135 "Invalid" 65134 "Invalid" 65133 "Invalid" 65132 "Invalid" 65131 "Invalid" 65130 "Invalid" 65129 "Invalid" 65128 "Invalid" 65127 "Invalid" 65126 "Invalid" 65125 "Invalid" 65124 "Invalid" 65123 "Invalid" 65122 "Invalid" 65121 "Invalid" 65120 "Invalid" 65119 "Invalid" 65118 "Invalid" 65117 "Invalid" 65116 "Invalid" 65115 "Invalid" 65114 "Invalid" 65113 "Invalid" 65112 "Invalid" 65111 "Invalid" 65110 "Invalid" 65109 "Invalid" 65108 "Invalid" 65107 "Invalid" 65106 "Invalid" 65105 "Invalid" 65104 "Invalid" 65103 "Invalid" 65102 "Invalid" 65101 "Invalid" 65100 "Invalid" 65099 "Invalid" 65098 "Invalid" 65097 "Invalid" 65096 "Invalid" 65095 "Invalid" 65094 "Invalid" 65093 "Invalid" 65092 "Invalid" 65091 "Invalid" 65090 "Invalid" 65089 "Invalid" 65088 "Invalid" 65087 "Invalid" 65086 "Invalid" 65085 "Invalid" 65084 "Invalid" 65083 "Invalid" 65082 "Invalid" 65081 "Invalid" 65080 "Invalid" 65079 "Invalid" 65078 "Invalid" 65077 "Invalid" 65076 "Invalid" 65075 "Invalid" 65074 "Invalid" 65073 "Invalid" 65072 "Invalid" 65071 "Invalid" 65070 "Invalid" 65069 "Invalid" 65068 "Invalid" 65067 "Invalid" 65066 "Invalid" 65065 "Invalid" 65064 "Invalid" 65063 "Invalid" 65062 "Invalid" 65061 "Invalid" 65060 "Invalid" 65059 "Invalid" 65058 "Invalid" 65057 "Invalid" 65056 "Invalid" 65055 "Invalid" 65054 "Invalid" 65053 "Invalid" 65052 "Invalid" 65051 "Invalid" 65050 "Invalid" 65049 "Invalid" 65048 "Invalid" 65047 "Invalid" 65046 "Invalid" 65045 "Invalid" 65044 "Invalid" 65043 "Invalid" 65042 "Invalid" 65041 "Invalid" 65040 "Invalid" 65039 "Invalid" 65038 "Invalid" 65037 "Invalid" 65036 "Invalid" 65035 "Invalid" 65034 "Invalid" 65033 "Invalid" 65032 "Invalid" 65031 "Invalid" 65030 "Invalid" 65029 "Invalid" 65028 "Invalid" 65027 "Invalid" 65026 "Invalid" 65025 "Invalid" 65024 "Invalid" 65023 "Invalid" 65022 "Invalid" 65021 "Invalid" 65020 "Invalid" 65019 "Invalid" 65018 "Invalid" 65017 "Invalid" 65016 "Invalid" 65015 "Invalid" 65014 "Invalid" 65013 "Invalid" 65012 "Invalid" 65011 "Invalid" 65010 "Invalid" 65009 "Invalid" 65008 "Invalid" 65007 "Invalid" 65006 "Invalid" 65005 "Invalid" 65004 "Invalid" 65003 "Invalid" 65002 "Invalid" 65001 "Invalid" ;
VAL_ 539 BCU_TotalChrgEgy 65535 "Invalid" 65534 "Invalid" 65533 "Invalid" 65532 "Invalid" 65531 "Invalid" 65530 "Invalid" 65529 "Invalid" 65528 "Invalid" 65527 "Invalid" 65526 "Invalid" 65525 "Invalid" 65524 "Invalid" 65523 "Invalid" 65522 "Invalid" 65521 "Invalid" 65520 "Invalid" 65519 "Invalid" 65518 "Invalid" 65517 "Invalid" 65516 "Invalid" 65515 "Invalid" 65514 "Invalid" 65513 "Invalid" 65512 "Invalid" 65511 "Invalid" 65510 "Invalid" 65509 "Invalid" 65508 "Invalid" 65507 "Invalid" 65506 "Invalid" 65505 "Invalid" 65504 "Invalid" 65503 "Invalid" 65502 "Invalid" 65501 "Invalid" 65500 "Invalid" 65499 "Invalid" 65498 "Invalid" 65497 "Invalid" 65496 "Invalid" 65495 "Invalid" 65494 "Invalid" 65493 "Invalid" 65492 "Invalid" 65491 "Invalid" 65490 "Invalid" 65489 "Invalid" 65488 "Invalid" 65487 "Invalid" 65486 "Invalid" 65485 "Invalid" 65484 "Invalid" 65483 "Invalid" 65482 "Invalid" 65481 "Invalid" 65480 "Invalid" 65479 "Invalid" 65478 "Invalid" 65477 "Invalid" 65476 "Invalid" 65475 "Invalid" 65474 "Invalid" 65473 "Invalid" 65472 "Invalid" 65471 "Invalid" 65470 "Invalid" 65469 "Invalid" 65468 "Invalid" 65467 "Invalid" 65466 "Invalid" 65465 "Invalid" 65464 "Invalid" 65463 "Invalid" 65462 "Invalid" 65461 "Invalid" 65460 "Invalid" 65459 "Invalid" 65458 "Invalid" 65457 "Invalid" 65456 "Invalid" 65455 "Invalid" 65454 "Invalid" 65453 "Invalid" 65452 "Invalid" 65451 "Invalid" 65450 "Invalid" 65449 "Invalid" 65448 "Invalid" 65447 "Invalid" 65446 "Invalid" 65445 "Invalid" 65444 "Invalid" 65443 "Invalid" 65442 "Invalid" 65441 "Invalid" 65440 "Invalid" 65439 "Invalid" 65438 "Invalid" 65437 "Invalid" 65436 "Invalid" 65435 "Invalid" 65434 "Invalid" 65433 "Invalid" 65432 "Invalid" 65431 "Invalid" 65430 "Invalid" 65429 "Invalid" 65428 "Invalid" 65427 "Invalid" 65426 "Invalid" 65425 "Invalid" 65424 "Invalid" 65423 "Invalid" 65422 "Invalid" 65421 "Invalid" 65420 "Invalid" 65419 "Invalid" 65418 "Invalid" 65417 "Invalid" 65416 "Invalid" 65415 "Invalid" 65414 "Invalid" 65413 "Invalid" 65412 "Invalid" 65411 "Invalid" 65410 "Invalid" 65409 "Invalid" 65408 "Invalid" 65407 "Invalid" 65406 "Invalid" 65405 "Invalid" 65404 "Invalid" 65403 "Invalid" 65402 "Invalid" 65401 "Invalid" 65400 "Invalid" 65399 "Invalid" 65398 "Invalid" 65397 "Invalid" 65396 "Invalid" 65395 "Invalid" 65394 "Invalid" 65393 "Invalid" 65392 "Invalid" 65391 "Invalid" 65390 "Invalid" 65389 "Invalid" 65388 "Invalid" 65387 "Invalid" 65386 "Invalid" 65385 "Invalid" 65384 "Invalid" 65383 "Invalid" 65382 "Invalid" 65381 "Invalid" 65380 "Invalid" 65379 "Invalid" 65378 "Invalid" 65377 "Invalid" 65376 "Invalid" 65375 "Invalid" 65374 "Invalid" 65373 "Invalid" 65372 "Invalid" 65371 "Invalid" 65370 "Invalid" 65369 "Invalid" 65368 "Invalid" 65367 "Invalid" 65366 "Invalid" 65365 "Invalid" 65364 "Invalid" 65363 "Invalid" 65362 "Invalid" 65361 "Invalid" 65360 "Invalid" 65359 "Invalid" 65358 "Invalid" 65357 "Invalid" 65356 "Invalid" 65355 "Invalid" 65354 "Invalid" 65353 "Invalid" 65352 "Invalid" 65351 "Invalid" 65350 "Invalid" 65349 "Invalid" 65348 "Invalid" 65347 "Invalid" 65346 "Invalid" 65345 "Invalid" 65344 "Invalid" 65343 "Invalid" 65342 "Invalid" 65341 "Invalid" 65340 "Invalid" 65339 "Invalid" 65338 "Invalid" 65337 "Invalid" 65336 "Invalid" 65335 "Invalid" 65334 "Invalid" 65333 "Invalid" 65332 "Invalid" 65331 "Invalid" 65330 "Invalid" 65329 "Invalid" 65328 "Invalid" 65327 "Invalid" 65326 "Invalid" 65325 "Invalid" 65324 "Invalid" 65323 "Invalid" 65322 "Invalid" 65321 "Invalid" 65320 "Invalid" 65319 "Invalid" 65318 "Invalid" 65317 "Invalid" 65316 "Invalid" 65315 "Invalid" 65314 "Invalid" 65313 "Invalid" 65312 "Invalid" 65311 "Invalid" 65310 "Invalid" 65309 "Invalid" 65308 "Invalid" 65307 "Invalid" 65306 "Invalid" 65305 "Invalid" 65304 "Invalid" 65303 "Invalid" 65302 "Invalid" 65301 "Invalid" 65300 "Invalid" 65299 "Invalid" 65298 "Invalid" 65297 "Invalid" 65296 "Invalid" 65295 "Invalid" 65294 "Invalid" 65293 "Invalid" 65292 "Invalid" 65291 "Invalid" 65290 "Invalid" 65289 "Invalid" 65288 "Invalid" 65287 "Invalid" 65286 "Invalid" 65285 "Invalid" 65284 "Invalid" 65283 "Invalid" 65282 "Invalid" 65281 "Invalid" 65280 "Invalid" 65279 "Invalid" 65278 "Invalid" 65277 "Invalid" 65276 "Invalid" 65275 "Invalid" 65274 "Invalid" 65273 "Invalid" 65272 "Invalid" 65271 "Invalid" 65270 "Invalid" 65269 "Invalid" 65268 "Invalid" 65267 "Invalid" 65266 "Invalid" 65265 "Invalid" 65264 "Invalid" 65263 "Invalid" 65262 "Invalid" 65261 "Invalid" 65260 "Invalid" 65259 "Invalid" 65258 "Invalid" 65257 "Invalid" 65256 "Invalid" 65255 "Invalid" 65254 "Invalid" 65253 "Invalid" 65252 "Invalid" 65251 "Invalid" 65250 "Invalid" 65249 "Invalid" 65248 "Invalid" 65247 "Invalid" 65246 "Invalid" 65245 "Invalid" 65244 "Invalid" 65243 "Invalid" 65242 "Invalid" 65241 "Invalid" 65240 "Invalid" 65239 "Invalid" 65238 "Invalid" 65237 "Invalid" 65236 "Invalid" 65235 "Invalid" 65234 "Invalid" 65233 "Invalid" 65232 "Invalid" 65231 "Invalid" 65230 "Invalid" 65229 "Invalid" 65228 "Invalid" 65227 "Invalid" 65226 "Invalid" 65225 "Invalid" 65224 "Invalid" 65223 "Invalid" 65222 "Invalid" 65221 "Invalid" 65220 "Invalid" 65219 "Invalid" 65218 "Invalid" 65217 "Invalid" 65216 "Invalid" 65215 "Invalid" 65214 "Invalid" 65213 "Invalid" 65212 "Invalid" 65211 "Invalid" 65210 "Invalid" 65209 "Invalid" 65208 "Invalid" 65207 "Invalid" 65206 "Invalid" 65205 "Invalid" 65204 "Invalid" 65203 "Invalid" 65202 "Invalid" 65201 "Invalid" 65200 "Invalid" 65199 "Invalid" 65198 "Invalid" 65197 "Invalid" 65196 "Invalid" 65195 "Invalid" 65194 "Invalid" 65193 "Invalid" 65192 "Invalid" 65191 "Invalid" 65190 "Invalid" 65189 "Invalid" 65188 "Invalid" 65187 "Invalid" 65186 "Invalid" 65185 "Invalid" 65184 "Invalid" 65183 "Invalid" 65182 "Invalid" 65181 "Invalid" 65180 "Invalid" 65179 "Invalid" 65178 "Invalid" 65177 "Invalid" 65176 "Invalid" 65175 "Invalid" 65174 "Invalid" 65173 "Invalid" 65172 "Invalid" 65171 "Invalid" 65170 "Invalid" 65169 "Invalid" 65168 "Invalid" 65167 "Invalid" 65166 "Invalid" 65165 "Invalid" 65164 "Invalid" 65163 "Invalid" 65162 "Invalid" 65161 "Invalid" 65160 "Invalid" 65159 "Invalid" 65158 "Invalid" 65157 "Invalid" 65156 "Invalid" 65155 "Invalid" 65154 "Invalid" 65153 "Invalid" 65152 "Invalid" 65151 "Invalid" 65150 "Invalid" 65149 "Invalid" 65148 "Invalid" 65147 "Invalid" 65146 "Invalid" 65145 "Invalid" 65144 "Invalid" 65143 "Invalid" 65142 "Invalid" 65141 "Invalid" 65140 "Invalid" 65139 "Invalid" 65138 "Invalid" 65137 "Invalid" 65136 "Invalid" 65135 "Invalid" 65134 "Invalid" 65133 "Invalid" 65132 "Invalid" 65131 "Invalid" 65130 "Invalid" 65129 "Invalid" 65128 "Invalid" 65127 "Invalid" 65126 "Invalid" 65125 "Invalid" 65124 "Invalid" 65123 "Invalid" 65122 "Invalid" 65121 "Invalid" 65120 "Invalid" 65119 "Invalid" 65118 "Invalid" 65117 "Invalid" 65116 "Invalid" 65115 "Invalid" 65114 "Invalid" 65113 "Invalid" 65112 "Invalid" 65111 "Invalid" 65110 "Invalid" 65109 "Invalid" 65108 "Invalid" 65107 "Invalid" 65106 "Invalid" 65105 "Invalid" 65104 "Invalid" 65103 "Invalid" 65102 "Invalid" 65101 "Invalid" 65100 "Invalid" 65099 "Invalid" 65098 "Invalid" 65097 "Invalid" 65096 "Invalid" 65095 "Invalid" 65094 "Invalid" 65093 "Invalid" 65092 "Invalid" 65091 "Invalid" 65090 "Invalid" 65089 "Invalid" 65088 "Invalid" 65087 "Invalid" 65086 "Invalid" 65085 "Invalid" 65084 "Invalid" 65083 "Invalid" 65082 "Invalid" 65081 "Invalid" 65080 "Invalid" 65079 "Invalid" 65078 "Invalid" 65077 "Invalid" 65076 "Invalid" 65075 "Invalid" 65074 "Invalid" 65073 "Invalid" 65072 "Invalid" 65071 "Invalid" 65070 "Invalid" 65069 "Invalid" 65068 "Invalid" 65067 "Invalid" 65066 "Invalid" 65065 "Invalid" 65064 "Invalid" 65063 "Invalid" 65062 "Invalid" 65061 "Invalid" 65060 "Invalid" 65059 "Invalid" 65058 "Invalid" 65057 "Invalid" 65056 "Invalid" 65055 "Invalid" 65054 "Invalid" 65053 "Invalid" 65052 "Invalid" 65051 "Invalid" 65050 "Invalid" 65049 "Invalid" 65048 "Invalid" 65047 "Invalid" 65046 "Invalid" 65045 "Invalid" 65044 "Invalid" 65043 "Invalid" 65042 "Invalid" 65041 "Invalid" 65040 "Invalid" 65039 "Invalid" 65038 "Invalid" 65037 "Invalid" 65036 "Invalid" 65035 "Invalid" 65034 "Invalid" 65033 "Invalid" 65032 "Invalid" 65031 "Invalid" 65030 "Invalid" 65029 "Invalid" 65028 "Invalid" 65027 "Invalid" 65026 "Invalid" 65025 "Invalid" 65024 "Invalid" 65023 "Invalid" 65022 "Invalid" 65021 "Invalid" 65020 "Invalid" 65019 "Invalid" 65018 "Invalid" 65017 "Invalid" 65016 "Invalid" 65015 "Invalid" 65014 "Invalid" 65013 "Invalid" 65012 "Invalid" 65011 "Invalid" 65010 "Invalid" 65009 "Invalid" 65008 "Invalid" 65007 "Invalid" 65006 "Invalid" 65005 "Invalid" 65004 "Invalid" 65003 "Invalid" 65002 "Invalid" 65001 "Invalid" ;
VAL_ 544 BCU_MaxVltBatt_SubSysNr_RM 3 "Invalid" ;
VAL_ 545 BCU_BattCellTotalNr_RM 255 "Invalid" 254 "Invalid" 253 "Invalid" 252 "Invalid" 251 "Invalid" 250 "Invalid" 249 "Invalid" 248 "Invalid" 247 "Invalid" 246 "Invalid" 245 "Invalid" 244 "Invalid" 243 "Invalid" 242 "Invalid" 241 "Invalid" 240 "Invalid" 239 "Invalid" 238 "Invalid" 237 "Invalid" 236 "Invalid" 235 "Invalid" 234 "Invalid" 233 "Invalid" 232 "Invalid" 231 "Invalid" 230 "Invalid" 229 "Invalid" 228 "Invalid" 227 "Invalid" 226 "Invalid" 225 "Invalid" 224 "Invalid" 223 "Invalid" 222 "Invalid" 221 "Invalid" 220 "Invalid" 219 "Invalid" 218 "Invalid" 217 "Invalid" 216 "Invalid" 215 "Invalid" 214 "Invalid" 213 "Invalid" 212 "Invalid" 211 "Invalid" 210 "Invalid" 209 "Invalid" 208 "Invalid" 207 "Invalid" 206 "Invalid" 205 "Invalid" 204 "Invalid" 203 "Invalid" 202 "Invalid" 201 "Invalid" 200 "Invalid" 199 "Invalid" 198 "Invalid" 197 "Invalid" 196 "Invalid" 195 "Invalid" 194 "Invalid" 193 "Invalid" 192 "Invalid" 191 "Invalid" 190 "Invalid" 189 "Invalid" 188 "Invalid" 187 "Invalid" 186 "Invalid" 185 "Invalid" 184 "Invalid" 183 "Invalid" 182 "Invalid" 181 "Invalid" 180 "Invalid" 179 "Invalid" 178 "Invalid" 177 "Invalid" 176 "Invalid" 175 "Invalid" 174 "Invalid" 173 "Invalid" 172 "Invalid" 171 "Invalid" 170 "Invalid" 169 "Invalid" 168 "Invalid" 167 "Invalid" 166 "Invalid" 165 "Invalid" 164 "Invalid" 163 "Invalid" 162 "Invalid" 161 "Invalid" ;
VAL_ 545 BCU_TmpProbeQuantity_RM 255 "Invalid" 254 "Invalid" 253 "Invalid" 252 "Invalid" 251 "Invalid" 250 "Invalid" 249 "Invalid" 248 "Invalid" 247 "Invalid" 246 "Invalid" 245 "Invalid" 244 "Invalid" 243 "Invalid" 242 "Invalid" 241 "Invalid" 240 "Invalid" 239 "Invalid" 238 "Invalid" 237 "Invalid" 236 "Invalid" 235 "Invalid" 234 "Invalid" 233 "Invalid" 232 "Invalid" 231 "Invalid" 230 "Invalid" 229 "Invalid" 228 "Invalid" 227 "Invalid" 226 "Invalid" 225 "Invalid" 224 "Invalid" 223 "Invalid" 222 "Invalid" 221 "Invalid" 220 "Invalid" 219 "Invalid" 218 "Invalid" 217 "Invalid" 216 "Invalid" 215 "Invalid" 214 "Invalid" 213 "Invalid" 212 "Invalid" 211 "Invalid" 210 "Invalid" 209 "Invalid" 208 "Invalid" 207 "Invalid" 206 "Invalid" 205 "Invalid" 204 "Invalid" 203 "Invalid" 202 "Invalid" 201 "Invalid" 200 "Invalid" 199 "Invalid" 198 "Invalid" 197 "Invalid" 196 "Invalid" 195 "Invalid" 194 "Invalid" 193 "Invalid" 192 "Invalid" 191 "Invalid" 190 "Invalid" 189 "Invalid" 188 "Invalid" 187 "Invalid" 186 "Invalid" 185 "Invalid" 184 "Invalid" 183 "Invalid" 182 "Invalid" 181 "Invalid" 180 "Invalid" 179 "Invalid" 178 "Invalid" 177 "Invalid" 176 "Invalid" 175 "Invalid" 174 "Invalid" 173 "Invalid" 172 "Invalid" 171 "Invalid" 170 "Invalid" 169 "Invalid" 168 "Invalid" 167 "Invalid" 166 "Invalid" 165 "Invalid" 164 "Invalid" 163 "Invalid" 162 "Invalid" 161 "Invalid" ;
VAL_ 545 BCU_BalnFlg023_RM 1 "Balance Closed" 0 "Balance Open" ;
VAL_ 545 BCU_BalnFlg024_RM 1 "Balance Closed" 0 "Balance Open" ;
VAL_ 545 BCU_BalnFlg025_RM 1 "Balance Closed" 0 "Balance Open" ;
VAL_ 545 BCU_BalnFlg026_RM 1 "Balance Closed" 0 "Balance Open" ;
VAL_ 545 BCU_BalnFlg027_RM 1 "Balance Closed" 0 "Balance Open" ;
VAL_ 545 BCU_BalnFlg028_RM 1 "Balance Closed" 0 "Balance Open" ;
VAL_ 545 BCU_BalnFlg029_RM 1 "Balance Closed" 0 "Balance Open" ;
VAL_ 545 BCU_BalnFlg030_RM 1 "Balance Closed" 0 "Balance Open" ;
VAL_ 545 BCU_BalnFlg031_RM 1 "Balance Closed" 0 "Balance Open" ;
VAL_ 545 BCU_BalnFlg032_RM 1 "Balance Closed" 0 "Balance Open" ;
VAL_ 545 BCU_BalnFlg033_RM 1 "Balance Closed" 0 "Balance Open" ;
VAL_ 545 BCU_BalnFlg034_RM 1 "Balance Closed" 0 "Balance Open" ;
VAL_ 545 BCU_BalnFlg035_RM 1 "Balance Closed" 0 "Balance Open" ;
VAL_ 545 BCU_BalnFlg036_RM 1 "Balance Closed" 0 "Balance Open" ;
VAL_ 545 BCU_BalnFlg037_RM 1 "Balance Closed" 0 "Balance Open" ;
VAL_ 545 BCU_BalnFlg038_RM 1 "Balance Closed" 0 "Balance Open" ;
VAL_ 545 BCU_BalnFlg039_RM 1 "Balance Closed" 0 "Balance Open" ;
VAL_ 545 BCU_BalnFlg040_RM 1 "Balance Closed" 0 "Balance Open" ;
VAL_ 545 BCU_BalnFlg041_RM 1 "Balance Closed" 0 "Balance Open" ;
VAL_ 545 BCU_BalnFlg042_RM 1 "Balance Closed" 0 "Balance Open" ;
VAL_ 545 BCU_BalnFlg043_RM 1 "Balance Closed" 0 "Balance Open" ;
VAL_ 545 BCU_BalnFlg044_RM 1 "Balance Closed" 0 "Balance Open" ;
VAL_ 545 BCU_BalnFlg045_RM 1 "Balance Closed" 0 "Balance Open" ;
VAL_ 545 BCU_BalnFlg046_RM 1 "Balance Closed" 0 "Balance Open" ;
VAL_ 545 BCU_BalnFlg047_RM 1 "Balance Closed" 0 "Balance Open" ;
VAL_ 545 BCU_BalnFlg048_RM 1 "Balance Closed" 0 "Balance Open" ;
VAL_ 545 BCU_BalnFlg049_RM 1 "Balance Closed" 0 "Balance Open" ;
VAL_ 545 BCU_BalnFlg050_RM 1 "Balance Closed" 0 "Balance Open" ;
VAL_ 545 BCU_BalnFlg051_RM 1 "Balance Closed" 0 "Balance Open" ;
VAL_ 545 BCU_BalnFlg052_RM 1 "Balance Closed" 0 "Balance Open" ;
VAL_ 545 BCU_BalnFlg053_RM 1 "Balance Closed" 0 "Balance Open" ;
VAL_ 545 BCU_BalnFlg054_RM 1 "Balance Closed" 0 "Balance Open" ;
VAL_ 545 BCU_BalnFlg055_RM 1 "Balance Closed" 0 "Balance Open" ;
VAL_ 545 BCU_BalnFlg056_RM 1 "Balance Closed" 0 "Balance Open" ;
VAL_ 545 BCU_BalnFlg057_RM 1 "Balance Closed" 0 "Balance Open" ;
VAL_ 545 BCU_BalnFlg058_RM 1 "Balance Closed" 0 "Balance Open" ;
VAL_ 545 BCU_BalnFlg059_RM 1 "Balance Closed" 0 "Balance Open" ;
VAL_ 545 BCU_BalnFlg060_RM 1 "Balance Closed" 0 "Balance Open" ;
VAL_ 545 BCU_BalnFlg061_RM 1 "Balance Closed" 0 "Balance Open" ;
VAL_ 545 BCU_BalnFlg062_RM 1 "Balance Closed" 0 "Balance Open" ;
VAL_ 545 BCU_BalnFlg063_RM 1 "Balance Closed" 0 "Balance Open" ;
VAL_ 545 BCU_BalnFlg064_RM 1 "Balance Closed" 0 "Balance Open" ;
VAL_ 545 BCU_BalnFlg065_RM 1 "Balance Closed" 0 "Balance Open" ;
VAL_ 545 BCU_BalnFlg066_RM 1 "Balance Closed" 0 "Balance Open" ;
VAL_ 545 BCU_BalnFlg067_RM 1 "Balance Closed" 0 "Balance Open" ;
VAL_ 545 BCU_BalnFlg068_RM 1 "Balance Closed" 0 "Balance Open" ;
VAL_ 545 BCU_BalnFlg069_RM 1 "Balance Closed" 0 "Balance Open" ;
VAL_ 545 BCU_BalnFlg070_RM 1 "Balance Closed" 0 "Balance Open" ;
